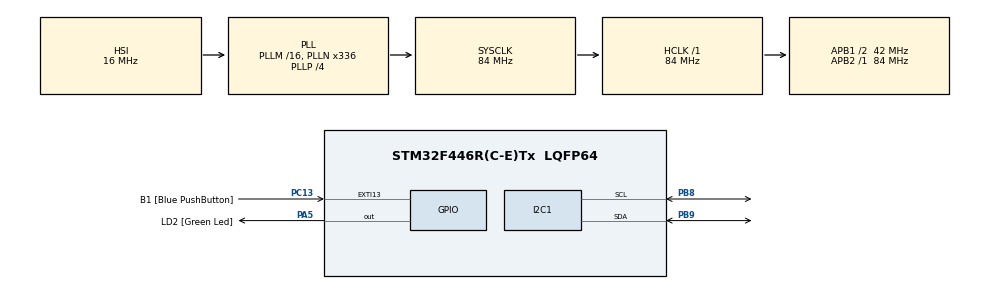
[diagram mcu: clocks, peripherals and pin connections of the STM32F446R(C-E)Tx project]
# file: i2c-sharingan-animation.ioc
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I2C1.I2C_Mode=I2C_Fast
Mcu.Family=STM32F4
Mcu.Name=STM32F446R(C-E)Tx
Mcu.Package=LQFP64
NVIC.PriorityGroup=NVIC_PRIORITYGROUP_0
PA13.GPIO_Label=TMS
PA13.Signal=SYS_JTMS-SWDIO
PA14.GPIO_Label=TCK
PA14.Signal=SYS_JTCK-SWCLK
PA2.GPIO_Label=USART_TX
PA2.Signal=USART2_TX
PA3.GPIO_Label=USART_RX
PA3.Signal=USART2_RX
PA5.GPIO_Label=LD2 [Green Led]
PA5.Signal=GPIO_Output
PB3.GPIO_Label=SWO
PB3.Signal=SYS_JTDO-SWO
PB8.Mode=I2C
PB8.Signal=I2C1_SCL
PB9.Mode=I2C
PB9.Signal=I2C1_SDA
PC13.GPIO_Label=B1 [Blue PushButton]
PC13.GPIO_ModeDefaultEXTI=GPIO_MODE_IT_FALLING
PC13.Signal=GPXTI13
PC14-OSC32_IN.Signal=RCC_OSC32_IN
PC15-OSC32_OUT.Signal=RCC_OSC32_OUT
PH0-OSC_IN.Signal=RCC_OSC_IN
PH1-OSC_OUT.Signal=RCC_OSC_OUT
ProjectManager.HeapSize=0x200
ProjectManager.StackSize=0x400
ProjectManager.TargetToolchain=STM32CubeIDE
RCC.AHBFreq_Value=84000000
RCC.APB1CLKDivider=RCC_HCLK_DIV2
RCC.APB1Freq_Value=42000000
RCC.APB1TimFreq_Value=84000000
RCC.APB2Freq_Value=84000000
RCC.APB2TimFreq_Value=84000000
RCC.CortexFreq_Value=84000000
RCC.FLatency-AdvancedSettings=FLASH_LATENCY_2
RCC.HCLKFreq_Value=84000000
RCC.HSE_VALUE=8000000
RCC.HSI_VALUE=16000000
RCC.LSE_VALUE=32768
RCC.PLLN=336
RCC.PLLP=RCC_PLLP_DIV4
RCC.SYSCLKFreq_VALUE=84000000
RCC.SYSCLKSource=RCC_SYSCLKSOURCE_PLLCLK
RCC.USBFreq_Value=168000000
RCC.VCOOutputFreq_Value=336000000
board=NUCLEO-F446RE

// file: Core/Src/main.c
/* USER CODE BEGIN Header */
/**
  ******************************************************************************
  * @file           : main.c
  * @brief          : Main program body
  ******************************************************************************
  * @attention
  *
  * Copyright (c) 2024 STMicroelectronics.
  * All rights reserved.
  *
  * This software is licensed under terms that can be found in the LICENSE file
  * in the root directory of this software component.
  * If no LICENSE file comes with this software, it is provided AS-IS.
  *
  ******************************************************************************
  */
/* USER CODE END Header */
#include "main.h"
#include "ssd1306.h"

I2C_HandleTypeDef hi2c1;

void SystemClock_Config(void);
static void MX_GPIO_Init(void);
static void MX_I2C1_Init(void);

int main(void)
{

  /* USER CODE BEGIN 1 */
	// 'frame1', 128x64px
	const unsigned char epd_bitmap_frame1 []  = {
		0x00, 0x00, 0x00, 0x00, 0x1f, 0xff, 0xf0, 0x00, 0xff, 0xff, 0xf8, 0x00, 0x00, 0x7f, 0xff, 0x80,
		0x00, 0x00, 0x00, 0x00, 0x1f, 0xff, 0xf0, 0x01, 0xff, 0xff, 0xf8, 0x00, 0x00, 0x7f, 0xff, 0xc0,
		0x00, 0x00, 0x00, 0x00, 0x1f, 0xff, 0xf8, 0x01, 0xff, 0xff, 0xfc, 0x00, 0x00, 0x7f, 0xff, 0xc0,
		0x00, 0x00, 0x00, 0x00, 0x1f, 0xff, 0xf8, 0x01, 0xff, 0xff, 0xfc, 0x00, 0x00, 0x7f, 0xff, 0xc0,
		0x00, 0x00, 0x00, 0x00, 0x1f, 0xff, 0xf8, 0x01, 0xff, 0xff, 0xfc, 0x00, 0x00, 0x7f, 0xff, 0xc0,
		0x00, 0x00, 0x00, 0x00, 0x1f, 0xff, 0xf8, 0x03, 0xff, 0xff, 0xfc, 0x00, 0x00, 0x7f, 0xff, 0xc0,
		0x00, 0x00, 0x00, 0x00, 0x3f, 0xff, 0xf8, 0x03, 0xff, 0xff, 0xfe, 0x00, 0x00, 0xff, 0xff, 0xc0,
		0x00, 0x00, 0x00, 0x00, 0x3f, 0xff, 0xf8, 0x03, 0xff, 0xff, 0xfe, 0x00, 0x00, 0xff, 0xff, 0xc0,
		0x00, 0x00, 0x00, 0x00, 0x3f, 0xfc, 0x78, 0x03, 0xff, 0xff, 0xfe, 0x00, 0x00, 0xff, 0xff, 0xe0,
		0x00, 0x00, 0x00, 0x00, 0x3f, 0xff, 0xc0, 0x07, 0xff, 0xff, 0xfe, 0x00, 0x00, 0xff, 0xff, 0xe0,
		0x00, 0x00, 0x00, 0x00, 0x3f, 0xff, 0xf8, 0x07, 0xff, 0xff, 0xff, 0x00, 0x00, 0xff, 0xff, 0xe0,
		0x00, 0x00, 0x00, 0x00, 0x3f, 0xff, 0xfc, 0x03, 0xff, 0xff, 0xff, 0x00, 0x00, 0xff, 0xff, 0xe0,
		0x00, 0x00, 0x00, 0x00, 0x3f, 0xff, 0xfc, 0x00, 0x7f, 0xff, 0xff, 0x00, 0x00, 0xff, 0xff, 0xe0,
		0x00, 0x00, 0x00, 0x00, 0x7f, 0xff, 0xfc, 0x0e, 0x07, 0xff, 0xff, 0x80, 0x00, 0xff, 0xff, 0xe0,
		0x00, 0x00, 0x00, 0x00, 0x7f, 0xff, 0xfc, 0x0f, 0xc0, 0xff, 0xff, 0x80, 0x00, 0xff, 0xff, 0xf0,
		0x00, 0x00, 0x00, 0x00, 0x7f, 0xff, 0xfc, 0x0f, 0xf0, 0x1f, 0xff, 0x80, 0x00, 0xff, 0xff, 0xf0,
		0x00, 0x00, 0x00, 0x00, 0x7f, 0xff, 0xfc, 0x1f, 0xfe, 0x01, 0xff, 0xc0, 0x00, 0xff, 0xff, 0xf0,
		0x00, 0x00, 0x00, 0x00, 0x7f, 0xf8, 0x00, 0x0f, 0xff, 0xe0, 0x3f, 0xc0, 0x00, 0xff, 0xff, 0xf0,
		0x00, 0x00, 0x00, 0x00, 0x7c, 0x00, 0x00, 0x00, 0x3f, 0xfc, 0x03, 0xc0, 0x00, 0xff, 0xff, 0xf0,
		0x00, 0x00, 0x00, 0x00, 0x40, 0x03, 0xfc, 0x00, 0x03, 0xff, 0x00, 0x00, 0x00, 0xff, 0xff, 0xf0,
		0x00, 0x00, 0x00, 0x00, 0x00, 0xff, 0xf8, 0x00, 0x00, 0x7f, 0xe0, 0x00, 0x00, 0xff, 0xff, 0xf0,
		0x00, 0x00, 0x00, 0x00, 0x1f, 0xff, 0xf8, 0x00, 0x00, 0x1f, 0xfe, 0x00, 0x01, 0xff, 0xff, 0xf8,
		0x00, 0x00, 0x00, 0x00, 0x7f, 0xff, 0xf0, 0x00, 0x00, 0x07, 0xff, 0xc0, 0x01, 0xff, 0xff, 0xf8,
		0x00, 0x00, 0x00, 0x00, 0x7f, 0xff, 0xe0, 0x00, 0x00, 0x01, 0xff, 0xf0, 0x00, 0x0f, 0xff, 0xf8,
		0x00, 0x00, 0x00, 0x00, 0x7f, 0xff, 0xc0, 0x00, 0x00, 0x00, 0x7f, 0xf0, 0x00, 0x1f, 0xff, 0xf8,
		0x00, 0x00, 0x00, 0x00, 0xff, 0xff, 0xc0, 0x00, 0x00, 0x03, 0x1f, 0xf0, 0x00, 0x7f, 0xff, 0xf8,
		0x00, 0x00, 0x00, 0x00, 0xff, 0xff, 0xc0, 0x00, 0x00, 0x01, 0xcf, 0xf8, 0x01, 0xff, 0xff, 0xf8,
		0x00, 0x00, 0x00, 0x00, 0xff, 0xff, 0x80, 0x00, 0x00, 0x01, 0xe7, 0xf8, 0x01, 0xff, 0xff, 0xfc,
		0x00, 0x00, 0x00, 0x00, 0x7f, 0xff, 0x80, 0x00, 0x00, 0x01, 0xf9, 0xfc, 0x01, 0xff, 0xff, 0xfc,
		0x00, 0x00, 0x00, 0x00, 0x7f, 0xff, 0x80, 0x00, 0x00, 0x01, 0xfc, 0xfc, 0x01, 0xff, 0xff, 0xfc,
		0x00, 0x00, 0x00, 0x00, 0xff, 0xff, 0x80, 0x00, 0x00, 0x01, 0xfe, 0x7c, 0x01, 0xff, 0xff, 0xfc,
		0x00, 0x00, 0x00, 0x00, 0xff, 0xff, 0x80, 0x00, 0x00, 0x01, 0xff, 0x3e, 0x01, 0xff, 0xff, 0xfc,
		0x00, 0x00, 0x00, 0x00, 0xff, 0xff, 0x80, 0x00, 0x00, 0x01, 0xff, 0x9e, 0x01, 0xff, 0xff, 0xfe,
		0x00, 0x00, 0x00, 0x00, 0xff, 0xff, 0x80, 0x00, 0x00, 0x01, 0xff, 0xce, 0x01, 0xff, 0xff, 0xfe,
		0x00, 0x00, 0x00, 0x01, 0xff, 0xff, 0xc0, 0x00, 0x00, 0x7f, 0xff, 0xef, 0x01, 0xff, 0xff, 0xfe,
		0x00, 0x00, 0x00, 0x01, 0xff, 0xff, 0xc0, 0x00, 0x00, 0x07, 0xff, 0xe7, 0x01, 0xff, 0xff, 0xfe,
		0x00, 0x00, 0x00, 0x01, 0xff, 0xff, 0xe0, 0x00, 0x00, 0x07, 0xff, 0xf7, 0x83, 0xff, 0xff, 0xff,
		0x00, 0x00, 0x00, 0x01, 0xff, 0xff, 0xe0, 0x00, 0x00, 0x07, 0xff, 0xfb, 0x83, 0xff, 0xff, 0xff,
		0x00, 0x00, 0x00, 0x01, 0xff, 0xff, 0xf0, 0x00, 0x00, 0x0f, 0xff, 0xff, 0x83, 0xff, 0xff, 0xff,
		0x00, 0x00, 0x00, 0x01, 0xfe, 0xff, 0xf8, 0x00, 0x00, 0x1f, 0xff, 0xff, 0xc3, 0xff, 0xff, 0xff,
		0x00, 0x00, 0x00, 0x01, 0xfe, 0x7f, 0xfc, 0x00, 0x00, 0x3f, 0xff, 0xff, 0xc3, 0xff, 0xff, 0xff,
		0x00, 0x00, 0x00, 0x01, 0xff, 0x3f, 0xfe, 0x00, 0x00, 0x7f, 0xff, 0xff, 0xc3, 0xff, 0xff, 0xff,
		0x00, 0x00, 0x00, 0x01, 0xff, 0x8f, 0xff, 0x80, 0x00, 0xff, 0xff, 0xff, 0xe3, 0xff, 0xff, 0xff,
		0x00, 0x00, 0x00, 0x01, 0xff, 0xc0, 0x00, 0x00, 0x07, 0xff, 0xff, 0xff, 0xe3, 0xff, 0xff, 0xff,
		0x00, 0x00, 0x00, 0x01, 0xff, 0xff, 0xff, 0xff, 0xff, 0xff, 0xff, 0xff, 0xf3, 0xff, 0xff, 0xff,
		0x00, 0x00, 0x00, 0x01, 0xff, 0xff, 0xff, 0xff, 0xff, 0xff, 0xff, 0xff, 0xf3, 0xff, 0xff, 0xff,
		0x00, 0x00, 0x00, 0x01, 0xff, 0xff, 0xff, 0xff, 0xff, 0xff, 0xff, 0xff, 0xfb, 0xff, 0xff, 0xff,
		0x00, 0x00, 0x00, 0x01, 0xff, 0xff, 0xff, 0xff, 0xff, 0xff, 0xff, 0xff, 0xfb, 0xff, 0xff, 0xff,
		0x00, 0x00, 0x00, 0x01, 0xff, 0xff, 0xff, 0xff, 0xff, 0xff, 0xff, 0xff, 0xff, 0xff, 0xff, 0xff,
		0x00, 0x00, 0x00, 0x01, 0xff, 0xff, 0xff, 0xff, 0xff, 0xff, 0xff, 0xff, 0xff, 0xff, 0xff, 0xff,
		0x00, 0x00, 0x00, 0x01, 0xff, 0xff, 0xff, 0xff, 0xff, 0xff, 0xff, 0xff, 0xff, 0xff, 0xff, 0xff,
		0x00, 0x00, 0x00, 0x01, 0xff, 0xff, 0xff, 0xff, 0xff, 0xff, 0xff, 0xff, 0xff, 0xff, 0xff, 0xff,
		0x00, 0x00, 0x00, 0x01, 0xff, 0xff, 0xff, 0xff, 0xff, 0xff, 0xff, 0xff, 0xff, 0xff, 0xff, 0xff,
		0x00, 0x00, 0x00, 0x01, 0xff, 0xff, 0xff, 0xff, 0xff, 0xff, 0xff, 0xff, 0xff, 0xff, 0xff, 0xff,
		0x00, 0x00, 0x00, 0x01, 0xff, 0xff, 0xff, 0xff, 0xff, 0xff, 0xff, 0xff, 0xff, 0xff, 0xff, 0xff,
		0x00, 0x00, 0x00, 0x01, 0xff, 0xff, 0xff, 0xff, 0xff, 0xff, 0xff, 0xff, 0xff, 0xff, 0xff, 0xff,
		0x00, 0x00, 0x00, 0x01, 0xff, 0xff, 0xff, 0xff, 0xff, 0xff, 0xff, 0xff, 0xff, 0xff, 0xff, 0xff,
		0x00, 0x00, 0x00, 0x01, 0xff, 0xff, 0xff, 0xff, 0xff, 0xff, 0xff, 0xff, 0xff, 0xff, 0xff, 0xff,
		0x00, 0x00, 0x00, 0x01, 0xff, 0xff, 0xff, 0xff, 0xff, 0xff, 0xff, 0xff, 0xff, 0xff, 0xff, 0xff,
		0x00, 0x00, 0x00, 0x01, 0xff, 0xff, 0xff, 0xff, 0xff, 0xff, 0xff, 0xff, 0xff, 0xff, 0xff, 0xff,
		0x00, 0x00, 0x00, 0x01, 0xff, 0xff, 0xff, 0xff, 0xff, 0xff, 0xff, 0xff, 0xff, 0xff, 0xff, 0xff,
		0x00, 0x00, 0x00, 0x01, 0xff, 0xff, 0xff, 0xff, 0xff, 0xff, 0xff, 0xff, 0xff, 0xff, 0xff, 0xff,
		0x00, 0x00, 0x00, 0x01, 0xff, 0xff, 0xff, 0xff, 0xff, 0xff, 0xff, 0xff, 0xff, 0xff, 0xff, 0xff,
		0x00, 0x00, 0x00, 0x01, 0xff, 0xff, 0xff, 0xff, 0xff, 0xff, 0xff, 0xff, 0xff, 0xff, 0xff, 0xff
	};
	// 'frame2', 128x64px
	const unsigned char epd_bitmap_frame2 []  = {
		0x00, 0x00, 0x00, 0x00, 0x1f, 0xff, 0xf8, 0x00, 0xff, 0xff, 0xfc, 0x00, 0x00, 0x1f, 0xff, 0xf0,
		0x00, 0x00, 0x00, 0x00, 0x1f, 0xff, 0xf8, 0x00, 0xff, 0xff, 0xfc, 0x00, 0x00, 0x1f, 0xff, 0xf0,
		0x00, 0x00, 0x00, 0x00, 0x3f, 0xff, 0xf8, 0x00, 0xff, 0xff, 0xfe, 0x00, 0x00, 0x3f, 0xff, 0xf0,
		0x00, 0x00, 0x00, 0x00, 0x3f, 0xff, 0xf8, 0x01, 0xff, 0xff, 0xfe, 0x00, 0x00, 0x3f, 0xff, 0xf0,
		0x00, 0x00, 0x00, 0x00, 0x3f, 0xff, 0xf8, 0x01, 0xff, 0xff, 0xfe, 0x00, 0x00, 0x3f, 0xff, 0xf0,
		0x00, 0x00, 0x00, 0x00, 0x3f, 0xff, 0xf8, 0x01, 0xff, 0xff, 0xff, 0x00, 0x00, 0x3f, 0xff, 0xf8,
		0x00, 0x00, 0x00, 0x00, 0x3f, 0xff, 0xf8, 0x03, 0xff, 0xff, 0xff, 0x00, 0x00, 0x3f, 0xff, 0xf8,
		0x00, 0x00, 0x00, 0x00, 0x3f, 0xff, 0xf8, 0x03, 0xff, 0xff, 0xff, 0x00, 0x00, 0x3f, 0xff, 0xf8,
		0x00, 0x00, 0x00, 0x00, 0x3f, 0xff, 0xf8, 0x03, 0xff, 0xff, 0xff, 0x80, 0x00, 0x3f, 0xff, 0xf8,
		0x00, 0x00, 0x00, 0x00, 0x3f, 0xfc, 0xf8, 0x03, 0xff, 0xff, 0xff, 0x80, 0x00, 0x3f, 0xff, 0xf8,
		0x00, 0x00, 0x00, 0x00, 0x7f, 0xff, 0x80, 0x07, 0xff, 0xff, 0xff, 0x80, 0x00, 0x3f, 0xff, 0xf8,
		0x00, 0x00, 0x00, 0x00, 0x7f, 0xff, 0xf8, 0x07, 0xff, 0xff, 0xff, 0xc0, 0x00, 0x3f, 0xff, 0xf8,
		0x00, 0x00, 0x00, 0x00, 0x7f, 0xff, 0xfc, 0x07, 0xff, 0xff, 0xff, 0xc0, 0x00, 0x3f, 0xff, 0xfc,
		0x00, 0x00, 0x00, 0x00, 0x7f, 0xff, 0xfc, 0x00, 0x7f, 0xff, 0xff, 0xc0, 0x00, 0x3f, 0xff, 0xfc,
		0x00, 0x00, 0x00, 0x00, 0x7f, 0xff, 0xfc, 0x0c, 0x0f, 0xff, 0xff, 0xc0, 0x00, 0x3f, 0xff, 0xfc,
		0x00, 0x00, 0x00, 0x00, 0x7f, 0xff, 0xfc, 0x0f, 0x80, 0xff, 0xff, 0xe0, 0x00, 0x7f, 0xff, 0xfc,
		0x00, 0x00, 0x00, 0x00, 0x7f, 0xff, 0xfc, 0x0f, 0xf0, 0x1f, 0xff, 0xe0, 0x00, 0x7f, 0xff, 0xfc,
		0x00, 0x00, 0x00, 0x00, 0xff, 0xff, 0xfc, 0x1f, 0xfe, 0x03, 0xff, 0xe0, 0x00, 0x7f, 0xff, 0xfe,
		0x00, 0x00, 0x00, 0x00, 0xff, 0xf0, 0x00, 0x03, 0xff, 0xc0, 0x7f, 0xf0, 0x00, 0x7f, 0xff, 0xfe,
		0x00, 0x00, 0x00, 0x00, 0xf8, 0x00, 0x00, 0x00, 0x0f, 0xf8, 0x07, 0xf0, 0x00, 0x7f, 0xff, 0xfe,
		0x00, 0x00, 0x00, 0x00, 0x00, 0x07, 0xf8, 0x00, 0x01, 0xff, 0x00, 0xf8, 0x00, 0x7f, 0xff, 0xfe,
		0x00, 0x00, 0x00, 0x00, 0x01, 0xff, 0xf0, 0x00, 0x00, 0x3f, 0xc0, 0x00, 0x00, 0x7f, 0xff, 0xfe,
		0x00, 0x00, 0x00, 0x00, 0x3f, 0xff, 0xf0, 0x00, 0x00, 0x07, 0xfc, 0x00, 0x00, 0x7f, 0xff, 0xfe,
		0x00, 0x00, 0x00, 0x00, 0xff, 0xff, 0xe0, 0x00, 0x00, 0x01, 0xff, 0x80, 0x00, 0x7f, 0xff, 0xff,
		0x00, 0x00, 0x00, 0x00, 0xff, 0xff, 0xc0, 0x00, 0x00, 0x00, 0x7f, 0xf0, 0x00, 0x7f, 0xff, 0xff,
		0x00, 0x00, 0x00, 0x00, 0xff, 0xff, 0xc0, 0x00, 0x00, 0x00, 0x3f, 0xfc, 0x00, 0x0f, 0xff, 0xff,
		0x00, 0x00, 0x00, 0x00, 0xff, 0xff, 0xc0, 0x00, 0x00, 0x01, 0x8f, 0xfc, 0x00, 0x1f, 0xff, 0xff,
		0x00, 0x00, 0x00, 0x00, 0xff, 0xff, 0x80, 0x00, 0x00, 0x00, 0xe7, 0xfe, 0x00, 0x7f, 0xff, 0xff,
		0x00, 0x00, 0x00, 0x00, 0x7f, 0xff, 0x80, 0x00, 0x00, 0x00, 0xf1, 0xfe, 0x00, 0x7f, 0xff, 0xff,
		0x00, 0x00, 0x00, 0x01, 0x7f, 0xff, 0x80, 0x00, 0x00, 0x00, 0xf8, 0xfe, 0x00, 0x7f, 0xff, 0xff,
		0x00, 0x00, 0x00, 0x01, 0xff, 0xff, 0x80, 0x00, 0x00, 0x00, 0xfe, 0x7f, 0x00, 0x7f, 0xff, 0xff,
		0x00, 0x00, 0x00, 0x01, 0xff, 0xff, 0x80, 0x00, 0x00, 0x00, 0xff, 0x3f, 0x00, 0x7f, 0xff, 0xff,
		0x00, 0x00, 0x00, 0x01, 0xff, 0xff, 0x80, 0x00, 0x00, 0x00, 0xff, 0x9f, 0x80, 0x7f, 0xff, 0xff,
		0x00, 0x00, 0x00, 0x01, 0xff, 0xff, 0x80, 0x00, 0x00, 0x00, 0xff, 0xcf, 0x80, 0x7f, 0xff, 0xff,
		0x00, 0x00, 0x00, 0x01, 0xff, 0xff, 0xc0, 0x00, 0x00, 0x01, 0xff, 0xe7, 0x80, 0xff, 0xff, 0xff,
		0x00, 0x00, 0x00, 0x01, 0xff, 0xff, 0xc0, 0x00, 0x01, 0xff, 0xff, 0xf7, 0xc0, 0xff, 0xff, 0xff,
		0x00, 0x00, 0x00, 0x01, 0xff, 0xff, 0xe0, 0x00, 0x00, 0x03, 0xff, 0xff, 0xc0, 0xff, 0xff, 0xff,
		0x00, 0x00, 0x00, 0x03, 0xff, 0xff, 0xe0, 0x00, 0x00, 0x03, 0xff, 0xfb, 0xe0, 0xff, 0xff, 0xff,
		0x00, 0x00, 0x00, 0x03, 0xfd, 0xff, 0xf0, 0x00, 0x00, 0x07, 0xff, 0xff, 0xe0, 0xff, 0xff, 0xff,
		0x00, 0x00, 0x00, 0x03, 0xfe, 0xff, 0xf8, 0x00, 0x00, 0x0f, 0xff, 0xff, 0xe0, 0xff, 0xff, 0xff,
		0x00, 0x00, 0x00, 0x03, 0xfe, 0x7f, 0xfc, 0x00, 0x00, 0x1f, 0xff, 0xff, 0xf0, 0xff, 0xff, 0xff,
		0x00, 0x00, 0x00, 0x03, 0xff, 0x3f, 0xfe, 0x00, 0x00, 0x3f, 0xff, 0xff, 0xf0, 0xff, 0xff, 0xff,
		0x00, 0x00, 0x00, 0x03, 0xff, 0x8f, 0xff, 0x80, 0x00, 0x7f, 0xff, 0xff, 0xf8, 0xff, 0xff, 0xff,
		0x00, 0x00, 0x00, 0x03, 0xff, 0xc0, 0x00, 0x00, 0x00, 0xff, 0xff, 0xff, 0xf8, 0xff, 0xff, 0xff,
		0x00, 0x00, 0x00, 0x03, 0xff, 0xff, 0xff, 0xff, 0xff, 0xff, 0xff, 0xff, 0xf8, 0xff, 0xff, 0xff,
		0x00, 0x00, 0x00, 0x03, 0xff, 0xff, 0xff, 0xff, 0xff, 0xff, 0xff, 0xff, 0xfc, 0xff, 0xff, 0xff,
		0x00, 0x00, 0x00, 0x03, 0xff, 0xff, 0xff, 0xff, 0xff, 0xff, 0xff, 0xff, 0xfc, 0xff, 0xff, 0xff,
		0x00, 0x00, 0x00, 0x03, 0xff, 0xff, 0xff, 0xff, 0xff, 0xff, 0xff, 0xff, 0xfc, 0xff, 0xff, 0xff,
		0x00, 0x00, 0x00, 0x03, 0xff, 0xff, 0xff, 0xff, 0xff, 0xff, 0xff, 0xff, 0xfe, 0xff, 0xff, 0xff,
		0x00, 0x00, 0x00, 0x03, 0xff, 0xff, 0xff, 0xff, 0xff, 0xff, 0xff, 0xff, 0xff, 0xff, 0xff, 0xff,
		0x00, 0x00, 0x00, 0x03, 0xff, 0xff, 0xff, 0xff, 0xff, 0xff, 0xff, 0xff, 0xff, 0xff, 0xff, 0xff,
		0x00, 0x00, 0x00, 0x03, 0xff, 0xff, 0xff, 0xff, 0xff, 0xff, 0xff, 0xff, 0xff, 0xff, 0xff, 0xff,
		0x00, 0x00, 0x00, 0x03, 0xff, 0xff, 0xff, 0xff, 0xff, 0xff, 0xff, 0xff, 0xff, 0xff, 0xff, 0xff,
		0x00, 0x00, 0x00, 0x03, 0xff, 0xff, 0xff, 0xff, 0xff, 0xff, 0xff, 0xff, 0xff, 0xff, 0xff, 0xff,
		0x00, 0x00, 0x00, 0x03, 0xff, 0xff, 0xff, 0xff, 0xff, 0xff, 0xff, 0xff, 0xff, 0xff, 0xff, 0xff,
		0x00, 0x00, 0x00, 0x03, 0xff, 0xff, 0xff, 0xff, 0xff, 0xff, 0xff, 0xff, 0xff, 0xff, 0xff, 0xff,
		0x00, 0x00, 0x00, 0x03, 0xff, 0xff, 0xff, 0xff, 0xff, 0xff, 0xff, 0xff, 0xff, 0xff, 0xff, 0xff,
		0x00, 0x00, 0x00, 0x03, 0xff, 0xff, 0xff, 0xff, 0xff, 0xff, 0xff, 0xff, 0xff, 0xff, 0xff, 0xff,
		0x00, 0x00, 0x00, 0x03, 0xff, 0xff, 0xff, 0xff, 0xff, 0xff, 0xff, 0xff, 0xff, 0xff, 0xff, 0xff,
		0x00, 0x00, 0x00, 0x03, 0xff, 0xff, 0xff, 0xff, 0xff, 0xff, 0xff, 0xff, 0xff, 0xff, 0xff, 0xff,
		0x00, 0x00, 0x00, 0x03, 0xff, 0xff, 0xff, 0xff, 0xff, 0xff, 0xff, 0xff, 0xff, 0xff, 0xff, 0xff,
		0x00, 0x00, 0x00, 0x03, 0xff, 0xff, 0xff, 0xff, 0xff, 0xff, 0xff, 0xff, 0xff, 0xff, 0xff, 0xff,
		0x00, 0x00, 0x00, 0x03, 0xff, 0xff, 0xff, 0xff, 0xff, 0xff, 0xff, 0xff, 0xff, 0xff, 0xff, 0xff,
		0x00, 0x00, 0x00, 0x03, 0xff, 0xff, 0xff, 0xff, 0xff, 0xff, 0xff, 0xff, 0xff, 0xff, 0xff, 0xff
	};
	// 'frame3', 128x64px
	const unsigned char epd_bitmap_frame3 []  = {
		0x00, 0x00, 0x00, 0x00, 0x1f, 0xff, 0xf8, 0x00, 0xff, 0xff, 0xfc, 0x00, 0x00, 0x1f, 0xff, 0xf0,
		0x00, 0x00, 0x00, 0x00, 0x1f, 0xff, 0xf8, 0x00, 0xff, 0xff, 0xfe, 0x00, 0x00, 0x1f, 0xff, 0xf0,
		0x00, 0x00, 0x00, 0x00, 0x3f, 0xff, 0xf8, 0x00, 0xff, 0xff, 0xfe, 0x00, 0x00, 0x1f, 0xff, 0xf0,
		0x00, 0x00, 0x00, 0x00, 0x3f, 0xff, 0xf8, 0x01, 0xff, 0xff, 0xfe, 0x00, 0x00, 0x3f, 0xff, 0xf0,
		0x00, 0x00, 0x00, 0x00, 0x3f, 0xff, 0xf8, 0x01, 0xff, 0xff, 0xff, 0x00, 0x00, 0x3f, 0xff, 0xf0,
		0x00, 0x00, 0x00, 0x00, 0x3f, 0xff, 0xf8, 0x01, 0xff, 0xff, 0xff, 0x00, 0x00, 0x3f, 0xff, 0xf8,
		0x00, 0x00, 0x00, 0x00, 0x3f, 0xff, 0xf8, 0x03, 0xff, 0xff, 0xff, 0x00, 0x00, 0x3f, 0xff, 0xf8,
		0x00, 0x00, 0x00, 0x00, 0x3f, 0xff, 0xf8, 0x03, 0xff, 0xff, 0xff, 0x00, 0x00, 0x3f, 0xff, 0xf8,
		0x00, 0x00, 0x00, 0x00, 0x3f, 0xff, 0xf8, 0x03, 0xff, 0xff, 0xff, 0x80, 0x00, 0x3f, 0xff, 0xf8,
		0x00, 0x00, 0x00, 0x00, 0x3f, 0xfc, 0x7c, 0x03, 0xff, 0xff, 0xff, 0x80, 0x00, 0x3f, 0xff, 0xf8,
		0x00, 0x00, 0x00, 0x00, 0x7f, 0xff, 0x80, 0x07, 0xff, 0xff, 0xff, 0x80, 0x00, 0x3f, 0xff, 0xf8,
		0x00, 0x00, 0x00, 0x00, 0x7f, 0xff, 0xf8, 0x07, 0xff, 0xff, 0xff, 0xc0, 0x00, 0x3f, 0xff, 0xfc,
		0x00, 0x00, 0x00, 0x00, 0x7f, 0xff, 0xfc, 0x03, 0xff, 0xff, 0xff, 0xc0, 0x00, 0x3f, 0xff, 0xfc,
		0x00, 0x00, 0x00, 0x00, 0x7f, 0xff, 0xfc, 0x00, 0x7f, 0xff, 0xff, 0xc0, 0x00, 0x3f, 0xff, 0xfc,
		0x00, 0x00, 0x00, 0x00, 0x7f, 0xff, 0xfc, 0x0e, 0x07, 0xff, 0xff, 0xe0, 0x00, 0x3f, 0xff, 0xfc,
		0x00, 0x00, 0x00, 0x00, 0x7f, 0xff, 0xfc, 0x0f, 0x80, 0xff, 0xff, 0xe0, 0x00, 0x3f, 0xff, 0xfc,
		0x00, 0x00, 0x00, 0x00, 0x7f, 0xff, 0xfc, 0x0f, 0xf0, 0x1f, 0xff, 0xe0, 0x00, 0x7f, 0xff, 0xfc,
		0x00, 0x00, 0x00, 0x00, 0x7f, 0xff, 0xfc, 0x1f, 0xfe, 0x03, 0xff, 0xf0, 0x00, 0x7f, 0xff, 0xfe,
		0x00, 0x00, 0x00, 0x00, 0xff, 0xf0, 0x00, 0x01, 0xff, 0xc0, 0x7f, 0xf0, 0x00, 0x7f, 0xff, 0xfe,
		0x00, 0x00, 0x00, 0x00, 0xf8, 0x00, 0x00, 0x00, 0x0f, 0xf8, 0x07, 0xf0, 0x00, 0x7f, 0xff, 0xfe,
		0x00, 0x00, 0x00, 0x00, 0x00, 0x07, 0xf8, 0x00, 0x00, 0xff, 0x00, 0xf8, 0x00, 0x7f, 0xff, 0xfe,
		0x00, 0x00, 0x00, 0x00, 0x03, 0xff, 0xf0, 0x00, 0x00, 0x3f, 0xe0, 0x00, 0x00, 0x7f, 0xff, 0xfe,
		0x00, 0x00, 0x00, 0x00, 0x3f, 0xff, 0xf0, 0x00, 0x00, 0x07, 0xfc, 0x00, 0x00, 0x7f, 0xff, 0xfe,
		0x00, 0x00, 0x00, 0x00, 0xff, 0xff, 0xe0, 0x00, 0x00, 0x01, 0xff, 0x80, 0x00, 0x7f, 0xff, 0xff,
		0x00, 0x00, 0x00, 0x00, 0xff, 0xff, 0xc0, 0x00, 0x00, 0x00, 0x7f, 0xf0, 0x00, 0x7f, 0xff, 0xff,
		0x00, 0x00, 0x00, 0x00, 0xff, 0xff, 0xc0, 0x00, 0x00, 0x00, 0x3f, 0xfc, 0x00, 0x0f, 0xff, 0xff,
		0x00, 0x00, 0x00, 0x00, 0xff, 0xff, 0xc0, 0x00, 0x00, 0x01, 0x8f, 0xfc, 0x00, 0x1f, 0xff, 0xff,
		0x00, 0x00, 0x00, 0x00, 0xff, 0xff, 0x80, 0x00, 0x00, 0x00, 0xe3, 0xfe, 0x00, 0x7f, 0xff, 0xff,
		0x00, 0x00, 0x00, 0x00, 0x7f, 0xff, 0x80, 0x00, 0x00, 0x00, 0xf1, 0xfe, 0x00, 0x7f, 0xff, 0xff,
		0x00, 0x00, 0x00, 0x01, 0x7f, 0xff, 0x80, 0x00, 0x00, 0x00, 0xf8, 0xfe, 0x00, 0x7f, 0xff, 0xff,
		0x00, 0x00, 0x00, 0x01, 0xff, 0xff, 0x80, 0x00, 0x00, 0x00, 0xfe, 0x7f, 0x00, 0x7f, 0xff, 0xff,
		0x00, 0x00, 0x00, 0x01, 0xff, 0xff, 0x80, 0x00, 0x00, 0x00, 0xff, 0x3f, 0x00, 0x7f, 0xff, 0xff,
		0x00, 0x00, 0x00, 0x01, 0xff, 0xff, 0x80, 0x00, 0x00, 0x00, 0xff, 0x9f, 0x80, 0x7f, 0xff, 0xff,
		0x00, 0x00, 0x00, 0x01, 0xff, 0xff, 0x80, 0x00, 0x00, 0x00, 0xff, 0xcf, 0x80, 0x7f, 0xff, 0xff,
		0x00, 0x00, 0x00, 0x01, 0xff, 0xff, 0xc0, 0x00, 0x00, 0x01, 0xff, 0xe7, 0x80, 0xff, 0xff, 0xff,
		0x00, 0x00, 0x00, 0x01, 0xff, 0xff, 0xc0, 0x00, 0x01, 0xff, 0xff, 0xf7, 0xc0, 0xff, 0xff, 0xff,
		0x00, 0x00, 0x00, 0x01, 0xff, 0xff, 0xe0, 0x00, 0x00, 0x03, 0xff, 0xff, 0xc0, 0xff, 0xff, 0xff,
		0x00, 0x00, 0x00, 0x01, 0xff, 0xff, 0xe0, 0x00, 0x00, 0x03, 0xff, 0xfb, 0xe0, 0xff, 0xff, 0xff,
		0x00, 0x00, 0x00, 0x03, 0xfd, 0xff, 0xf0, 0x00, 0x00, 0x07, 0xff, 0xff, 0xe0, 0xff, 0xff, 0xff,
		0x00, 0x00, 0x00, 0x03, 0xfe, 0xff, 0xf8, 0x00, 0x00, 0x0f, 0xff, 0xff, 0xe0, 0xff, 0xff, 0xff,
		0x00, 0x00, 0x00, 0x03, 0xfe, 0x7f, 0xfc, 0x00, 0x00, 0x1f, 0xff, 0xff, 0xf0, 0xff, 0xff, 0xff,
		0x00, 0x00, 0x00, 0x03, 0xff, 0x3f, 0xfe, 0x00, 0x00, 0x3f, 0xff, 0xff, 0xf0, 0xff, 0xff, 0xff,
		0x00, 0x00, 0x00, 0x03, 0xff, 0x8f, 0xff, 0x80, 0x00, 0x7f, 0xff, 0xff, 0xf8, 0xff, 0xff, 0xff,
		0x00, 0x00, 0x00, 0x03, 0xff, 0xc0, 0x00, 0x00, 0x00, 0xff, 0xff, 0xff, 0xf8, 0xff, 0xff, 0xff,
		0x00, 0x00, 0x00, 0x03, 0xff, 0xf8, 0x01, 0xff, 0xff, 0xff, 0xff, 0xff, 0xf8, 0xff, 0xff, 0xff,
		0x00, 0x00, 0x00, 0x03, 0xff, 0xff, 0xff, 0xff, 0xff, 0xff, 0xff, 0xff, 0xfc, 0xff, 0xff, 0xff,
		0x00, 0x00, 0x00, 0x03, 0xff, 0xff, 0xff, 0xff, 0xff, 0xff, 0xff, 0xff, 0xfc, 0xff, 0xff, 0xff,
		0x00, 0x00, 0x00, 0x03, 0xff, 0xff, 0xff, 0xff, 0xff, 0xff, 0xff, 0xff, 0xfe, 0xff, 0xff, 0xff,
		0x00, 0x00, 0x00, 0x03, 0xff, 0xff, 0xff, 0xff, 0xff, 0xff, 0xff, 0xff, 0xfe, 0xff, 0xff, 0xff,
		0x00, 0x00, 0x00, 0x03, 0xff, 0xff, 0xff, 0xff, 0xff, 0xff, 0xff, 0xff, 0xff, 0xff, 0xff, 0xff,
		0x00, 0x00, 0x00, 0x03, 0xff, 0xff, 0xff, 0xff, 0xff, 0xff, 0xff, 0xff, 0xff, 0xff, 0xff, 0xff,
		0x00, 0x00, 0x00, 0x03, 0xff, 0xff, 0xff, 0xff, 0xff, 0xff, 0xff, 0xff, 0xff, 0xff, 0xff, 0xff,
		0x00, 0x00, 0x00, 0x03, 0xff, 0xff, 0xff, 0xff, 0xff, 0xff, 0xff, 0xff, 0xff, 0xff, 0xff, 0xff,
		0x00, 0x00, 0x00, 0x03, 0xff, 0xff, 0xff, 0xff, 0xff, 0xff, 0xff, 0xff, 0xff, 0xff, 0xff, 0xff,
		0x00, 0x00, 0x00, 0x03, 0xff, 0xff, 0xff, 0xff, 0xff, 0xff, 0xff, 0xff, 0xff, 0xff, 0xff, 0xff,
		0x00, 0x00, 0x00, 0x03, 0xff, 0xff, 0xff, 0xff, 0xff, 0xff, 0xff, 0xff, 0xff, 0xff, 0xff, 0xff,
		0x00, 0x00, 0x00, 0x03, 0xff, 0xff, 0xff, 0xff, 0xff, 0xff, 0xff, 0xff, 0xff, 0xff, 0xff, 0xff,
		0x00, 0x00, 0x00, 0x03, 0xff, 0xff, 0xff, 0xff, 0xff, 0xff, 0xff, 0xff, 0xff, 0xff, 0xff, 0xff,
		0x00, 0x00, 0x00, 0x03, 0xff, 0xff, 0xff, 0xff, 0xff, 0xff, 0xff, 0xff, 0xff, 0xff, 0xff, 0xff,
		0x00, 0x00, 0x00, 0x03, 0xff, 0xff, 0xff, 0xff, 0xff, 0xff, 0xff, 0xff, 0xff, 0xff, 0xff, 0xff,
		0x00, 0x00, 0x00, 0x03, 0xff, 0xff, 0xff, 0xff, 0xff, 0xff, 0xff, 0xff, 0xff, 0xff, 0xff, 0xff,
		0x00, 0x00, 0x00, 0x03, 0xff, 0xff, 0xff, 0xff, 0xff, 0xff, 0xff, 0xff, 0xff, 0xff, 0xff, 0xff,
		0x00, 0x00, 0x00, 0x03, 0xff, 0xff, 0xff, 0xff, 0xff, 0xff, 0xff, 0xff, 0xff, 0xff, 0xff, 0xff,
		0x00, 0x00, 0x00, 0x03, 0xff, 0xff, 0xff, 0xff, 0xff, 0xff, 0xff, 0xff, 0xff, 0xff, 0xff, 0xff
	};
	// 'frame4', 128x64px
	const unsigned char epd_bitmap_frame4 []  = {
		0x00, 0x00, 0x00, 0x00, 0x1f, 0xff, 0xf8, 0x00, 0xff, 0xff, 0xfc, 0x00, 0x00, 0x1f, 0xff, 0xf0,
		0x00, 0x00, 0x00, 0x00, 0x3f, 0xff, 0xf8, 0x00, 0xff, 0xff, 0xfe, 0x00, 0x00, 0x1f, 0xff, 0xf8,
		0x00, 0x00, 0x00, 0x00, 0x3f, 0xff, 0xf8, 0x01, 0xff, 0xff, 0xfe, 0x00, 0x00, 0x1f, 0xff, 0xf8,
		0x00, 0x00, 0x00, 0x00, 0x3f, 0xff, 0xf8, 0x01, 0xff, 0xff, 0xfe, 0x00, 0x00, 0x1f, 0xff, 0xf8,
		0x00, 0x00, 0x00, 0x00, 0x3f, 0xff, 0xf8, 0x01, 0xff, 0xff, 0xff, 0x00, 0x00, 0x1f, 0xff, 0xf8,
		0x00, 0x00, 0x00, 0x00, 0x3f, 0xff, 0xf8, 0x01, 0xff, 0xff, 0xff, 0x00, 0x00, 0x1f, 0xff, 0xf8,
		0x00, 0x00, 0x00, 0x00, 0x3f, 0xff, 0xf8, 0x03, 0xff, 0xff, 0xff, 0x00, 0x00, 0x1f, 0xff, 0xf8,
		0x00, 0x00, 0x00, 0x00, 0x3f, 0xff, 0xf8, 0x03, 0xff, 0xff, 0xff, 0x80, 0x00, 0x1f, 0xff, 0xf8,
		0x00, 0x00, 0x00, 0x00, 0x7f, 0xff, 0xf8, 0x03, 0xff, 0xff, 0xff, 0x80, 0x00, 0x3f, 0xff, 0xfc,
		0x00, 0x00, 0x00, 0x00, 0x7f, 0xfe, 0x38, 0x03, 0xff, 0xff, 0xff, 0x80, 0x00, 0x3f, 0xff, 0xfc,
		0x00, 0x00, 0x00, 0x00, 0x7f, 0xff, 0xc0, 0x07, 0xff, 0xff, 0xff, 0xc0, 0x00, 0x3f, 0xff, 0xfc,
		0x00, 0x00, 0x00, 0x00, 0x7f, 0xff, 0xf8, 0x07, 0xff, 0xff, 0xff, 0xc0, 0x00, 0x3f, 0xff, 0xfc,
		0x00, 0x00, 0x00, 0x00, 0x7f, 0xff, 0xfc, 0x03, 0xff, 0xff, 0xff, 0xc0, 0x00, 0x3f, 0xff, 0xfc,
		0x00, 0x00, 0x00, 0x00, 0x7f, 0xff, 0xfc, 0x00, 0x3f, 0xff, 0xff, 0xc0, 0x00, 0x3f, 0xff, 0xfc,
		0x00, 0x00, 0x00, 0x00, 0x7f, 0xff, 0xfc, 0x0e, 0x07, 0xff, 0xff, 0xe0, 0x00, 0x3f, 0xff, 0xfe,
		0x00, 0x00, 0x00, 0x00, 0x7f, 0xff, 0xfc, 0x0f, 0xc0, 0xff, 0xff, 0xe0, 0x00, 0x3f, 0xff, 0xfe,
		0x00, 0x00, 0x00, 0x00, 0xff, 0xff, 0xfc, 0x0f, 0xf8, 0x1f, 0xff, 0xe0, 0x00, 0x3f, 0xff, 0xfe,
		0x00, 0x00, 0x00, 0x00, 0xff, 0xff, 0xfc, 0x1f, 0xff, 0x01, 0xff, 0xf0, 0x00, 0x3f, 0xff, 0xfe,
		0x00, 0x00, 0x00, 0x00, 0xff, 0xe0, 0x00, 0x01, 0xff, 0xe0, 0x3f, 0xf0, 0x00, 0x3f, 0xff, 0xfe,
		0x00, 0x00, 0x00, 0x00, 0xf0, 0x00, 0x00, 0x00, 0x0f, 0xfc, 0x07, 0xf8, 0x00, 0x3f, 0xff, 0xfe,
		0x00, 0x00, 0x00, 0x00, 0x00, 0x0f, 0xf8, 0x00, 0x00, 0xff, 0x00, 0x78, 0x00, 0x3f, 0xff, 0xff,
		0x00, 0x00, 0x00, 0x00, 0x03, 0xff, 0xf0, 0x00, 0x00, 0x1f, 0xe0, 0x00, 0x00, 0x3f, 0xff, 0xff,
		0x00, 0x00, 0x00, 0x00, 0x7f, 0xff, 0xf0, 0x00, 0x00, 0x07, 0xfc, 0x00, 0x00, 0x7f, 0xff, 0xff,
		0x00, 0x00, 0x00, 0x00, 0xff, 0xff, 0xe0, 0x00, 0x00, 0x01, 0xff, 0x80, 0x00, 0x7f, 0xff, 0xff,
		0x00, 0x00, 0x00, 0x01, 0xff, 0xff, 0xc0, 0x00, 0x00, 0x00, 0x7f, 0xf0, 0x00, 0x7f, 0xff, 0xff,
		0x00, 0x00, 0x00, 0x00, 0xff, 0xff, 0xc0, 0x00, 0x00, 0x00, 0x1f, 0xfc, 0x00, 0x0f, 0xff, 0xff,
		0x00, 0x00, 0x00, 0x00, 0xff, 0xff, 0xc0, 0x00, 0x00, 0x00, 0x8f, 0xfe, 0x00, 0x1f, 0xff, 0xff,
		0x00, 0x00, 0x00, 0x00, 0xff, 0xff, 0x80, 0x00, 0x00, 0x00, 0xe3, 0xfe, 0x00, 0x7f, 0xff, 0xff,
		0x00, 0x00, 0x00, 0x00, 0xff, 0xff, 0x80, 0x00, 0x00, 0x00, 0xf1, 0xfe, 0x00, 0x7f, 0xff, 0xff,
		0x00, 0x00, 0x00, 0x01, 0x7f, 0xff, 0x80, 0x00, 0x00, 0x00, 0xfc, 0xff, 0x00, 0x7f, 0xff, 0xff,
		0x00, 0x00, 0x00, 0x01, 0x7f, 0xff, 0x80, 0x00, 0x00, 0x00, 0xfe, 0x7f, 0x00, 0x7f, 0xff, 0xff,
		0x00, 0x00, 0x00, 0x01, 0xff, 0xff, 0x80, 0x00, 0x00, 0x00, 0xff, 0x1f, 0x80, 0x7f, 0xff, 0xff,
		0x00, 0x00, 0x00, 0x01, 0xff, 0xff, 0x80, 0x00, 0x00, 0x00, 0xff, 0x8f, 0x80, 0x7f, 0xff, 0xff,
		0x00, 0x00, 0x00, 0x01, 0xff, 0xff, 0x80, 0x00, 0x00, 0x00, 0xff, 0xc7, 0x80, 0x7f, 0xff, 0xff,
		0x00, 0x00, 0x00, 0x03, 0xff, 0xff, 0xc0, 0x00, 0x00, 0x01, 0xff, 0xe7, 0xc0, 0x7f, 0xff, 0xff,
		0x00, 0x00, 0x00, 0x03, 0xff, 0xff, 0xc0, 0x00, 0x01, 0xff, 0xff, 0xf7, 0xc0, 0x7f, 0xff, 0xff,
		0x00, 0x00, 0x00, 0x03, 0xff, 0xff, 0xe0, 0x00, 0x00, 0x01, 0xff, 0xfb, 0xc0, 0x7f, 0xff, 0xff,
		0x00, 0x00, 0x00, 0x03, 0xff, 0xff, 0xe0, 0x00, 0x00, 0x03, 0xff, 0xff, 0xe0, 0x7f, 0xff, 0xff,
		0x00, 0x00, 0x00, 0x03, 0xfd, 0xff, 0xf0, 0x00, 0x00, 0x07, 0xff, 0xfd, 0xe0, 0x7f, 0xff, 0xff,
		0x00, 0x00, 0x00, 0x03, 0xfc, 0xff, 0xf8, 0x00, 0x00, 0x07, 0xff, 0xff, 0xf0, 0xff, 0xff, 0xff,
		0x00, 0x00, 0x00, 0x03, 0xfe, 0x7f, 0xfc, 0x00, 0x00, 0x0f, 0xff, 0xff, 0xf0, 0xff, 0xff, 0xff,
		0x00, 0x00, 0x00, 0x03, 0xff, 0x3f, 0xfe, 0x00, 0x00, 0x1f, 0xff, 0xff, 0xf0, 0xff, 0xff, 0xff,
		0x00, 0x00, 0x00, 0x03, 0xff, 0x8f, 0xff, 0x80, 0x00, 0x7f, 0xff, 0xff, 0xf8, 0xff, 0xff, 0xff,
		0x00, 0x00, 0x00, 0x03, 0xff, 0x80, 0x01, 0xc0, 0x00, 0xff, 0xff, 0xff, 0xf8, 0xff, 0xff, 0xff,
		0x00, 0x00, 0x00, 0x03, 0xff, 0xf0, 0x00, 0x7f, 0xff, 0xff, 0xff, 0xff, 0xfc, 0xff, 0xff, 0xff,
		0x00, 0x00, 0x00, 0x03, 0xff, 0xff, 0xff, 0xff, 0xff, 0xff, 0xff, 0xff, 0xfc, 0xff, 0xff, 0xff,
		0x00, 0x00, 0x00, 0x03, 0xff, 0xff, 0xff, 0xff, 0xff, 0xff, 0xff, 0xff, 0xfe, 0xff, 0xff, 0xff,
		0x00, 0x00, 0x00, 0x03, 0xff, 0xff, 0xff, 0xff, 0xff, 0xff, 0xff, 0xff, 0xfe, 0xff, 0xff, 0xff,
		0x00, 0x00, 0x00, 0x03, 0xff, 0xff, 0xff, 0xff, 0xff, 0xff, 0xff, 0xff, 0xfe, 0x7f, 0xff, 0xff,
		0x00, 0x00, 0x00, 0x03, 0xff, 0xff, 0xff, 0xff, 0xff, 0xff, 0xff, 0xff, 0xff, 0xff, 0xff, 0xff,
		0x00, 0x00, 0x00, 0x03, 0xff, 0xff, 0xff, 0xff, 0xff, 0xff, 0xff, 0xff, 0xff, 0xff, 0xff, 0xff,
		0x00, 0x00, 0x00, 0x03, 0xff, 0xff, 0xff, 0xff, 0xff, 0xff, 0xff, 0xff, 0xff, 0xff, 0xff, 0xff,
		0x00, 0x00, 0x00, 0x03, 0xff, 0xff, 0xff, 0xff, 0xff, 0xff, 0xff, 0xff, 0xff, 0xff, 0xff, 0xff,
		0x00, 0x00, 0x00, 0x03, 0xff, 0xff, 0xff, 0xff, 0xff, 0xff, 0xff, 0xff, 0xff, 0xff, 0xff, 0xff,
		0x00, 0x00, 0x00, 0x03, 0xff, 0xff, 0xff, 0xff, 0xff, 0xff, 0xff, 0xff, 0xff, 0xff, 0xff, 0xff,
		0x00, 0x00, 0x00, 0x03, 0xff, 0xff, 0xff, 0xff, 0xff, 0xff, 0xff, 0xff, 0xff, 0xff, 0xff, 0xff,
		0x00, 0x00, 0x00, 0x03, 0xff, 0xff, 0xff, 0xff, 0xff, 0xff, 0xff, 0xff, 0xff, 0xff, 0xff, 0xff,
		0x00, 0x00, 0x00, 0x03, 0xff, 0xff, 0xff, 0xff, 0xff, 0xff, 0xff, 0xff, 0xff, 0xff, 0xff, 0xff,
		0x00, 0x00, 0x00, 0x03, 0xff, 0xff, 0xff, 0xff, 0xff, 0xff, 0xff, 0xff, 0xff, 0xff, 0xff, 0xff,
		0x00, 0x00, 0x00, 0x03, 0xff, 0xff, 0xff, 0xff, 0xff, 0xff, 0xff, 0xff, 0xff, 0xff, 0xff, 0xff,
		0x00, 0x00, 0x00, 0x03, 0xff, 0xff, 0xff, 0xff, 0xff, 0xff, 0xff, 0xff, 0xff, 0xff, 0xff, 0xff,
		0x00, 0x00, 0x00, 0x03, 0xff, 0xff, 0xff, 0xff, 0xff, 0xff, 0xff, 0xff, 0xff, 0xff, 0xff, 0xff,
		0x00, 0x00, 0x00, 0x03, 0xff, 0xff, 0xff, 0xff, 0xff, 0xff, 0xff, 0xff, 0xff, 0xff, 0xff, 0xff,
		0x00, 0x00, 0x00, 0x03, 0xff, 0xff, 0xff, 0xff, 0xff, 0xff, 0xff, 0xff, 0xff, 0xff, 0xff, 0xff
	};
	// 'frame5', 128x64px
	const unsigned char epd_bitmap_frame5 []  = {
		0x00, 0x00, 0x00, 0x00, 0x1f, 0xff, 0xf8, 0x00, 0xff, 0xff, 0xfe, 0x00, 0x00, 0x0f, 0xff, 0xf8,
		0x00, 0x00, 0x00, 0x00, 0x3f, 0xff, 0xf8, 0x00, 0xff, 0xff, 0xfe, 0x00, 0x00, 0x0f, 0xff, 0xf8,
		0x00, 0x00, 0x00, 0x00, 0x3f, 0xff, 0xf8, 0x00, 0xff, 0xff, 0xff, 0x00, 0x00, 0x1f, 0xff, 0xf8,
		0x00, 0x00, 0x00, 0x00, 0x3f, 0xff, 0xf8, 0x01, 0xff, 0xff, 0xff, 0x00, 0x00, 0x1f, 0xff, 0xfc,
		0x00, 0x00, 0x00, 0x00, 0x3f, 0xff, 0xf8, 0x01, 0xff, 0xff, 0xff, 0x00, 0x00, 0x1f, 0xff, 0xfc,
		0x00, 0x00, 0x00, 0x00, 0x3f, 0xff, 0xf8, 0x01, 0xff, 0xff, 0xff, 0x00, 0x00, 0x1f, 0xff, 0xfc,
		0x00, 0x00, 0x00, 0x00, 0x3f, 0xff, 0xf8, 0x01, 0xff, 0xff, 0xff, 0x80, 0x00, 0x1f, 0xff, 0xfc,
		0x00, 0x00, 0x00, 0x00, 0x3f, 0xff, 0xf8, 0x03, 0xff, 0xff, 0xff, 0x80, 0x00, 0x1f, 0xff, 0xfc,
		0x00, 0x00, 0x00, 0x00, 0x7f, 0xff, 0xf8, 0x03, 0xff, 0xff, 0xff, 0x80, 0x00, 0x1f, 0xff, 0xfc,
		0x00, 0x00, 0x00, 0x00, 0x7f, 0xfc, 0x7c, 0x03, 0xff, 0xff, 0xff, 0xc0, 0x00, 0x1f, 0xff, 0xfc,
		0x00, 0x00, 0x00, 0x00, 0x7f, 0xff, 0xc0, 0x03, 0xff, 0xff, 0xff, 0xc0, 0x00, 0x1f, 0xff, 0xfe,
		0x00, 0x00, 0x00, 0x00, 0x7f, 0xff, 0xf8, 0x07, 0xff, 0xff, 0xff, 0xc0, 0x00, 0x1f, 0xff, 0xfe,
		0x00, 0x00, 0x00, 0x00, 0x7f, 0xff, 0xfc, 0x03, 0xff, 0xff, 0xff, 0xe0, 0x00, 0x1f, 0xff, 0xfe,
		0x00, 0x00, 0x00, 0x00, 0x7f, 0xff, 0xfc, 0x00, 0x3f, 0xff, 0xff, 0xe0, 0x00, 0x1f, 0xff, 0xfe,
		0x00, 0x00, 0x00, 0x00, 0x7f, 0xff, 0xfc, 0x0e, 0x07, 0xff, 0xff, 0xe0, 0x00, 0x3f, 0xff, 0xfe,
		0x00, 0x00, 0x00, 0x00, 0xff, 0xff, 0xfc, 0x0f, 0xc0, 0xff, 0xff, 0xf0, 0x00, 0x3f, 0xff, 0xfe,
		0x00, 0x00, 0x00, 0x00, 0xff, 0xff, 0xfc, 0x0f, 0xf8, 0x1f, 0xff, 0xf0, 0x00, 0x3f, 0xff, 0xff,
		0x00, 0x00, 0x00, 0x00, 0xff, 0xff, 0xfc, 0x0f, 0xff, 0x01, 0xff, 0xf0, 0x00, 0x3f, 0xff, 0xff,
		0x00, 0x00, 0x00, 0x00, 0xff, 0xe0, 0x00, 0x01, 0xff, 0xe0, 0x3f, 0xf8, 0x00, 0x3f, 0xff, 0xff,
		0x00, 0x00, 0x00, 0x00, 0xf8, 0x00, 0x00, 0x00, 0x0f, 0xfc, 0x07, 0xf8, 0x00, 0x3f, 0xff, 0xff,
		0x00, 0x00, 0x00, 0x00, 0x00, 0x07, 0xf8, 0x00, 0x00, 0xff, 0x00, 0x78, 0x00, 0x3f, 0xff, 0xff,
		0x00, 0x00, 0x00, 0x00, 0x03, 0xff, 0xf0, 0x00, 0x00, 0x1f, 0xe0, 0x08, 0x00, 0x3f, 0xff, 0xff,
		0x00, 0x00, 0x00, 0x00, 0x3f, 0xff, 0xf0, 0x00, 0x00, 0x07, 0xfc, 0x00, 0x00, 0x3f, 0xff, 0xff,
		0x00, 0x00, 0x00, 0x00, 0xff, 0xff, 0xe0, 0x00, 0x00, 0x01, 0xff, 0x80, 0x00, 0x3f, 0xff, 0xff,
		0x00, 0x00, 0x00, 0x01, 0xff, 0xff, 0xc0, 0x00, 0x00, 0x00, 0x7f, 0xf8, 0x00, 0x3f, 0xff, 0xff,
		0x00, 0x00, 0x00, 0x00, 0xff, 0xff, 0xc0, 0x00, 0x00, 0x00, 0x1f, 0xfe, 0x00, 0x07, 0xff, 0xff,
		0x00, 0x00, 0x00, 0x00, 0xff, 0xff, 0xc0, 0x00, 0x00, 0x00, 0x8f, 0xfe, 0x00, 0x0f, 0xff, 0xff,
		0x00, 0x00, 0x00, 0x00, 0xff, 0xff, 0x80, 0x00, 0x00, 0x00, 0xe3, 0xff, 0x00, 0x3f, 0xff, 0xff,
		0x00, 0x00, 0x00, 0x00, 0xff, 0xff, 0x80, 0x00, 0x00, 0x00, 0xf9, 0xff, 0x00, 0x3f, 0xff, 0xff,
		0x00, 0x00, 0x00, 0x01, 0x7f, 0xff, 0x80, 0x00, 0x00, 0x00, 0xfc, 0xff, 0x00, 0x3f, 0xff, 0xff,
		0x00, 0x00, 0x00, 0x01, 0x7f, 0xff, 0x80, 0x00, 0x00, 0x00, 0x7e, 0x3f, 0x80, 0x3f, 0xff, 0xff,
		0x00, 0x00, 0x00, 0x01, 0xff, 0xff, 0x80, 0x00, 0x00, 0x00, 0xff, 0x1f, 0x80, 0x3f, 0xff, 0xff,
		0x00, 0x00, 0x00, 0x01, 0xff, 0xff, 0x80, 0x00, 0x00, 0x00, 0xff, 0xcf, 0x80, 0x3f, 0xff, 0xff,
		0x00, 0x00, 0x00, 0x01, 0xff, 0xff, 0x80, 0x00, 0x00, 0x00, 0xff, 0xe7, 0xc0, 0x3f, 0xff, 0xff,
		0x00, 0x00, 0x00, 0x03, 0xff, 0xff, 0xc0, 0x00, 0x00, 0x00, 0xff, 0xe3, 0xc0, 0x7f, 0xff, 0xff,
		0x00, 0x00, 0x00, 0x03, 0xff, 0xff, 0xc0, 0x00, 0x01, 0xff, 0xff, 0xf3, 0xc0, 0x7f, 0xff, 0xff,
		0x00, 0x00, 0x00, 0x03, 0xff, 0xff, 0xe0, 0x00, 0x00, 0x01, 0xff, 0xfb, 0xe0, 0x7f, 0xff, 0xff,
		0x00, 0x00, 0x00, 0x03, 0xff, 0xff, 0xe0, 0x00, 0x00, 0x01, 0xff, 0xfd, 0xe0, 0x7f, 0xff, 0xff,
		0x00, 0x00, 0x00, 0x03, 0xfd, 0xff, 0xf0, 0x00, 0x00, 0x03, 0xff, 0xff, 0xf0, 0x7f, 0xff, 0xff,
		0x00, 0x00, 0x00, 0x03, 0xfc, 0xff, 0xf8, 0x00, 0x00, 0x07, 0xff, 0xff, 0xf0, 0x7f, 0xff, 0xff,
		0x00, 0x00, 0x00, 0x03, 0xfe, 0x7f, 0xfc, 0x00, 0x00, 0x0f, 0xff, 0xff, 0xf0, 0x7f, 0xff, 0xff,
		0x00, 0x00, 0x00, 0x03, 0xff, 0x3f, 0xfe, 0x00, 0x00, 0x1f, 0xff, 0xff, 0xf8, 0x7f, 0xff, 0xff,
		0x00, 0x00, 0x00, 0x03, 0xff, 0x9f, 0xff, 0x80, 0x00, 0x3f, 0xff, 0xff, 0xf8, 0x7f, 0xff, 0xff,
		0x00, 0x00, 0x00, 0x03, 0xff, 0x80, 0x7f, 0xc0, 0x00, 0x7f, 0xff, 0xff, 0xfc, 0x7f, 0xff, 0xff,
		0x00, 0x00, 0x00, 0x03, 0xff, 0xf0, 0x00, 0x3f, 0xff, 0xff, 0xff, 0xff, 0xfc, 0x7f, 0xff, 0xff,
		0x00, 0x00, 0x00, 0x03, 0xff, 0xff, 0xff, 0xff, 0xff, 0xff, 0xff, 0xff, 0xfe, 0x7f, 0xff, 0xff,
		0x00, 0x00, 0x00, 0x03, 0xff, 0xff, 0xff, 0xff, 0xff, 0xff, 0xff, 0xff, 0xfe, 0x7f, 0xff, 0xff,
		0x00, 0x00, 0x00, 0x03, 0xff, 0xff, 0xff, 0xff, 0xff, 0xff, 0xff, 0xff, 0xfe, 0x7f, 0xff, 0xff,
		0x00, 0x00, 0x00, 0x03, 0xff, 0xff, 0xff, 0xff, 0xff, 0xff, 0xff, 0xff, 0xff, 0x7f, 0xff, 0xff,
		0x00, 0x00, 0x00, 0x03, 0xff, 0xff, 0xff, 0xff, 0xff, 0xff, 0xff, 0xff, 0xff, 0x7f, 0xff, 0xff,
		0x00, 0x00, 0x00, 0x03, 0xff, 0xff, 0xff, 0xff, 0xff, 0xff, 0xff, 0xff, 0xff, 0xff, 0xff, 0xff,
		0x00, 0x00, 0x00, 0x03, 0xff, 0xff, 0xff, 0xff, 0xff, 0xff, 0xff, 0xff, 0xff, 0xff, 0xff, 0xff,
		0x00, 0x00, 0x00, 0x03, 0xff, 0xff, 0xff, 0xff, 0xff, 0xff, 0xff, 0xff, 0xff, 0xff, 0xff, 0xff,
		0x00, 0x00, 0x00, 0x07, 0xff, 0xff, 0xff, 0xff, 0xff, 0xff, 0xff, 0xff, 0xff, 0xff, 0xff, 0xff,
		0x00, 0x00, 0x00, 0x07, 0xff, 0xff, 0xff, 0xff, 0xff, 0xff, 0xff, 0xff, 0xff, 0xff, 0xff, 0xff,
		0x00, 0x00, 0x00, 0x07, 0xff, 0xff, 0xff, 0xff, 0xff, 0xff, 0xff, 0xff, 0xff, 0xff, 0xff, 0xff,
		0x00, 0x00, 0x00, 0x07, 0xff, 0xff, 0xff, 0xff, 0xff, 0xff, 0xff, 0xff, 0xff, 0xff, 0xff, 0xff,
		0x00, 0x00, 0x00, 0x07, 0xff, 0xff, 0xff, 0xff, 0xff, 0xff, 0xff, 0xff, 0xff, 0xff, 0xff, 0xff,
		0x00, 0x00, 0x00, 0x07, 0xff, 0xff, 0xff, 0xff, 0xff, 0xff, 0xff, 0xff, 0xff, 0xff, 0xff, 0xff,
		0x00, 0x00, 0x00, 0x07, 0xff, 0xff, 0xff, 0xff, 0xff, 0xff, 0xff, 0xff, 0xff, 0xff, 0xff, 0xff,
		0x00, 0x00, 0x00, 0x07, 0xff, 0xff, 0xff, 0xff, 0xff, 0xff, 0xff, 0xff, 0xff, 0xff, 0xff, 0xff,
		0x00, 0x00, 0x00, 0x03, 0xff, 0xff, 0xff, 0xff, 0xff, 0xff, 0xff, 0xff, 0xff, 0xff, 0xff, 0xff,
		0x00, 0x00, 0x00, 0x07, 0xff, 0xff, 0xff, 0xff, 0xff, 0xff, 0xff, 0xff, 0xff, 0xff, 0xff, 0xff,
		0x00, 0x00, 0x00, 0x07, 0xff, 0xff, 0xff, 0xff, 0xff, 0xff, 0xff, 0xff, 0xff, 0xff, 0xff, 0xff
	};
	// 'frame6', 128x64px
	const unsigned char epd_bitmap_frame6 []  = {
		0x00, 0x00, 0x00, 0x00, 0x3f, 0xff, 0xf8, 0x00, 0xff, 0xff, 0xfe, 0x00, 0x00, 0x0f, 0xff, 0xfc,
		0x00, 0x00, 0x00, 0x00, 0x3f, 0xff, 0xf8, 0x00, 0xff, 0xff, 0xff, 0x00, 0x00, 0x0f, 0xff, 0xfc,
		0x00, 0x00, 0x00, 0x00, 0x3f, 0xff, 0xf8, 0x00, 0xff, 0xff, 0xff, 0x00, 0x00, 0x0f, 0xff, 0xfc,
		0x00, 0x00, 0x00, 0x00, 0x3f, 0xff, 0xf8, 0x01, 0xff, 0xff, 0xff, 0x00, 0x00, 0x0f, 0xff, 0xfc,
		0x00, 0x00, 0x00, 0x00, 0x3f, 0xff, 0xf8, 0x01, 0xff, 0xff, 0xff, 0x80, 0x00, 0x0f, 0xff, 0xfe,
		0x00, 0x00, 0x00, 0x00, 0x7f, 0xff, 0xf8, 0x01, 0xff, 0xff, 0xff, 0x80, 0x00, 0x0f, 0xff, 0xfe,
		0x00, 0x00, 0x00, 0x00, 0x7f, 0xff, 0xf8, 0x01, 0xff, 0xff, 0xff, 0x80, 0x00, 0x0f, 0xff, 0xfe,
		0x00, 0x00, 0x00, 0x00, 0x7f, 0xff, 0xf8, 0x03, 0xff, 0xff, 0xff, 0xc0, 0x00, 0x0f, 0xff, 0xfe,
		0x00, 0x00, 0x00, 0x00, 0x7f, 0xff, 0xf8, 0x03, 0xff, 0xff, 0xff, 0xc0, 0x00, 0x0f, 0xff, 0xfe,
		0x00, 0x00, 0x00, 0x00, 0x7f, 0xff, 0xfc, 0x03, 0xff, 0xff, 0xff, 0xc0, 0x00, 0x0f, 0xff, 0xfe,
		0x00, 0x00, 0x00, 0x00, 0x7f, 0xff, 0xfc, 0x03, 0xff, 0xff, 0xff, 0xc0, 0x00, 0x1f, 0xff, 0xfe,
		0x00, 0x00, 0x00, 0x00, 0x7f, 0xff, 0xfc, 0x07, 0xff, 0xff, 0xff, 0xe0, 0x00, 0x1f, 0xff, 0xff,
		0x00, 0x00, 0x00, 0x00, 0x7f, 0xf9, 0xfc, 0x07, 0xff, 0xff, 0xff, 0xe0, 0x00, 0x1f, 0xff, 0xff,
		0x00, 0x00, 0x00, 0x00, 0xff, 0xff, 0x1c, 0x07, 0xff, 0xff, 0xff, 0xe0, 0x00, 0x1f, 0xff, 0xff,
		0x00, 0x00, 0x00, 0x00, 0xff, 0xff, 0xe0, 0x0f, 0xff, 0xff, 0xff, 0xf0, 0x00, 0x1f, 0xff, 0xff,
		0x00, 0x00, 0x00, 0x00, 0xff, 0xff, 0xfc, 0x0f, 0xff, 0xff, 0xff, 0xf0, 0x00, 0x1f, 0xff, 0xff,
		0x00, 0x00, 0x00, 0x00, 0xff, 0xff, 0xfc, 0x01, 0xff, 0xff, 0xff, 0xf0, 0x00, 0x1f, 0xff, 0xff,
		0x00, 0x00, 0x00, 0x00, 0xff, 0xff, 0xfe, 0x08, 0x1f, 0xff, 0xff, 0xf8, 0x00, 0x1f, 0xff, 0xff,
		0x00, 0x00, 0x00, 0x00, 0xff, 0xff, 0xfe, 0x1f, 0x01, 0xff, 0xff, 0xf8, 0x00, 0x1f, 0xff, 0xff,
		0x00, 0x00, 0x00, 0x00, 0xff, 0xff, 0xfe, 0x1f, 0xf0, 0x3f, 0xff, 0xf8, 0x00, 0x1f, 0xff, 0xff,
		0x00, 0x00, 0x00, 0x00, 0xff, 0xff, 0xfe, 0x1f, 0xfc, 0x03, 0xff, 0xfc, 0x00, 0x1f, 0xff, 0xff,
		0x00, 0x00, 0x00, 0x01, 0xff, 0xff, 0xfe, 0x1f, 0xff, 0xc0, 0x3f, 0xfc, 0x00, 0x1f, 0xff, 0xff,
		0x00, 0x00, 0x00, 0x01, 0xff, 0xff, 0xfe, 0x3f, 0xff, 0xf8, 0x07, 0xfc, 0x00, 0x1f, 0xff, 0xff,
		0x00, 0x00, 0x00, 0x01, 0xff, 0xf0, 0x06, 0x3f, 0xff, 0xff, 0x00, 0x7e, 0x00, 0x1f, 0xff, 0xff,
		0x00, 0x00, 0x00, 0x01, 0xc0, 0x00, 0x00, 0x00, 0xff, 0xff, 0xe0, 0x0e, 0x00, 0x3f, 0xff, 0xff,
		0x00, 0x00, 0x00, 0x00, 0x00, 0x0f, 0xc0, 0x00, 0x03, 0xff, 0xfc, 0x00, 0x00, 0x3f, 0xff, 0xff,
		0x00, 0x00, 0x00, 0x00, 0x3f, 0xff, 0xc0, 0x00, 0x00, 0x1f, 0xff, 0x80, 0x00, 0x3f, 0xff, 0xff,
		0x00, 0x00, 0x00, 0x01, 0xff, 0xff, 0x80, 0x00, 0x00, 0x01, 0xff, 0xf0, 0x00, 0x3f, 0xff, 0xff,
		0x00, 0x00, 0x00, 0x01, 0xff, 0xff, 0x80, 0x00, 0x00, 0x00, 0x3f, 0xfe, 0x00, 0x03, 0xff, 0xff,
		0x00, 0x00, 0x00, 0x00, 0xff, 0xff, 0x80, 0x00, 0x00, 0x00, 0x07, 0xff, 0x00, 0x07, 0xff, 0xff,
		0x00, 0x00, 0x00, 0x00, 0xff, 0xff, 0x80, 0x00, 0x00, 0x00, 0x63, 0xff, 0x80, 0x1f, 0xff, 0xff,
		0x00, 0x00, 0x00, 0x03, 0x7f, 0xff, 0x80, 0x00, 0x00, 0x00, 0x78, 0xff, 0x80, 0x3f, 0xff, 0xff,
		0x00, 0x00, 0x00, 0x03, 0x7f, 0xff, 0x80, 0x00, 0x00, 0x00, 0x7e, 0x3f, 0xc0, 0x3f, 0xff, 0xff,
		0x00, 0x00, 0x00, 0x03, 0xbf, 0xff, 0x80, 0x00, 0x00, 0x00, 0x7f, 0x9f, 0xc0, 0x3f, 0xff, 0xff,
		0x00, 0x00, 0x00, 0x03, 0xff, 0xff, 0xc0, 0x00, 0x00, 0x00, 0xff, 0xc7, 0xe0, 0x3f, 0xff, 0xff,
		0x00, 0x00, 0x00, 0x03, 0xff, 0xff, 0xc0, 0x00, 0x10, 0xff, 0xff, 0xf7, 0xe0, 0x3f, 0xff, 0xff,
		0x00, 0x00, 0x00, 0x03, 0xff, 0xff, 0xc0, 0x00, 0x00, 0x01, 0xff, 0xfb, 0xe0, 0x3f, 0xff, 0xff,
		0x00, 0x00, 0x00, 0x03, 0xfb, 0xff, 0xe0, 0x00, 0x00, 0x01, 0xff, 0xfd, 0xf0, 0x3f, 0xff, 0xff,
		0x00, 0x00, 0x00, 0x03, 0xfd, 0xff, 0xf0, 0x00, 0x00, 0x03, 0xff, 0xff, 0xf0, 0x3f, 0xff, 0xff,
		0x00, 0x00, 0x00, 0x03, 0xfe, 0xff, 0xf0, 0x00, 0x00, 0x03, 0xff, 0xff, 0xf0, 0x3f, 0xff, 0xff,
		0x00, 0x00, 0x00, 0x03, 0xfe, 0x7f, 0xf8, 0x00, 0x00, 0x07, 0xff, 0xff, 0xf8, 0x3f, 0xff, 0xff,
		0x00, 0x00, 0x00, 0x03, 0xff, 0x1f, 0xfe, 0x00, 0x00, 0x0f, 0xff, 0xff, 0xf8, 0x3f, 0xff, 0xff,
		0x00, 0x00, 0x00, 0x03, 0xff, 0x83, 0xfe, 0x00, 0x00, 0x00, 0x2f, 0xff, 0xfc, 0x3f, 0xff, 0xff,
		0x00, 0x00, 0x00, 0x03, 0xff, 0xe0, 0x00, 0xff, 0xff, 0xff, 0xff, 0xff, 0xfc, 0x3f, 0xff, 0xff,
		0x00, 0x00, 0x00, 0x03, 0xff, 0xff, 0xff, 0xff, 0xff, 0xff, 0xff, 0xff, 0xfe, 0x3f, 0xff, 0xff,
		0x00, 0x00, 0x00, 0x07, 0xff, 0xff, 0xff, 0xff, 0xff, 0xff, 0xff, 0xff, 0xfe, 0x3f, 0xff, 0xff,
		0x00, 0x00, 0x00, 0x07, 0xff, 0xff, 0xff, 0xff, 0xff, 0xff, 0xff, 0xff, 0xfe, 0x7f, 0xff, 0xff,
		0x00, 0x00, 0x00, 0x07, 0xff, 0xff, 0xff, 0xff, 0xff, 0xff, 0xff, 0xff, 0xff, 0x7f, 0xff, 0xff,
		0x00, 0x00, 0x00, 0x07, 0xff, 0xff, 0xff, 0xff, 0xff, 0xff, 0xff, 0xff, 0xff, 0x3f, 0xff, 0xff,
		0x00, 0x00, 0x00, 0x07, 0xff, 0xff, 0xff, 0xff, 0xff, 0xff, 0xff, 0xff, 0xff, 0xbf, 0xff, 0xff,
		0x00, 0x00, 0x00, 0x07, 0xff, 0xff, 0xff, 0xff, 0xff, 0xff, 0xff, 0xff, 0xff, 0xff, 0xff, 0xff,
		0x00, 0x00, 0x00, 0x07, 0xff, 0xff, 0xff, 0xff, 0xff, 0xff, 0xff, 0xff, 0xff, 0xff, 0xff, 0xff,
		0x00, 0x00, 0x00, 0x07, 0xff, 0xff, 0xff, 0xff, 0xff, 0xff, 0xff, 0xff, 0xff, 0xff, 0xff, 0xff,
		0x00, 0x00, 0x00, 0x07, 0xff, 0xff, 0xff, 0xff, 0xff, 0xff, 0xff, 0xff, 0xff, 0xff, 0xff, 0xff,
		0x00, 0x00, 0x00, 0x07, 0xff, 0xff, 0xff, 0xff, 0xff, 0xff, 0xff, 0xff, 0xff, 0xff, 0xff, 0xff,
		0x00, 0x00, 0x00, 0x07, 0xff, 0xff, 0xff, 0xff, 0xff, 0xff, 0xff, 0xff, 0xff, 0xff, 0xff, 0xff,
		0x00, 0x00, 0x00, 0x07, 0xff, 0xff, 0xff, 0xff, 0xff, 0xff, 0xff, 0xff, 0xff, 0xff, 0xff, 0xff,
		0x00, 0x00, 0x00, 0x07, 0xff, 0xff, 0xff, 0xff, 0xff, 0xff, 0xff, 0xff, 0xff, 0xff, 0xff, 0xff,
		0x00, 0x00, 0x00, 0x07, 0xff, 0xff, 0xff, 0xff, 0xff, 0xff, 0xff, 0xff, 0xff, 0xff, 0xff, 0xff,
		0x00, 0x00, 0x00, 0x07, 0xff, 0xff, 0xff, 0xff, 0xff, 0xff, 0xff, 0xff, 0xff, 0xff, 0xff, 0xff,
		0x00, 0x00, 0x00, 0x07, 0xff, 0xff, 0xff, 0xff, 0xff, 0xff, 0xff, 0xff, 0xff, 0xff, 0xff, 0xff,
		0x00, 0x00, 0x00, 0x07, 0xff, 0xff, 0xff, 0xff, 0xff, 0xff, 0xff, 0xff, 0xff, 0xff, 0xff, 0xff,
		0x00, 0x00, 0x00, 0x07, 0xff, 0xff, 0xff, 0xff, 0xff, 0xff, 0xff, 0xff, 0xff, 0xff, 0xff, 0xff,
		0x00, 0x00, 0x00, 0x07, 0xff, 0xff, 0xff, 0xff, 0xff, 0xff, 0xff, 0xff, 0xff, 0xff, 0xff, 0xff
	};
	// 'frame7', 128x64px
	const unsigned char epd_bitmap_frame7 []  = {
		0x00, 0x00, 0x00, 0x00, 0x1f, 0xff, 0xf8, 0x00, 0xff, 0xff, 0xfe, 0x00, 0x00, 0x0f, 0xff, 0xf8,
		0x00, 0x00, 0x00, 0x00, 0x3f, 0xff, 0xf8, 0x00, 0xff, 0xff, 0xfe, 0x00, 0x00, 0x0f, 0xff, 0xf8,
		0x00, 0x00, 0x00, 0x00, 0x3f, 0xff, 0xf8, 0x00, 0xff, 0xff, 0xff, 0x00, 0x00, 0x1f, 0xff, 0xf8,
		0x00, 0x00, 0x00, 0x00, 0x3f, 0xff, 0xf8, 0x01, 0xff, 0xff, 0xff, 0x00, 0x00, 0x1f, 0xff, 0xfc,
		0x00, 0x00, 0x00, 0x00, 0x3f, 0xff, 0xf8, 0x01, 0xff, 0xff, 0xff, 0x00, 0x00, 0x1f, 0xff, 0xfc,
		0x00, 0x00, 0x00, 0x00, 0x3f, 0xff, 0xf8, 0x01, 0xff, 0xff, 0xff, 0x00, 0x00, 0x1f, 0xff, 0xfc,
		0x00, 0x00, 0x00, 0x00, 0x3f, 0xff, 0xf8, 0x01, 0xff, 0xff, 0xff, 0x80, 0x00, 0x1f, 0xff, 0xfc,
		0x00, 0x00, 0x00, 0x00, 0x3f, 0xff, 0xf8, 0x03, 0xff, 0xff, 0xff, 0x80, 0x00, 0x1f, 0xff, 0xfc,
		0x00, 0x00, 0x00, 0x00, 0x7f, 0xff, 0xf8, 0x03, 0xff, 0xff, 0xff, 0x80, 0x00, 0x1f, 0xff, 0xfc,
		0x00, 0x00, 0x00, 0x00, 0x7f, 0xfc, 0x7c, 0x03, 0xff, 0xff, 0xff, 0xc0, 0x00, 0x1f, 0xff, 0xfc,
		0x00, 0x00, 0x00, 0x00, 0x7f, 0xff, 0xc0, 0x03, 0xff, 0xff, 0xff, 0xc0, 0x00, 0x1f, 0xff, 0xfe,
		0x00, 0x00, 0x00, 0x00, 0x7f, 0xff, 0xf8, 0x07, 0xff, 0xff, 0xff, 0xc0, 0x00, 0x1f, 0xff, 0xfe,
		0x00, 0x00, 0x00, 0x00, 0x7f, 0xff, 0xfc, 0x03, 0xff, 0xff, 0xff, 0xe0, 0x00, 0x1f, 0xff, 0xfe,
		0x00, 0x00, 0x00, 0x00, 0x7f, 0xff, 0xfc, 0x00, 0x3f, 0xff, 0xff, 0xe0, 0x00, 0x1f, 0xff, 0xfe,
		0x00, 0x00, 0x00, 0x00, 0x7f, 0xff, 0xfc, 0x0e, 0x07, 0xff, 0xff, 0xe0, 0x00, 0x3f, 0xff, 0xfe,
		0x00, 0x00, 0x00, 0x00, 0xff, 0xff, 0xfc, 0x0f, 0xc0, 0xff, 0xff, 0xf0, 0x00, 0x3f, 0xff, 0xfe,
		0x00, 0x00, 0x00, 0x00, 0xff, 0xff, 0xfc, 0x0f, 0xf8, 0x1f, 0xff, 0xf0, 0x00, 0x3f, 0xff, 0xff,
		0x00, 0x00, 0x00, 0x00, 0xff, 0xff, 0xfc, 0x0f, 0xff, 0x01, 0xff, 0xf0, 0x00, 0x3f, 0xff, 0xff,
		0x00, 0x00, 0x00, 0x00, 0xff, 0xe0, 0x00, 0x01, 0xff, 0xe0, 0x3f, 0xf8, 0x00, 0x3f, 0xff, 0xff,
		0x00, 0x00, 0x00, 0x00, 0xf8, 0x00, 0x00, 0x00, 0x0f, 0xfc, 0x07, 0xf8, 0x00, 0x3f, 0xff, 0xff,
		0x00, 0x00, 0x00, 0x00, 0x00, 0x07, 0xf8, 0x00, 0x00, 0xff, 0x00, 0x78, 0x00, 0x3f, 0xff, 0xff,
		0x00, 0x00, 0x00, 0x00, 0x03, 0xff, 0xf0, 0x00, 0x00, 0x1f, 0xe0, 0x08, 0x00, 0x3f, 0xff, 0xff,
		0x00, 0x00, 0x00, 0x00, 0x3f, 0xff, 0xf0, 0x00, 0x00, 0x07, 0xfc, 0x00, 0x00, 0x3f, 0xff, 0xff,
		0x00, 0x00, 0x00, 0x00, 0xff, 0xff, 0xe0, 0x00, 0x00, 0x01, 0xff, 0x80, 0x00, 0x3f, 0xff, 0xff,
		0x00, 0x00, 0x00, 0x01, 0xff, 0xff, 0xc0, 0x00, 0x00, 0x00, 0x7f, 0xf8, 0x00, 0x3f, 0xff, 0xff,
		0x00, 0x00, 0x00, 0x00, 0xff, 0xff, 0xc0, 0x00, 0x00, 0x00, 0x1f, 0xfe, 0x00, 0x07, 0xff, 0xff,
		0x00, 0x00, 0x00, 0x00, 0xff, 0xff, 0xc0, 0x00, 0x00, 0x00, 0x8f, 0xfe, 0x00, 0x0f, 0xff, 0xff,
		0x00, 0x00, 0x00, 0x00, 0xff, 0xff, 0x80, 0x00, 0x00, 0x00, 0xe3, 0xff, 0x00, 0x3f, 0xff, 0xff,
		0x00, 0x00, 0x00, 0x00, 0xff, 0xff, 0x80, 0x00, 0x00, 0x00, 0xf9, 0xff, 0x00, 0x3f, 0xff, 0xff,
		0x00, 0x00, 0x00, 0x01, 0x7f, 0xff, 0x80, 0x00, 0x00, 0x00, 0xfc, 0xff, 0x00, 0x3f, 0xff, 0xff,
		0x00, 0x00, 0x00, 0x01, 0x7f, 0xff, 0x80, 0x00, 0x00, 0x00, 0x7e, 0x3f, 0x80, 0x3f, 0xff, 0xff,
		0x00, 0x00, 0x00, 0x01, 0xff, 0xff, 0x80, 0x00, 0x00, 0x00, 0xff, 0x1f, 0x80, 0x3f, 0xff, 0xff,
		0x00, 0x00, 0x00, 0x01, 0xff, 0xff, 0x80, 0x00, 0x00, 0x00, 0xff, 0xcf, 0x80, 0x3f, 0xff, 0xff,
		0x00, 0x00, 0x00, 0x01, 0xff, 0xff, 0x80, 0x00, 0x00, 0x00, 0xff, 0xe7, 0xc0, 0x3f, 0xff, 0xff,
		0x00, 0x00, 0x00, 0x03, 0xff, 0xff, 0xc0, 0x00, 0x00, 0x00, 0xff, 0xe3, 0xc0, 0x7f, 0xff, 0xff,
		0x00, 0x00, 0x00, 0x03, 0xff, 0xff, 0xc0, 0x00, 0x01, 0xff, 0xff, 0xf3, 0xc0, 0x7f, 0xff, 0xff,
		0x00, 0x00, 0x00, 0x03, 0xff, 0xff, 0xe0, 0x00, 0x00, 0x01, 0xff, 0xfb, 0xe0, 0x7f, 0xff, 0xff,
		0x00, 0x00, 0x00, 0x03, 0xff, 0xff, 0xe0, 0x00, 0x00, 0x01, 0xff, 0xfd, 0xe0, 0x7f, 0xff, 0xff,
		0x00, 0x00, 0x00, 0x03, 0xfd, 0xff, 0xf0, 0x00, 0x00, 0x03, 0xff, 0xff, 0xf0, 0x7f, 0xff, 0xff,
		0x00, 0x00, 0x00, 0x03, 0xfc, 0xff, 0xf8, 0x00, 0x00, 0x07, 0xff, 0xff, 0xf0, 0x7f, 0xff, 0xff,
		0x00, 0x00, 0x00, 0x03, 0xfe, 0x7f, 0xfc, 0x00, 0x00, 0x0f, 0xff, 0xff, 0xf0, 0x7f, 0xff, 0xff,
		0x00, 0x00, 0x00, 0x03, 0xff, 0x3f, 0xfe, 0x00, 0x00, 0x1f, 0xff, 0xff, 0xf8, 0x7f, 0xff, 0xff,
		0x00, 0x00, 0x00, 0x03, 0xff, 0x9f, 0xff, 0x80, 0x00, 0x3f, 0xff, 0xff, 0xf8, 0x7f, 0xff, 0xff,
		0x00, 0x00, 0x00, 0x03, 0xff, 0x80, 0x7f, 0xc0, 0x00, 0x7f, 0xff, 0xff, 0xfc, 0x7f, 0xff, 0xff,
		0x00, 0x00, 0x00, 0x03, 0xff, 0xf0, 0x00, 0x3f, 0xff, 0xff, 0xff, 0xff, 0xfc, 0x7f, 0xff, 0xff,
		0x00, 0x00, 0x00, 0x03, 0xff, 0xff, 0xff, 0xff, 0xff, 0xff, 0xff, 0xff, 0xfe, 0x7f, 0xff, 0xff,
		0x00, 0x00, 0x00, 0x03, 0xff, 0xff, 0xff, 0xff, 0xff, 0xff, 0xff, 0xff, 0xfe, 0x7f, 0xff, 0xff,
		0x00, 0x00, 0x00, 0x03, 0xff, 0xff, 0xff, 0xff, 0xff, 0xff, 0xff, 0xff, 0xfe, 0x7f, 0xff, 0xff,
		0x00, 0x00, 0x00, 0x03, 0xff, 0xff, 0xff, 0xff, 0xff, 0xff, 0xff, 0xff, 0xff, 0x7f, 0xff, 0xff,
		0x00, 0x00, 0x00, 0x03, 0xff, 0xff, 0xff, 0xff, 0xff, 0xff, 0xff, 0xff, 0xff, 0x7f, 0xff, 0xff,
		0x00, 0x00, 0x00, 0x03, 0xff, 0xff, 0xff, 0xff, 0xff, 0xff, 0xff, 0xff, 0xff, 0xff, 0xff, 0xff,
		0x00, 0x00, 0x00, 0x03, 0xff, 0xff, 0xff, 0xff, 0xff, 0xff, 0xff, 0xff, 0xff, 0xff, 0xff, 0xff,
		0x00, 0x00, 0x00, 0x03, 0xff, 0xff, 0xff, 0xff, 0xff, 0xff, 0xff, 0xff, 0xff, 0xff, 0xff, 0xff,
		0x00, 0x00, 0x00, 0x07, 0xff, 0xff, 0xff, 0xff, 0xff, 0xff, 0xff, 0xff, 0xff, 0xff, 0xff, 0xff,
		0x00, 0x00, 0x00, 0x07, 0xff, 0xff, 0xff, 0xff, 0xff, 0xff, 0xff, 0xff, 0xff, 0xff, 0xff, 0xff,
		0x00, 0x00, 0x00, 0x07, 0xff, 0xff, 0xff, 0xff, 0xff, 0xff, 0xff, 0xff, 0xff, 0xff, 0xff, 0xff,
		0x00, 0x00, 0x00, 0x07, 0xff, 0xff, 0xff, 0xff, 0xff, 0xff, 0xff, 0xff, 0xff, 0xff, 0xff, 0xff,
		0x00, 0x00, 0x00, 0x07, 0xff, 0xff, 0xff, 0xff, 0xff, 0xff, 0xff, 0xff, 0xff, 0xff, 0xff, 0xff,
		0x00, 0x00, 0x00, 0x07, 0xff, 0xff, 0xff, 0xff, 0xff, 0xff, 0xff, 0xff, 0xff, 0xff, 0xff, 0xff,
		0x00, 0x00, 0x00, 0x07, 0xff, 0xff, 0xff, 0xff, 0xff, 0xff, 0xff, 0xff, 0xff, 0xff, 0xff, 0xff,
		0x00, 0x00, 0x00, 0x07, 0xff, 0xff, 0xff, 0xff, 0xff, 0xff, 0xff, 0xff, 0xff, 0xff, 0xff, 0xff,
		0x00, 0x00, 0x00, 0x03, 0xff, 0xff, 0xff, 0xff, 0xff, 0xff, 0xff, 0xff, 0xff, 0xff, 0xff, 0xff,
		0x00, 0x00, 0x00, 0x07, 0xff, 0xff, 0xff, 0xff, 0xff, 0xff, 0xff, 0xff, 0xff, 0xff, 0xff, 0xff,
		0x00, 0x00, 0x00, 0x07, 0xff, 0xff, 0xff, 0xff, 0xff, 0xff, 0xff, 0xff, 0xff, 0xff, 0xff, 0xff
	};
	// 'frame8', 128x64px
	const unsigned char epd_bitmap_frame8 []  = {
		0x00, 0x00, 0x00, 0x03, 0xff, 0xfe, 0x00, 0x7f, 0xc0, 0x3f, 0xff, 0xff, 0x80, 0x00, 0x3f, 0xff,
		0x00, 0x00, 0x00, 0x07, 0xff, 0xfe, 0x00, 0x7f, 0xf8, 0x07, 0xff, 0xff, 0xc0, 0x00, 0x3f, 0xff,
		0x00, 0x00, 0x00, 0x07, 0xff, 0xfe, 0x00, 0xff, 0xff, 0x00, 0xff, 0xff, 0xc0, 0x00, 0x3f, 0xff,
		0x00, 0x00, 0x00, 0x07, 0xff, 0xfe, 0x00, 0xff, 0xff, 0xe0, 0x1f, 0xff, 0xc0, 0x00, 0x3f, 0xff,
		0x00, 0x00, 0x00, 0x07, 0xff, 0xfe, 0x00, 0xff, 0xff, 0xfc, 0x03, 0xff, 0xe0, 0x00, 0x3f, 0xff,
		0x00, 0x00, 0x00, 0x0f, 0xff, 0xfe, 0x01, 0xff, 0xff, 0xff, 0x80, 0xff, 0xe0, 0x00, 0x3f, 0xff,
		0x00, 0x00, 0x00, 0x0f, 0xff, 0xfe, 0x01, 0xff, 0xff, 0xff, 0xe0, 0x1f, 0xf0, 0x00, 0x3f, 0xff,
		0x00, 0x00, 0x00, 0x0f, 0xff, 0xfe, 0x03, 0xff, 0xff, 0xff, 0xfc, 0x07, 0xf0, 0x00, 0x3f, 0xff,
		0x00, 0x00, 0x00, 0x0f, 0xff, 0xfe, 0x00, 0x00, 0x0f, 0xff, 0xff, 0x00, 0xf0, 0x00, 0x3f, 0xff,
		0x00, 0x00, 0x00, 0x1f, 0xff, 0xfc, 0x00, 0x00, 0x00, 0x7f, 0xff, 0xc0, 0x38, 0x00, 0x3f, 0xff,
		0x00, 0x00, 0x00, 0x1f, 0xff, 0xc0, 0x03, 0xff, 0xf0, 0x0f, 0xff, 0xf8, 0x08, 0x00, 0x3f, 0xff,
		0x00, 0x00, 0x00, 0x1f, 0xfe, 0x02, 0x07, 0xff, 0xff, 0x83, 0xff, 0xfe, 0x00, 0x00, 0x3f, 0xff,
		0x00, 0x00, 0x00, 0x3f, 0xf0, 0x1f, 0x07, 0xff, 0xff, 0xf0, 0xff, 0xff, 0x80, 0x00, 0x3f, 0xff,
		0x00, 0x00, 0x00, 0x3f, 0xc1, 0xff, 0x0f, 0xff, 0xff, 0xfc, 0x3f, 0xff, 0xe0, 0x00, 0x3f, 0xff,
		0x00, 0x00, 0x00, 0x3e, 0x07, 0xff, 0x0f, 0xff, 0xff, 0xff, 0x0f, 0xff, 0xf8, 0x00, 0x3f, 0xff,
		0x00, 0x00, 0x00, 0x3c, 0x1f, 0xff, 0x0f, 0xff, 0xff, 0xff, 0xc7, 0xff, 0xfc, 0x00, 0x3f, 0xff,
		0x00, 0x00, 0x00, 0x30, 0x7f, 0xff, 0x1f, 0xff, 0xff, 0xff, 0xe3, 0xff, 0xfe, 0x00, 0x3f, 0xff,
		0x00, 0x00, 0x00, 0x01, 0xff, 0xff, 0x1f, 0xf8, 0x07, 0xff, 0xf9, 0xff, 0xfe, 0x00, 0x3f, 0xff,
		0x00, 0x00, 0x00, 0x03, 0xff, 0xff, 0x1f, 0xc0, 0x00, 0xff, 0xfc, 0x7f, 0xfe, 0x00, 0x3f, 0xff,
		0x00, 0x00, 0x00, 0x0f, 0xff, 0xff, 0x3f, 0x80, 0x00, 0x7f, 0xfe, 0x3f, 0xff, 0x00, 0x3f, 0xff,
		0x00, 0x00, 0x00, 0x4f, 0xff, 0xff, 0x3e, 0x00, 0x00, 0x1f, 0xff, 0x1f, 0xff, 0x00, 0x3f, 0xff,
		0x00, 0x00, 0x00, 0x4f, 0xff, 0xff, 0x3c, 0x00, 0x00, 0x0f, 0xff, 0x9f, 0xff, 0x00, 0x3f, 0xff,
		0x00, 0x00, 0x00, 0xe7, 0xff, 0xff, 0x38, 0x00, 0x00, 0x0f, 0xff, 0xcf, 0xff, 0x00, 0x3f, 0xff,
		0x00, 0x00, 0x00, 0xe7, 0xff, 0xff, 0xb8, 0x00, 0x00, 0x07, 0xff, 0xc7, 0xff, 0x80, 0x3f, 0xff,
		0x00, 0x00, 0x00, 0xf7, 0xff, 0xff, 0xf0, 0x00, 0x00, 0x03, 0xff, 0xe3, 0xff, 0x80, 0x3f, 0xff,
		0x00, 0x00, 0x00, 0xfb, 0xff, 0xff, 0xf0, 0x00, 0x00, 0x03, 0xff, 0xe3, 0xff, 0xc0, 0x7f, 0xff,
		0x00, 0x00, 0x01, 0xff, 0xff, 0xff, 0xe0, 0x00, 0x00, 0x01, 0xff, 0xf1, 0xff, 0xc0, 0x7f, 0xff,
		0x00, 0x00, 0x01, 0xff, 0xff, 0xff, 0xe0, 0x00, 0x00, 0x01, 0xff, 0xf2, 0xff, 0xc0, 0x7f, 0xff,
		0x00, 0x00, 0x01, 0xff, 0xff, 0xff, 0xe0, 0x00, 0x00, 0x01, 0xff, 0xfa, 0xff, 0xc0, 0x7f, 0xff,
		0x00, 0x00, 0x01, 0xff, 0xff, 0xff, 0xe0, 0x00, 0x00, 0x01, 0xff, 0xf9, 0x7f, 0xe0, 0x7f, 0xff,
		0x00, 0x00, 0x01, 0xff, 0xff, 0xff, 0xe0, 0x00, 0x00, 0x01, 0xff, 0xfd, 0xff, 0xe0, 0x7f, 0xff,
		0x00, 0x00, 0x03, 0xff, 0xff, 0xff, 0xe0, 0x00, 0x03, 0xff, 0xff, 0xfd, 0xff, 0xe0, 0x7f, 0xff,
		0x00, 0x00, 0x03, 0xff, 0xff, 0xff, 0xe0, 0x00, 0x03, 0xff, 0xff, 0xff, 0xff, 0xf0, 0x7f, 0xff,
		0x00, 0x00, 0x03, 0xff, 0xff, 0xff, 0xe0, 0x00, 0x00, 0x01, 0xff, 0xfe, 0xff, 0xf0, 0x7f, 0xff,
		0x00, 0x00, 0x03, 0xff, 0xff, 0xff, 0xf0, 0x00, 0x00, 0x03, 0xff, 0xfe, 0xff, 0xf0, 0xff, 0xff,
		0x00, 0x00, 0x07, 0xff, 0xff, 0xff, 0xf0, 0x00, 0x00, 0x03, 0xff, 0xff, 0xff, 0xf0, 0xff, 0xff,
		0x00, 0x00, 0x07, 0xff, 0xdf, 0xff, 0xf8, 0x00, 0x00, 0x07, 0xff, 0xff, 0xff, 0xf0, 0xff, 0xff,
		0x00, 0x00, 0x07, 0xff, 0xef, 0xff, 0xf8, 0x00, 0x00, 0x0f, 0xff, 0xff, 0xff, 0xf8, 0xff, 0xff,
		0x00, 0x00, 0x07, 0xff, 0xef, 0xff, 0xfc, 0x00, 0x00, 0x0f, 0xff, 0xff, 0xff, 0xf8, 0xff, 0xff,
		0x00, 0x00, 0x0f, 0xff, 0xf7, 0xff, 0xfe, 0x00, 0x00, 0x3f, 0xff, 0xff, 0xff, 0xf9, 0xff, 0xff,
		0x00, 0x00, 0x0f, 0xff, 0xf3, 0xff, 0xff, 0x80, 0x00, 0x7f, 0xff, 0xff, 0xff, 0xf9, 0xff, 0xff,
		0x00, 0x00, 0x0f, 0xff, 0xf9, 0xff, 0xff, 0xe0, 0x01, 0xff, 0xff, 0xff, 0xff, 0xfd, 0xff, 0xff,
		0x00, 0x00, 0x0f, 0xff, 0xf8, 0xff, 0xff, 0xfc, 0x0f, 0xff, 0xff, 0xff, 0xff, 0xfd, 0xff, 0xff,
		0x00, 0x00, 0x0f, 0xff, 0xfc, 0x7f, 0xff, 0xff, 0xff, 0xff, 0xff, 0xff, 0xff, 0xfd, 0xff, 0xff,
		0x00, 0x00, 0x1f, 0xff, 0xfe, 0x3f, 0xff, 0xff, 0xff, 0xff, 0xff, 0xff, 0xff, 0xff, 0xff, 0xff,
		0x00, 0x00, 0x1f, 0xff, 0xff, 0x0f, 0xff, 0xff, 0xff, 0xff, 0xff, 0xff, 0xff, 0xff, 0xff, 0xff,
		0x00, 0x00, 0x1f, 0xff, 0xff, 0x03, 0xff, 0xff, 0xff, 0xff, 0xff, 0xff, 0xff, 0xff, 0xff, 0xff,
		0x00, 0x00, 0x1f, 0xff, 0xff, 0xf0, 0x03, 0xff, 0xff, 0xff, 0xff, 0xff, 0xff, 0xff, 0xff, 0xff,
		0x00, 0x00, 0x3f, 0xff, 0xff, 0xf8, 0x00, 0x00, 0x07, 0xff, 0xff, 0xff, 0xff, 0xff, 0xff, 0xff,
		0x00, 0x00, 0x3f, 0xff, 0xff, 0xff, 0xff, 0xff, 0xff, 0xff, 0xff, 0xff, 0xff, 0xff, 0xff, 0xff,
		0x00, 0x00, 0x3f, 0xff, 0xff, 0xff, 0xff, 0xff, 0xff, 0xff, 0xff, 0xff, 0xff, 0xff, 0xff, 0xff,
		0x00, 0x00, 0x3f, 0xff, 0xff, 0xff, 0xff, 0xff, 0xff, 0xff, 0xff, 0xff, 0xff, 0xff, 0xff, 0xff,
		0x00, 0x00, 0x7f, 0xff, 0xff, 0xff, 0xff, 0xff, 0xff, 0xff, 0xff, 0xff, 0xff, 0xff, 0xff, 0xff,
		0x00, 0x00, 0x7f, 0xff, 0xff, 0xff, 0xff, 0xff, 0xff, 0xff, 0xff, 0xff, 0xff, 0xff, 0xff, 0xff,
		0x00, 0x00, 0x7f, 0xff, 0xff, 0xff, 0xff, 0xff, 0xff, 0xff, 0xff, 0xff, 0xff, 0xff, 0xff, 0xff,
		0x00, 0x00, 0x7f, 0xff, 0xff, 0xff, 0xff, 0xff, 0xff, 0xff, 0xff, 0xff, 0xff, 0xff, 0xff, 0xff,
		0x00, 0x00, 0xff, 0xff, 0xff, 0xff, 0xff, 0xff, 0xff, 0xff, 0xff, 0xff, 0xff, 0xff, 0xff, 0xff,
		0x00, 0x00, 0xff, 0xff, 0xff, 0xff, 0xff, 0xff, 0xff, 0xff, 0xff, 0xff, 0xff, 0xff, 0xff, 0xff,
		0x00, 0x00, 0xff, 0xff, 0xff, 0xff, 0xff, 0xff, 0xff, 0xff, 0xff, 0xff, 0xff, 0xff, 0xff, 0xff,
		0x00, 0x00, 0xff, 0xff, 0xff, 0xff, 0xff, 0xff, 0xff, 0xff, 0xff, 0xff, 0xff, 0xff, 0xff, 0xff,
		0x00, 0x00, 0xff, 0xff, 0xff, 0xff, 0xff, 0xff, 0xff, 0xff, 0xff, 0xff, 0xff, 0xff, 0xff, 0xff,
		0x00, 0x01, 0xff, 0xff, 0xff, 0xff, 0xff, 0xff, 0xff, 0xff, 0xff, 0xff, 0xff, 0xff, 0xff, 0xff,
		0x00, 0x01, 0xff, 0xff, 0xff, 0xff, 0xff, 0xff, 0xff, 0xff, 0xff, 0xff, 0xff, 0xff, 0xff, 0xff,
		0x00, 0x01, 0xff, 0xff, 0xff, 0xff, 0xff, 0xff, 0xff, 0xff, 0xff, 0xff, 0xff, 0xff, 0xff, 0xff
	};
	// 'frame9', 128x64px
	const unsigned char epd_bitmap_frame9 []  = {
		0x00, 0x00, 0x00, 0x03, 0xff, 0xff, 0x00, 0x3c, 0x01, 0xff, 0xff, 0xff, 0x00, 0x00, 0x7f, 0xff,
		0x00, 0x00, 0x00, 0x03, 0xff, 0xff, 0x00, 0x3f, 0xc0, 0x3f, 0xff, 0xff, 0x00, 0x00, 0x3f, 0xff,
		0x00, 0x00, 0x00, 0x03, 0xff, 0xff, 0x00, 0x7f, 0xfc, 0x03, 0xff, 0xff, 0x80, 0x00, 0x7f, 0xff,
		0x00, 0x00, 0x00, 0x07, 0xff, 0xff, 0x00, 0x7f, 0xff, 0x80, 0x7f, 0xff, 0x80, 0x00, 0x7f, 0xff,
		0x00, 0x00, 0x00, 0x07, 0xff, 0xff, 0x00, 0x7f, 0xff, 0xf0, 0x0f, 0xff, 0xc0, 0x00, 0x3f, 0xff,
		0x00, 0x00, 0x00, 0x07, 0xff, 0xff, 0x00, 0xff, 0xff, 0xfe, 0x03, 0xff, 0xc0, 0x00, 0x3f, 0xff,
		0x00, 0x00, 0x00, 0x07, 0xff, 0xff, 0x00, 0xff, 0xff, 0xff, 0x80, 0x7f, 0xc0, 0x00, 0x7f, 0xff,
		0x00, 0x00, 0x00, 0x07, 0xff, 0xff, 0x00, 0xff, 0xff, 0xff, 0xe0, 0x1f, 0xe0, 0x00, 0x7f, 0xff,
		0x00, 0x00, 0x00, 0x0f, 0xff, 0xff, 0x00, 0xcf, 0xff, 0xff, 0xfc, 0x03, 0xe0, 0x00, 0x7f, 0xff,
		0x00, 0x00, 0x00, 0x0f, 0xff, 0xff, 0x00, 0x00, 0x01, 0xff, 0xff, 0x00, 0xe0, 0x00, 0x7f, 0xff,
		0x00, 0x00, 0x00, 0x0f, 0xff, 0xe0, 0x00, 0x7f, 0x80, 0x1f, 0xff, 0xe0, 0x00, 0x00, 0x7f, 0xff,
		0x00, 0x00, 0x00, 0x0f, 0xff, 0x00, 0x03, 0xff, 0xfe, 0x07, 0xff, 0xf8, 0x00, 0x00, 0x7f, 0xff,
		0x00, 0x00, 0x00, 0x1f, 0xf8, 0x0f, 0x03, 0xff, 0xff, 0xe0, 0xff, 0xfe, 0x00, 0x00, 0x7f, 0xff,
		0x00, 0x00, 0x00, 0x1f, 0xc0, 0x7f, 0x83, 0xff, 0xff, 0xf8, 0x3f, 0xff, 0x80, 0x00, 0x7f, 0xff,
		0x00, 0x00, 0x00, 0x1f, 0x03, 0xff, 0x87, 0xff, 0xff, 0xfe, 0x1f, 0xff, 0xe0, 0x00, 0x7f, 0xff,
		0x00, 0x00, 0x00, 0x1c, 0x0f, 0xff, 0x87, 0xff, 0xff, 0xff, 0x87, 0xff, 0xf8, 0x00, 0x7f, 0xff,
		0x00, 0x00, 0x00, 0x10, 0x3f, 0xff, 0x87, 0xff, 0xff, 0xff, 0xe3, 0xff, 0xfc, 0x00, 0x7f, 0xff,
		0x00, 0x00, 0x00, 0x00, 0xff, 0xff, 0x87, 0xfc, 0x07, 0xff, 0xf9, 0xff, 0xfc, 0x00, 0x7f, 0xff,
		0x00, 0x00, 0x00, 0x03, 0xff, 0xff, 0x8f, 0xe0, 0x00, 0xff, 0xfc, 0xff, 0xfc, 0x00, 0x7f, 0xff,
		0x00, 0x00, 0x00, 0x07, 0xff, 0xff, 0x8f, 0x80, 0x00, 0x7f, 0xfe, 0x7f, 0xfc, 0x00, 0x7f, 0xff,
		0x00, 0x00, 0x00, 0x0f, 0xff, 0xff, 0x8e, 0x00, 0x00, 0x3f, 0xff, 0x3f, 0xfe, 0x00, 0x7f, 0xff,
		0x00, 0x00, 0x00, 0x0f, 0xff, 0xff, 0xcc, 0x00, 0x00, 0x1f, 0xff, 0x9f, 0xfe, 0x00, 0x7f, 0xff,
		0x00, 0x00, 0x00, 0x27, 0xff, 0xff, 0xc8, 0x00, 0x00, 0x0f, 0xff, 0x8f, 0xfe, 0x00, 0x7f, 0xff,
		0x00, 0x00, 0x00, 0x67, 0xff, 0xff, 0xd8, 0x00, 0x00, 0x07, 0xff, 0xc7, 0xff, 0x00, 0x7f, 0xff,
		0x00, 0x00, 0x00, 0x77, 0xff, 0xff, 0xd0, 0x00, 0x00, 0x03, 0xff, 0xe7, 0xff, 0x00, 0x7f, 0xff,
		0x00, 0x00, 0x00, 0x73, 0xff, 0xff, 0xc0, 0x00, 0x00, 0x03, 0xff, 0xe3, 0xff, 0x80, 0xff, 0xff,
		0x00, 0x00, 0x00, 0x7b, 0xff, 0xff, 0xe0, 0x00, 0x00, 0x03, 0xff, 0xf1, 0xff, 0x80, 0xff, 0xff,
		0x00, 0x00, 0x00, 0x7f, 0xff, 0xff, 0xe0, 0x00, 0x00, 0x01, 0xff, 0xf0, 0xff, 0x80, 0xff, 0xff,
		0x00, 0x00, 0x00, 0xff, 0xff, 0xff, 0xe0, 0x00, 0x00, 0x01, 0xff, 0xfa, 0xff, 0x80, 0xff, 0xff,
		0x00, 0x00, 0x00, 0xff, 0xff, 0xff, 0xc0, 0x00, 0x00, 0x01, 0xff, 0xfb, 0x7f, 0xc0, 0xff, 0xff,
		0x00, 0x00, 0x00, 0xff, 0xff, 0xff, 0xc0, 0x00, 0x00, 0x01, 0xff, 0xfd, 0xff, 0xc0, 0xff, 0xff,
		0x00, 0x00, 0x00, 0xff, 0xff, 0xff, 0xc0, 0x00, 0x00, 0x3f, 0xff, 0xfd, 0xff, 0xc0, 0xff, 0xff,
		0x00, 0x00, 0x00, 0xff, 0xff, 0xff, 0xe0, 0x00, 0x00, 0x7f, 0xff, 0xfd, 0xff, 0xc0, 0xff, 0xff,
		0x00, 0x00, 0x00, 0xff, 0xff, 0xff, 0xe0, 0x00, 0x00, 0x03, 0xff, 0xff, 0xff, 0xc0, 0xff, 0xff,
		0x00, 0x00, 0x01, 0xff, 0xff, 0xff, 0xe0, 0x00, 0x00, 0x03, 0xff, 0xfe, 0xff, 0xe1, 0xff, 0xff,
		0x00, 0x00, 0x01, 0xff, 0xff, 0xff, 0xf0, 0x00, 0x00, 0x03, 0xff, 0xff, 0xff, 0xe1, 0xff, 0xff,
		0x00, 0x00, 0x01, 0xff, 0xdf, 0xff, 0xf0, 0x00, 0x00, 0x07, 0xff, 0xff, 0xff, 0xe1, 0xff, 0xff,
		0x00, 0x00, 0x01, 0xff, 0xef, 0xff, 0xf8, 0x00, 0x00, 0x0f, 0xff, 0xff, 0xff, 0xe1, 0xff, 0xff,
		0x00, 0x00, 0x01, 0xff, 0xef, 0xff, 0xfc, 0x00, 0x00, 0x0f, 0xff, 0xff, 0xff, 0xe1, 0xff, 0xff,
		0x00, 0x00, 0x03, 0xff, 0xf7, 0xff, 0xfe, 0x00, 0x00, 0x3f, 0xff, 0xff, 0xff, 0xf3, 0xff, 0xff,
		0x00, 0x00, 0x03, 0xff, 0xf3, 0xff, 0xff, 0x00, 0x00, 0x7f, 0xff, 0xff, 0xff, 0xf3, 0xff, 0xff,
		0x00, 0x00, 0x03, 0xff, 0xf9, 0xff, 0xff, 0xc0, 0x01, 0xff, 0xff, 0xff, 0xff, 0xf3, 0xff, 0xff,
		0x00, 0x00, 0x03, 0xff, 0xf8, 0xff, 0xff, 0xf8, 0x0f, 0xff, 0xff, 0xff, 0xff, 0xf3, 0xff, 0xff,
		0x00, 0x00, 0x03, 0xff, 0xfc, 0x7f, 0xff, 0xff, 0xff, 0xff, 0xff, 0xff, 0xff, 0xf3, 0xff, 0xff,
		0x00, 0x00, 0x07, 0xff, 0xfe, 0x3f, 0xff, 0xff, 0xff, 0xff, 0xff, 0xff, 0xff, 0xf7, 0xff, 0xff,
		0x00, 0x00, 0x07, 0xff, 0xff, 0x1f, 0xff, 0xff, 0xff, 0xff, 0xff, 0xff, 0xff, 0xff, 0xff, 0xff,
		0x00, 0x00, 0x07, 0xff, 0xfe, 0x03, 0xff, 0xff, 0xff, 0xff, 0xff, 0xff, 0xff, 0xff, 0xff, 0xff,
		0x00, 0x00, 0x07, 0xff, 0xff, 0xf0, 0x00, 0x7f, 0xff, 0xff, 0xff, 0xff, 0xff, 0xff, 0xff, 0xff,
		0x00, 0x00, 0x07, 0xff, 0xff, 0xf8, 0x01, 0x3f, 0xff, 0xff, 0xff, 0xff, 0xff, 0xff, 0xff, 0xff,
		0x00, 0x00, 0x07, 0xff, 0xff, 0xff, 0xff, 0xff, 0xff, 0xff, 0xff, 0xff, 0xff, 0xff, 0xff, 0xff,
		0x00, 0x00, 0x0f, 0xff, 0xff, 0xff, 0xff, 0xff, 0xff, 0xff, 0xff, 0xff, 0xff, 0xff, 0xff, 0xff,
		0x00, 0x00, 0x0f, 0xff, 0xff, 0xff, 0xff, 0xff, 0xff, 0xff, 0xff, 0xff, 0xff, 0xff, 0xff, 0xff,
		0x00, 0x00, 0x0f, 0xff, 0xff, 0xff, 0xff, 0xff, 0xff, 0xff, 0xff, 0xff, 0xff, 0xff, 0xff, 0xff,
		0x00, 0x00, 0x0f, 0xff, 0xff, 0xff, 0xff, 0xff, 0xff, 0xff, 0xff, 0xff, 0xff, 0xff, 0xff, 0xff,
		0x00, 0x00, 0x1f, 0xff, 0xff, 0xff, 0xff, 0xff, 0xff, 0xff, 0xff, 0xff, 0xff, 0xff, 0xff, 0xff,
		0x00, 0x00, 0x1f, 0xff, 0xff, 0xff, 0xff, 0xff, 0xff, 0xff, 0xff, 0xff, 0xff, 0xff, 0xff, 0xff,
		0x00, 0x00, 0x1f, 0xff, 0xff, 0xff, 0xff, 0xff, 0xff, 0xff, 0xff, 0xff, 0xff, 0xff, 0xff, 0xff,
		0x00, 0x00, 0x1f, 0xff, 0xff, 0xff, 0xff, 0xff, 0xff, 0xff, 0xff, 0xff, 0xff, 0xff, 0xff, 0xff,
		0x00, 0x00, 0x3f, 0xff, 0xff, 0xff, 0xff, 0xff, 0xff, 0xff, 0xff, 0xff, 0xff, 0xff, 0xff, 0xff,
		0x00, 0x00, 0x3f, 0xff, 0xff, 0xff, 0xff, 0xff, 0xff, 0xff, 0xff, 0xff, 0xff, 0xff, 0xff, 0xff,
		0x00, 0x00, 0x3f, 0xff, 0xff, 0xff, 0xff, 0xff, 0xff, 0xff, 0xff, 0xff, 0xff, 0xff, 0xff, 0xff,
		0x00, 0x00, 0x3f, 0xff, 0xff, 0xff, 0xff, 0xff, 0xff, 0xff, 0xff, 0xff, 0xff, 0xff, 0xff, 0xff,
		0x00, 0x00, 0x3f, 0xff, 0xff, 0xff, 0xff, 0xff, 0xff, 0xff, 0xff, 0xff, 0xff, 0xff, 0xff, 0xff,
		0x00, 0x00, 0x7f, 0xff, 0xff, 0xff, 0xff, 0xff, 0xff, 0xff, 0xff, 0xff, 0xff, 0xff, 0xff, 0xff
	};
	// 'frame10', 128x64px
	const unsigned char epd_bitmap_frame10 []  = {
		0x00, 0x00, 0x00, 0x03, 0xff, 0xff, 0x80, 0x01, 0xff, 0xff, 0xff, 0xe0, 0x00, 0x01, 0xff, 0xff,
		0x00, 0x00, 0x00, 0x07, 0xff, 0xff, 0x80, 0x00, 0x3f, 0xff, 0xff, 0xf0, 0x00, 0x03, 0xff, 0xff,
		0x00, 0x00, 0x00, 0x03, 0xff, 0xff, 0x80, 0x1c, 0x07, 0xff, 0xff, 0xf0, 0x00, 0x07, 0xff, 0xff,
		0x00, 0x00, 0x00, 0x03, 0xff, 0xff, 0x80, 0x1f, 0x80, 0xff, 0xff, 0xf0, 0x00, 0x07, 0xff, 0xff,
		0x00, 0x00, 0x00, 0x07, 0xff, 0xff, 0x80, 0x3f, 0xf0, 0x1f, 0xff, 0xf0, 0x00, 0x07, 0xff, 0xff,
		0x00, 0x00, 0x00, 0x0f, 0xff, 0xff, 0xc0, 0x3f, 0xfe, 0x03, 0xff, 0xf0, 0x00, 0x03, 0xff, 0xff,
		0x00, 0x00, 0x00, 0x07, 0xff, 0xff, 0xc0, 0x3f, 0xff, 0x80, 0xff, 0xf8, 0x00, 0x03, 0xff, 0xff,
		0x00, 0x00, 0x00, 0x07, 0xff, 0xff, 0xc0, 0x3f, 0xff, 0xf0, 0x1f, 0xf8, 0x00, 0x03, 0xff, 0xff,
		0x00, 0x00, 0x00, 0x07, 0xff, 0xff, 0xc0, 0x7f, 0xff, 0xfc, 0x03, 0xf8, 0x00, 0x03, 0xff, 0xff,
		0x00, 0x00, 0x00, 0x07, 0xff, 0xff, 0xc0, 0x3f, 0xff, 0xff, 0x00, 0xfc, 0x00, 0x03, 0xff, 0xff,
		0x00, 0x00, 0x00, 0x0f, 0xff, 0xfe, 0x00, 0x00, 0x07, 0xff, 0xc0, 0x1c, 0x00, 0x07, 0xff, 0xff,
		0x00, 0x00, 0x00, 0x0f, 0xff, 0xc0, 0x00, 0x00, 0x00, 0x7f, 0xf8, 0x00, 0x00, 0x07, 0xff, 0xff,
		0x00, 0x00, 0x00, 0x0f, 0xfc, 0x00, 0xc0, 0x7f, 0xf8, 0x0f, 0xfe, 0x00, 0x00, 0x07, 0xff, 0xff,
		0x00, 0x00, 0x00, 0x0f, 0xe0, 0x1f, 0xe0, 0xff, 0xff, 0x81, 0xff, 0x80, 0x00, 0x07, 0xff, 0xff,
		0x00, 0x00, 0x00, 0x0f, 0x00, 0xff, 0xe0, 0xff, 0xff, 0xf0, 0xff, 0xf0, 0x00, 0x0f, 0xff, 0xff,
		0x00, 0x00, 0x00, 0x0c, 0x07, 0xff, 0xe0, 0xff, 0xff, 0xfe, 0x3f, 0xfc, 0x00, 0x07, 0xff, 0xff,
		0x00, 0x00, 0x00, 0x00, 0x3f, 0xff, 0xe0, 0xff, 0xff, 0xff, 0x8f, 0xfe, 0x00, 0x0f, 0xff, 0xff,
		0x00, 0x00, 0x00, 0x00, 0xff, 0xff, 0xe1, 0xff, 0xff, 0xff, 0xc7, 0xfe, 0x00, 0x0f, 0xff, 0xff,
		0x00, 0x00, 0x00, 0x03, 0xff, 0xff, 0xf1, 0xc0, 0x07, 0xff, 0xe3, 0xff, 0x00, 0x07, 0xff, 0xff,
		0x00, 0x00, 0x00, 0x0f, 0xff, 0xff, 0xf0, 0x00, 0x01, 0xff, 0xf1, 0xff, 0x00, 0x01, 0xff, 0xff,
		0x00, 0x00, 0x00, 0x1f, 0xff, 0xff, 0xf0, 0x00, 0x00, 0xff, 0xf8, 0xff, 0x00, 0x03, 0xff, 0xff,
		0x00, 0x00, 0x00, 0x1f, 0xff, 0xff, 0xf0, 0x00, 0x00, 0x3f, 0xfc, 0x7f, 0x00, 0x0f, 0xff, 0xff,
		0x00, 0x00, 0x00, 0x1f, 0xff, 0xff, 0xf0, 0x00, 0x00, 0x1f, 0xfe, 0x3f, 0x80, 0x0f, 0xff, 0xff,
		0x00, 0x00, 0x00, 0x1f, 0xff, 0xff, 0xe0, 0x00, 0x00, 0x1f, 0xff, 0x1f, 0x80, 0x0f, 0xff, 0xff,
		0x00, 0x00, 0x00, 0x1f, 0xff, 0xff, 0xc0, 0x00, 0x00, 0x0f, 0xff, 0x1f, 0x80, 0x0f, 0xff, 0xff,
		0x00, 0x00, 0x00, 0x1f, 0xff, 0xff, 0xc0, 0x00, 0x00, 0x07, 0xff, 0x8f, 0xc0, 0x0f, 0xff, 0xff,
		0x00, 0x00, 0x00, 0x0f, 0xff, 0xff, 0x80, 0x00, 0x00, 0x07, 0xff, 0xc7, 0xc0, 0x1f, 0xff, 0xff,
		0x00, 0x00, 0x00, 0x3f, 0xff, 0xff, 0x80, 0x00, 0x00, 0x07, 0xff, 0xc3, 0xc0, 0x1f, 0xff, 0xff,
		0x00, 0x00, 0x00, 0x3f, 0xff, 0xff, 0x80, 0x00, 0x00, 0x07, 0xff, 0xeb, 0xc0, 0x1f, 0xff, 0xff,
		0x00, 0x00, 0x00, 0x3f, 0xff, 0xff, 0x80, 0x00, 0x00, 0x07, 0xff, 0xed, 0xe0, 0x1f, 0xff, 0xff,
		0x00, 0x00, 0x00, 0x3f, 0xff, 0xff, 0x80, 0x00, 0x00, 0x07, 0xff, 0xf7, 0xe0, 0x1f, 0xff, 0xff,
		0x00, 0x00, 0x00, 0x7f, 0xff, 0xff, 0x80, 0x00, 0x00, 0x07, 0xff, 0xf7, 0xe0, 0x1f, 0xff, 0xff,
		0x00, 0x00, 0x00, 0x7f, 0xff, 0xff, 0x80, 0x00, 0x00, 0xff, 0xff, 0xff, 0xe0, 0x3f, 0xff, 0xff,
		0x00, 0x00, 0x00, 0x7f, 0xff, 0xff, 0x80, 0x00, 0x00, 0x0f, 0xff, 0xfb, 0xe0, 0x3f, 0xff, 0xff,
		0x00, 0x00, 0x00, 0x7f, 0xff, 0xff, 0x80, 0x00, 0x00, 0x07, 0xff, 0xff, 0xf0, 0x3f, 0xff, 0xff,
		0x00, 0x00, 0x00, 0x7f, 0xff, 0xff, 0xc0, 0x00, 0x00, 0x0f, 0xff, 0xff, 0xf0, 0x3f, 0xff, 0xff,
		0x00, 0x00, 0x00, 0x7f, 0x7f, 0xff, 0xc0, 0x00, 0x00, 0x0f, 0xff, 0xff, 0xf0, 0x3f, 0xff, 0xff,
		0x00, 0x00, 0x00, 0x7f, 0xbf, 0xff, 0xe0, 0x00, 0x00, 0x1f, 0xff, 0xff, 0xf0, 0x3f, 0xff, 0xff,
		0x00, 0x00, 0x00, 0xff, 0x9f, 0xff, 0xf0, 0x00, 0x00, 0x3f, 0xff, 0xff, 0xf8, 0x3f, 0xff, 0xff,
		0x00, 0x00, 0x00, 0xff, 0xcf, 0xff, 0xf8, 0x00, 0x00, 0x7f, 0xff, 0xff, 0xf8, 0x7f, 0xff, 0xff,
		0x00, 0x00, 0x00, 0xff, 0xcf, 0xff, 0xfc, 0x00, 0x00, 0xff, 0xff, 0xff, 0xf8, 0x7f, 0xff, 0xff,
		0x00, 0x00, 0x00, 0xff, 0xe3, 0xff, 0xfe, 0x00, 0x03, 0xff, 0xff, 0xff, 0xf8, 0x7f, 0xff, 0xff,
		0x00, 0x00, 0x00, 0xff, 0xe3, 0xff, 0xff, 0x80, 0x0f, 0xff, 0xff, 0xff, 0xf8, 0x7f, 0xff, 0xff,
		0x00, 0x00, 0x00, 0xff, 0xd0, 0xff, 0xff, 0xff, 0xff, 0xff, 0xff, 0xff, 0xf8, 0x7f, 0xff, 0xff,
		0x00, 0x00, 0x00, 0xff, 0xf8, 0x7f, 0xff, 0xff, 0xff, 0xff, 0xff, 0xff, 0xfc, 0xff, 0xff, 0xff,
		0x00, 0x00, 0x00, 0xff, 0xfc, 0x3f, 0xff, 0xff, 0xff, 0xff, 0xff, 0xff, 0xfc, 0xff, 0xff, 0xff,
		0x00, 0x00, 0x01, 0xff, 0xf8, 0x07, 0xff, 0xff, 0xff, 0xff, 0xff, 0xff, 0xff, 0xff, 0xff, 0xff,
		0x00, 0x00, 0x01, 0xff, 0xff, 0xe0, 0x00, 0x01, 0x80, 0x09, 0xff, 0xff, 0xff, 0xff, 0xff, 0xff,
		0x00, 0x00, 0x01, 0xff, 0xff, 0xff, 0xfc, 0x03, 0xff, 0xff, 0xff, 0xff, 0xff, 0xff, 0xff, 0xff,
		0x00, 0x00, 0x01, 0xff, 0xff, 0xff, 0xff, 0xff, 0xff, 0xff, 0xff, 0xff, 0xff, 0xff, 0xff, 0xff,
		0x00, 0x00, 0x01, 0xff, 0xff, 0xff, 0xff, 0xff, 0xff, 0xff, 0xff, 0xff, 0xff, 0xff, 0xff, 0xff,
		0x00, 0x00, 0x01, 0xff, 0xff, 0xff, 0xff, 0xff, 0xff, 0xff, 0xff, 0xff, 0xff, 0xff, 0xff, 0xff,
		0x00, 0x00, 0x03, 0xff, 0xff, 0xff, 0xff, 0xff, 0xff, 0xff, 0xff, 0xff, 0xff, 0xff, 0xff, 0xff,
		0x00, 0x00, 0x03, 0xff, 0xff, 0xff, 0xff, 0xff, 0xff, 0xff, 0xff, 0xff, 0xff, 0xff, 0xff, 0xff,
		0x00, 0x00, 0x03, 0xff, 0xff, 0xff, 0xff, 0xff, 0xff, 0xff, 0xff, 0xff, 0xff, 0xff, 0xff, 0xff,
		0x00, 0x00, 0x03, 0xff, 0xff, 0xff, 0xff, 0xff, 0xff, 0xff, 0xff, 0xff, 0xff, 0xff, 0xff, 0xff,
		0x00, 0x00, 0x03, 0xff, 0xff, 0xff, 0xff, 0xff, 0xff, 0xff, 0xff, 0xff, 0xff, 0xff, 0xff, 0xff,
		0x00, 0x00, 0x03, 0xff, 0xff, 0xff, 0xff, 0xff, 0xff, 0xff, 0xff, 0xff, 0xff, 0xff, 0xff, 0xff,
		0x00, 0x00, 0x03, 0xff, 0xff, 0xff, 0xff, 0xff, 0xff, 0xff, 0xff, 0xff, 0xff, 0xff, 0xff, 0xff,
		0x00, 0x00, 0x03, 0xff, 0xff, 0xff, 0xff, 0xff, 0xff, 0xff, 0xff, 0xff, 0xff, 0xff, 0xff, 0xff,
		0x00, 0x00, 0x03, 0xff, 0xff, 0xff, 0xff, 0xff, 0xff, 0xff, 0xff, 0xff, 0xff, 0xff, 0xff, 0xff,
		0x00, 0x00, 0x07, 0xff, 0xff, 0xff, 0xff, 0xff, 0xff, 0xff, 0xff, 0xff, 0xff, 0xff, 0xff, 0xff,
		0x00, 0x00, 0x03, 0xff, 0xff, 0xff, 0xff, 0xff, 0xff, 0xff, 0xff, 0xff, 0xff, 0xff, 0xff, 0xff,
		0x00, 0x00, 0x03, 0xff, 0xff, 0xff, 0xff, 0xff, 0xff, 0xff, 0xff, 0xff, 0xff, 0xff, 0xff, 0xff
	};
	// 'frame11', 128x64px
	const unsigned char epd_bitmap_frame11 []  = {
		0x00, 0x00, 0x00, 0x07, 0xff, 0xff, 0xc0, 0x03, 0xff, 0xff, 0xff, 0x80, 0x00, 0x03, 0xff, 0xfe,
		0x00, 0x00, 0x00, 0x07, 0xff, 0xff, 0xc0, 0x00, 0x7f, 0xff, 0xff, 0xc0, 0x00, 0x07, 0xff, 0xff,
		0x00, 0x00, 0x00, 0x07, 0xff, 0xff, 0xc0, 0x00, 0x0f, 0xff, 0xff, 0x80, 0x00, 0x07, 0xff, 0xff,
		0x00, 0x00, 0x00, 0x37, 0xff, 0xff, 0xc0, 0x0f, 0x01, 0xff, 0xff, 0xc0, 0x00, 0x0f, 0xff, 0xff,
		0x00, 0x00, 0x00, 0x1f, 0xff, 0xff, 0xc0, 0x0f, 0xe0, 0x3f, 0xff, 0xc0, 0x00, 0x0f, 0xff, 0xff,
		0x00, 0x00, 0x00, 0x0f, 0xff, 0xff, 0xc0, 0x0f, 0xf8, 0x07, 0xff, 0xc0, 0x00, 0x1f, 0xff, 0xff,
		0x00, 0x00, 0x00, 0x07, 0xff, 0xff, 0xe0, 0x0f, 0xff, 0x00, 0xff, 0xc0, 0x00, 0x0f, 0xff, 0xff,
		0x00, 0x00, 0x00, 0x07, 0xff, 0xff, 0xe0, 0x1f, 0xff, 0xc0, 0x3f, 0xe0, 0x00, 0x07, 0xff, 0xff,
		0x00, 0x00, 0x00, 0x07, 0xff, 0xff, 0xe0, 0x1f, 0xff, 0xf8, 0x0f, 0xe0, 0x00, 0x0f, 0xff, 0xff,
		0x00, 0x00, 0x00, 0x07, 0xff, 0xff, 0xe0, 0x0f, 0xff, 0xfe, 0x01, 0xe0, 0x00, 0x0f, 0xff, 0xff,
		0x00, 0x00, 0x40, 0x07, 0xff, 0xfe, 0x00, 0x00, 0x03, 0xff, 0xc0, 0x20, 0x00, 0x0f, 0xff, 0xff,
		0x00, 0x00, 0x38, 0x0f, 0xff, 0xc0, 0x00, 0x00, 0x00, 0x7f, 0xf0, 0x00, 0x00, 0x0f, 0xff, 0xff,
		0x00, 0x00, 0x0e, 0x0f, 0xfc, 0x00, 0xe0, 0x3f, 0xf8, 0x0f, 0xfc, 0x00, 0x00, 0x0f, 0xff, 0xff,
		0x00, 0x00, 0x03, 0x8f, 0xc0, 0x1f, 0xe0, 0x3f, 0xff, 0x81, 0xff, 0x80, 0x00, 0x0f, 0xff, 0xff,
		0x00, 0x00, 0x00, 0x0f, 0x00, 0xff, 0xf0, 0x3f, 0xff, 0xf0, 0xff, 0xe0, 0x00, 0x1f, 0xff, 0xff,
		0x00, 0x00, 0x00, 0x00, 0x07, 0xff, 0xf0, 0x3f, 0xff, 0xfc, 0x3f, 0xf0, 0x00, 0x1f, 0xff, 0xff,
		0x00, 0x00, 0x00, 0x00, 0x3f, 0xff, 0xf0, 0x7f, 0xff, 0xff, 0x1f, 0xf8, 0x00, 0x1f, 0xff, 0xff,
		0x00, 0x00, 0x00, 0x01, 0xff, 0xff, 0xf0, 0x78, 0x1f, 0xff, 0xc7, 0xf8, 0x00, 0x1f, 0xff, 0xff,
		0x00, 0x00, 0x00, 0x07, 0xff, 0xff, 0xf0, 0x00, 0x03, 0xff, 0xe3, 0xf8, 0x00, 0x1f, 0xff, 0xff,
		0x00, 0x00, 0x00, 0x0f, 0xff, 0xff, 0xf8, 0x00, 0x00, 0xff, 0xf1, 0xfc, 0x00, 0x01, 0xff, 0xff,
		0x00, 0x00, 0x00, 0x1f, 0xff, 0xff, 0xf8, 0x00, 0x00, 0x7f, 0xf8, 0xfc, 0x00, 0x03, 0xff, 0xff,
		0x00, 0x00, 0x00, 0x1f, 0xff, 0xff, 0xf8, 0x00, 0x00, 0x3f, 0xfc, 0x7c, 0x00, 0x1f, 0xff, 0xff,
		0x00, 0x00, 0x00, 0x1f, 0xff, 0xff, 0xf0, 0x00, 0x00, 0x1f, 0xfe, 0x3e, 0x00, 0x1f, 0xff, 0xff,
		0x00, 0x00, 0x00, 0x1f, 0xff, 0xff, 0xe0, 0x00, 0x00, 0x1f, 0xff, 0x3e, 0x00, 0x3f, 0xff, 0xff,
		0x00, 0x00, 0x00, 0x1f, 0xff, 0xff, 0xc0, 0x00, 0x00, 0x0f, 0xff, 0x1e, 0x00, 0x3f, 0xff, 0xff,
		0x00, 0x00, 0x00, 0x1f, 0xff, 0xff, 0x80, 0x00, 0x00, 0x0f, 0xff, 0x8f, 0x00, 0x3f, 0xff, 0xff,
		0x00, 0x00, 0x00, 0x1f, 0xff, 0xff, 0x80, 0x00, 0x00, 0x07, 0xff, 0xc7, 0x00, 0x3f, 0xff, 0xff,
		0x00, 0x00, 0x00, 0x0f, 0xff, 0xff, 0x00, 0x00, 0x00, 0x07, 0xff, 0xc7, 0x00, 0x7f, 0xff, 0xff,
		0x00, 0x00, 0x00, 0x1f, 0xff, 0xff, 0x00, 0x00, 0x00, 0x07, 0xff, 0xeb, 0x00, 0x7f, 0xff, 0xff,
		0x00, 0x00, 0x00, 0x1f, 0xff, 0xff, 0x00, 0x00, 0x00, 0x07, 0xff, 0xed, 0x80, 0x7f, 0xff, 0xff,
		0x00, 0x00, 0x00, 0x1f, 0xff, 0xff, 0x00, 0x00, 0x00, 0x07, 0xff, 0xf5, 0x80, 0x7f, 0xff, 0xff,
		0x00, 0x00, 0x00, 0x3f, 0xff, 0xff, 0x00, 0x00, 0x00, 0x0f, 0xff, 0xf6, 0x80, 0x7f, 0xff, 0xff,
		0x00, 0x00, 0x00, 0x3f, 0xff, 0xff, 0x00, 0x00, 0x00, 0x7f, 0xff, 0xf7, 0x80, 0x7f, 0xff, 0xff,
		0x00, 0x00, 0x00, 0x3f, 0xff, 0xff, 0x80, 0x00, 0x00, 0x0f, 0xff, 0xfb, 0xc0, 0xff, 0xff, 0xff,
		0x00, 0x00, 0x00, 0x3f, 0xff, 0xff, 0x80, 0x00, 0x00, 0x07, 0xff, 0xfb, 0xc0, 0xff, 0xff, 0xff,
		0x00, 0x00, 0x00, 0x3f, 0xff, 0xff, 0x80, 0x00, 0x00, 0x0f, 0xff, 0xff, 0xc0, 0xff, 0xff, 0xff,
		0x00, 0x00, 0x00, 0x3f, 0x7f, 0xff, 0xc0, 0x00, 0x00, 0x0f, 0xff, 0xff, 0xc0, 0xff, 0xff, 0xff,
		0x00, 0x00, 0x00, 0x3f, 0x3f, 0xff, 0xc0, 0x00, 0x00, 0x1f, 0xff, 0xff, 0xe0, 0xff, 0xff, 0xff,
		0x00, 0x00, 0x00, 0x3f, 0x9f, 0xff, 0xe0, 0x00, 0x00, 0x3f, 0xff, 0xff, 0xe1, 0xff, 0xff, 0xff,
		0x00, 0x00, 0x00, 0x3f, 0xcf, 0xff, 0xf0, 0x00, 0x00, 0x7f, 0xff, 0xff, 0xe1, 0xff, 0xff, 0xff,
		0x00, 0x00, 0x00, 0x3f, 0xc7, 0xff, 0xfc, 0x00, 0x00, 0xff, 0xff, 0xff, 0xe1, 0xff, 0xff, 0xff,
		0x00, 0x00, 0x00, 0x3f, 0xe7, 0xff, 0xfe, 0x00, 0x03, 0xff, 0xff, 0xff, 0xe1, 0xff, 0xff, 0xff,
		0x00, 0x00, 0x00, 0x7f, 0xc3, 0xff, 0xff, 0xc0, 0x0f, 0xff, 0xff, 0xff, 0xe1, 0xff, 0xff, 0xff,
		0x00, 0x00, 0x00, 0x7f, 0xd1, 0xff, 0xff, 0xff, 0xff, 0xff, 0xff, 0xff, 0xf1, 0xff, 0xff, 0xff,
		0x00, 0x00, 0x00, 0x7f, 0xf8, 0x7f, 0xff, 0xff, 0xff, 0xff, 0xff, 0xff, 0xf1, 0xff, 0xff, 0xff,
		0x00, 0x00, 0x00, 0x7f, 0xfc, 0x1f, 0xff, 0xff, 0xff, 0xff, 0xff, 0xff, 0xf3, 0xff, 0xff, 0xff,
		0x00, 0x00, 0x00, 0x7f, 0xfe, 0x00, 0x7f, 0xff, 0xff, 0xff, 0xff, 0xff, 0xfb, 0xff, 0xff, 0xff,
		0x00, 0x00, 0x00, 0x7f, 0xff, 0xc0, 0x00, 0x00, 0x00, 0x1b, 0xff, 0xff, 0xff, 0xff, 0xff, 0xff,
		0x00, 0x00, 0x00, 0x7f, 0xff, 0xff, 0xff, 0xff, 0xff, 0xff, 0xff, 0xff, 0xff, 0xff, 0xff, 0xff,
		0x00, 0x00, 0x00, 0x7f, 0xff, 0xff, 0xff, 0xff, 0xff, 0xff, 0xff, 0xff, 0xff, 0xff, 0xff, 0xff,
		0x00, 0x00, 0x00, 0xff, 0xff, 0xff, 0xff, 0xff, 0xff, 0xff, 0xff, 0xff, 0xff, 0xff, 0xff, 0xff,
		0x00, 0x00, 0x00, 0xff, 0xff, 0xff, 0xff, 0xff, 0xff, 0xff, 0xff, 0xff, 0xff, 0xff, 0xff, 0xff,
		0x00, 0x00, 0x01, 0xff, 0xff, 0xff, 0xff, 0xff, 0xff, 0xff, 0xff, 0xff, 0xff, 0xff, 0xff, 0xff,
		0x00, 0x00, 0x01, 0xff, 0xff, 0xff, 0xff, 0xff, 0xff, 0xff, 0xff, 0xff, 0xff, 0xff, 0xff, 0xff,
		0x00, 0x00, 0x00, 0xff, 0xff, 0xff, 0xff, 0xff, 0xff, 0xff, 0xff, 0xff, 0xff, 0xff, 0xff, 0xff,
		0x00, 0x00, 0x00, 0xff, 0xff, 0xff, 0xff, 0xff, 0xff, 0xff, 0xff, 0xff, 0xff, 0xff, 0xff, 0xff,
		0x00, 0x00, 0x00, 0xff, 0xff, 0xff, 0xff, 0xff, 0xff, 0xff, 0xff, 0xff, 0xff, 0xff, 0xff, 0xff,
		0x00, 0x00, 0x00, 0xff, 0xff, 0xff, 0xff, 0xff, 0xff, 0xff, 0xff, 0xff, 0xff, 0xff, 0xff, 0xff,
		0x00, 0x00, 0x01, 0xff, 0xff, 0xff, 0xff, 0xff, 0xff, 0xff, 0xff, 0xff, 0xff, 0xff, 0xff, 0xff,
		0x00, 0x00, 0x01, 0xff, 0xff, 0xff, 0xff, 0xff, 0xff, 0xff, 0xff, 0xff, 0xff, 0xff, 0xff, 0xff,
		0x00, 0x00, 0x01, 0xff, 0xff, 0xff, 0xff, 0xff, 0xff, 0xff, 0xff, 0xff, 0xff, 0xff, 0xff, 0xff,
		0x00, 0x00, 0x03, 0xff, 0xff, 0xff, 0xff, 0xff, 0xff, 0xff, 0xff, 0xff, 0xff, 0xff, 0xff, 0xff,
		0x00, 0x00, 0x03, 0xff, 0xff, 0xff, 0xff, 0xff, 0xff, 0xff, 0xff, 0xff, 0xff, 0xff, 0xff, 0xff,
		0x00, 0x00, 0x03, 0xff, 0xff, 0xff, 0xff, 0xff, 0xff, 0xff, 0xff, 0xff, 0xff, 0xff, 0xff, 0xff
	};
	// 'frame12', 128x64px
	const unsigned char epd_bitmap_frame12 []  = {
		0x00, 0x00, 0x00, 0x03, 0xff, 0xff, 0xc0, 0x00, 0xff, 0xff, 0xff, 0x80, 0x00, 0x0f, 0xff, 0xff,
		0x00, 0x00, 0x00, 0x07, 0xff, 0xff, 0xc0, 0x00, 0x1f, 0xff, 0xff, 0x80, 0x00, 0x0f, 0xff, 0xff,
		0x00, 0x00, 0x00, 0x07, 0xff, 0xff, 0xc0, 0x0e, 0x03, 0xff, 0xff, 0xc0, 0x00, 0x1f, 0xff, 0xff,
		0x00, 0x00, 0x00, 0x07, 0xff, 0xff, 0xc0, 0x0f, 0x80, 0x7f, 0xff, 0xc0, 0x00, 0x07, 0xff, 0xff,
		0x00, 0x00, 0x00, 0x07, 0xff, 0xff, 0xc0, 0x0f, 0xf0, 0x0f, 0xff, 0xc0, 0x00, 0x0f, 0xff, 0xff,
		0x00, 0x00, 0x00, 0x07, 0xff, 0xff, 0xe0, 0x0f, 0xfc, 0x03, 0xff, 0xc0, 0x00, 0x0f, 0xff, 0xff,
		0x00, 0x00, 0x00, 0x07, 0xff, 0xff, 0xe0, 0x1f, 0xff, 0x80, 0x7f, 0xe0, 0x00, 0x0f, 0xff, 0xff,
		0x00, 0x00, 0x00, 0x07, 0xff, 0xff, 0xe0, 0x1f, 0xff, 0xf0, 0x1f, 0xe0, 0x00, 0x1f, 0xff, 0xff,
		0x00, 0x00, 0x00, 0x07, 0xff, 0xff, 0xe0, 0x1f, 0xff, 0xfe, 0x03, 0xe0, 0x00, 0x1f, 0xff, 0xff,
		0x00, 0x00, 0x00, 0x07, 0xff, 0xff, 0x80, 0x00, 0x0f, 0xff, 0x80, 0xe0, 0x00, 0x1f, 0xff, 0xff,
		0x00, 0x00, 0x00, 0x0f, 0xff, 0xe0, 0x00, 0x00, 0x00, 0xff, 0xe0, 0x20, 0x00, 0x0f, 0xff, 0xff,
		0x00, 0x00, 0x00, 0x0f, 0xfe, 0x00, 0x60, 0x3f, 0xc0, 0x1f, 0xf8, 0x00, 0x00, 0x0f, 0xff, 0xff,
		0x00, 0x00, 0x00, 0x0f, 0xe0, 0x0f, 0xf0, 0x3f, 0xff, 0x07, 0xff, 0x00, 0x00, 0x0f, 0xff, 0xff,
		0x00, 0x00, 0x00, 0x0f, 0x00, 0xff, 0xf0, 0x3f, 0xff, 0xe0, 0xff, 0x80, 0x00, 0x0f, 0xff, 0xff,
		0x00, 0x00, 0x00, 0x0c, 0x07, 0xff, 0xf0, 0x3f, 0xff, 0xfc, 0x3f, 0xf0, 0x00, 0x0f, 0xff, 0xff,
		0x00, 0x00, 0x00, 0x00, 0x3f, 0xff, 0xf0, 0x7f, 0xff, 0xff, 0x1f, 0xf8, 0x00, 0x1f, 0xff, 0xff,
		0x00, 0x00, 0x00, 0x01, 0xff, 0xff, 0xf0, 0x60, 0x1f, 0xff, 0x8f, 0xf8, 0x00, 0x3f, 0xff, 0xff,
		0x00, 0x00, 0x00, 0x0f, 0xff, 0xff, 0xf0, 0x00, 0x03, 0xff, 0xe7, 0xf8, 0x00, 0x1f, 0xff, 0xff,
		0x00, 0x00, 0x00, 0x1f, 0xff, 0xff, 0xf8, 0x00, 0x01, 0xff, 0xf1, 0xf8, 0x00, 0x0f, 0xff, 0xff,
		0x00, 0x00, 0x00, 0x1f, 0xff, 0xff, 0xf8, 0x00, 0x00, 0x7f, 0xf8, 0xfc, 0x00, 0x01, 0xff, 0xff,
		0x00, 0x00, 0x00, 0x1f, 0xff, 0xff, 0xf0, 0x00, 0x00, 0x3f, 0xfc, 0x7c, 0x00, 0x07, 0xff, 0xff,
		0x00, 0x00, 0x00, 0x1f, 0xff, 0xff, 0xe0, 0x00, 0x00, 0x1f, 0xfe, 0x7e, 0x00, 0x3f, 0xff, 0xff,
		0x00, 0x00, 0x00, 0x1f, 0xff, 0xff, 0xc0, 0x00, 0x00, 0x1f, 0xff, 0x3e, 0x00, 0x3f, 0xff, 0xff,
		0x00, 0x00, 0x00, 0x1f, 0xff, 0xff, 0xc0, 0x00, 0x00, 0x0f, 0xff, 0x1e, 0x00, 0x3f, 0xff, 0xff,
		0x00, 0x00, 0x00, 0x1f, 0xff, 0xff, 0x80, 0x00, 0x00, 0x0f, 0xff, 0x8e, 0x00, 0x3f, 0xff, 0xff,
		0x00, 0x00, 0x00, 0x1f, 0xff, 0xff, 0x80, 0x00, 0x00, 0x07, 0xff, 0xcf, 0x00, 0x3f, 0xff, 0xff,
		0x00, 0x00, 0x00, 0x1f, 0xff, 0xff, 0x00, 0x00, 0x00, 0x07, 0xff, 0xc7, 0x00, 0x7f, 0xff, 0xff,
		0x00, 0x00, 0x00, 0x1f, 0xff, 0xff, 0x00, 0x00, 0x00, 0x07, 0xff, 0xeb, 0x00, 0x7f, 0xff, 0xff,
		0x00, 0x00, 0x00, 0x3f, 0xff, 0xff, 0x00, 0x00, 0x00, 0x07, 0xff, 0xef, 0x00, 0x7f, 0xff, 0xff,
		0x00, 0x00, 0x00, 0x3f, 0xff, 0xff, 0x00, 0x00, 0x00, 0x07, 0xff, 0xf5, 0x80, 0x7f, 0xff, 0xff,
		0x00, 0x00, 0x00, 0x3f, 0xff, 0xff, 0x00, 0x00, 0x00, 0x07, 0xff, 0xf7, 0x80, 0x7f, 0xff, 0xff,
		0x00, 0x00, 0x00, 0x3f, 0xff, 0xff, 0x00, 0x00, 0x81, 0xff, 0xff, 0xf7, 0x80, 0x7f, 0xff, 0xff,
		0x00, 0x00, 0x00, 0x3f, 0xff, 0xff, 0x00, 0x00, 0x00, 0x0f, 0xff, 0xfb, 0x80, 0xff, 0xff, 0xff,
		0x00, 0x00, 0x00, 0x3f, 0xff, 0xff, 0x80, 0x00, 0x00, 0x0f, 0xff, 0xfb, 0x80, 0xff, 0xff, 0xff,
		0x00, 0x00, 0x00, 0x3f, 0xff, 0xff, 0x80, 0x00, 0x00, 0x0f, 0xff, 0xfb, 0xc0, 0xff, 0xff, 0xff,
		0x00, 0x00, 0x00, 0x3f, 0x7f, 0xff, 0x80, 0x00, 0x00, 0x0f, 0xff, 0xff, 0xc0, 0xff, 0xff, 0xff,
		0x00, 0x00, 0x00, 0x3f, 0x7f, 0xff, 0xc0, 0x00, 0x00, 0x1f, 0xff, 0xff, 0xc0, 0xff, 0xff, 0xff,
		0x00, 0x00, 0x00, 0x3f, 0xbf, 0xff, 0xe0, 0x00, 0x00, 0x3f, 0xff, 0xff, 0xc1, 0xff, 0xff, 0xff,
		0x00, 0x00, 0x00, 0x3f, 0x9f, 0xff, 0xf0, 0x00, 0x00, 0x7f, 0xff, 0xff, 0xe1, 0xff, 0xff, 0xff,
		0x00, 0x00, 0x00, 0x7f, 0xcf, 0xff, 0xf8, 0x00, 0x00, 0xff, 0xff, 0xff, 0xe1, 0xff, 0xff, 0xff,
		0x00, 0x00, 0x00, 0x7f, 0xe7, 0xff, 0xfc, 0x00, 0x03, 0xff, 0xff, 0xff, 0xe1, 0xff, 0xff, 0xff,
		0x00, 0x00, 0x00, 0x7f, 0xc3, 0xff, 0xff, 0x00, 0x0f, 0xff, 0xff, 0xff, 0xe1, 0xff, 0xff, 0xff,
		0x00, 0x00, 0x00, 0x7f, 0xf1, 0xff, 0xff, 0xf0, 0xff, 0xff, 0xff, 0xff, 0xf3, 0xff, 0xff, 0xff,
		0x00, 0x00, 0x00, 0x7f, 0xf8, 0x7f, 0xff, 0xff, 0xff, 0xff, 0xff, 0xff, 0xf3, 0xff, 0xff, 0xff,
		0x00, 0x00, 0x00, 0x7f, 0xf8, 0x1f, 0xff, 0xff, 0xff, 0xff, 0xff, 0xff, 0xf3, 0xff, 0xff, 0xff,
		0x00, 0x00, 0x00, 0x7f, 0xff, 0x01, 0xff, 0xff, 0xff, 0xff, 0xff, 0xff, 0xf3, 0xff, 0xff, 0xff,
		0x00, 0x00, 0x00, 0x7f, 0xff, 0xc0, 0x00, 0x00, 0x00, 0x3f, 0xff, 0xff, 0xff, 0xff, 0xff, 0xff,
		0x00, 0x00, 0x00, 0x7f, 0xff, 0xff, 0xff, 0x87, 0xff, 0xff, 0xff, 0xff, 0xff, 0xff, 0xff, 0xff,
		0x00, 0x00, 0x00, 0x7f, 0xff, 0xff, 0xff, 0xff, 0xff, 0xff, 0xff, 0xff, 0xff, 0xff, 0xff, 0xff,
		0x00, 0x00, 0x00, 0x7f, 0xff, 0xff, 0xff, 0xff, 0xff, 0xff, 0xff, 0xff, 0xff, 0xff, 0xff, 0xff,
		0x00, 0x00, 0x00, 0x7f, 0xff, 0xff, 0xff, 0xff, 0xff, 0xff, 0xff, 0xff, 0xff, 0xff, 0xff, 0xff,
		0x00, 0x00, 0x00, 0x7f, 0xff, 0xff, 0xff, 0xff, 0xff, 0xff, 0xff, 0xff, 0xff, 0xff, 0xff, 0xff,
		0x00, 0x00, 0x00, 0xff, 0xff, 0xff, 0xff, 0xff, 0xff, 0xff, 0xff, 0xff, 0xff, 0xff, 0xff, 0xff,
		0x00, 0x00, 0x00, 0xff, 0xff, 0xff, 0xff, 0xff, 0xff, 0xff, 0xff, 0xff, 0xff, 0xff, 0xff, 0xff,
		0x00, 0x00, 0x00, 0xff, 0xff, 0xff, 0xff, 0xff, 0xff, 0xff, 0xff, 0xff, 0xff, 0xff, 0xff, 0xff,
		0x00, 0x00, 0x00, 0xff, 0xff, 0xff, 0xff, 0xff, 0xff, 0xff, 0xff, 0xff, 0xff, 0xff, 0xff, 0xff,
		0x00, 0x00, 0x00, 0xff, 0xff, 0xff, 0xff, 0xff, 0xff, 0xff, 0xff, 0xff, 0xff, 0xff, 0xff, 0xff,
		0x00, 0x00, 0x00, 0xff, 0xff, 0xff, 0xff, 0xff, 0xff, 0xff, 0xff, 0xff, 0xff, 0xff, 0xff, 0xff,
		0x00, 0x00, 0x01, 0xff, 0xff, 0xff, 0xff, 0xff, 0xff, 0xff, 0xff, 0xff, 0xff, 0xff, 0xff, 0xff,
		0x00, 0x00, 0x00, 0xff, 0xff, 0xff, 0xff, 0xff, 0xff, 0xff, 0xff, 0xff, 0xff, 0xff, 0xff, 0xff,
		0x00, 0x00, 0x00, 0xff, 0xff, 0xff, 0xff, 0xff, 0xff, 0xff, 0xff, 0xff, 0xff, 0xff, 0xff, 0xff,
		0x00, 0x00, 0x00, 0xff, 0xff, 0xff, 0xff, 0xff, 0xff, 0xff, 0xff, 0xff, 0xff, 0xff, 0xff, 0xff,
		0x00, 0x00, 0x00, 0xff, 0xff, 0xff, 0xff, 0xff, 0xff, 0xff, 0xff, 0xff, 0xff, 0xff, 0xff, 0xff,
		0x00, 0x00, 0x01, 0xff, 0xff, 0xff, 0xff, 0xff, 0xff, 0xff, 0xff, 0xff, 0xff, 0xff, 0xff, 0xff
	};
	// 'frame13', 128x64px
	const unsigned char epd_bitmap_frame13 []  = {
		0x00, 0x00, 0x00, 0x07, 0xff, 0xff, 0xc0, 0x01, 0xff, 0xff, 0xff, 0xc0, 0x00, 0x0f, 0xff, 0xff,
		0x00, 0x00, 0x00, 0x07, 0xff, 0xff, 0xe0, 0x00, 0x1f, 0xff, 0xff, 0xc0, 0x00, 0x0f, 0xff, 0xff,
		0x00, 0x00, 0x00, 0x07, 0xff, 0xff, 0xe0, 0x04, 0x03, 0xff, 0xff, 0x80, 0x00, 0x0f, 0xff, 0xff,
		0x00, 0x00, 0x00, 0x03, 0xff, 0xff, 0xe0, 0x07, 0x80, 0xff, 0xff, 0xc0, 0x00, 0x0f, 0xff, 0xff,
		0x00, 0x00, 0x00, 0x0f, 0xff, 0xff, 0xe0, 0x07, 0xf0, 0x1f, 0xff, 0xc0, 0x00, 0x1f, 0xff, 0xff,
		0x00, 0x00, 0x00, 0x0f, 0xff, 0xff, 0xe0, 0x0f, 0xfc, 0x03, 0xff, 0xc0, 0x00, 0x1f, 0xff, 0xff,
		0x00, 0x00, 0x00, 0x07, 0xff, 0xff, 0xe0, 0x0f, 0xff, 0x80, 0xff, 0xc0, 0x00, 0x1f, 0xff, 0xff,
		0x00, 0x00, 0x00, 0x07, 0xff, 0xff, 0xe0, 0x0f, 0xff, 0xe0, 0x1f, 0xe0, 0x00, 0x0f, 0xff, 0xff,
		0x00, 0x00, 0x00, 0x07, 0xff, 0xff, 0xf0, 0x0f, 0xff, 0xfc, 0x07, 0xe0, 0x00, 0x1f, 0xff, 0xff,
		0x00, 0x00, 0x00, 0x07, 0xff, 0xff, 0xc0, 0x00, 0x1f, 0xff, 0x01, 0xe0, 0x00, 0x1f, 0xff, 0xff,
		0x00, 0x00, 0x40, 0x07, 0xff, 0xf0, 0x00, 0x00, 0x00, 0xff, 0xc0, 0x60, 0x00, 0x1f, 0xff, 0xff,
		0x00, 0x00, 0x10, 0x07, 0xfe, 0x00, 0x00, 0x1f, 0x00, 0x1f, 0xf0, 0x00, 0x00, 0x0f, 0xff, 0xff,
		0x00, 0x00, 0x0c, 0x07, 0xf0, 0x07, 0xf0, 0x1f, 0xfe, 0x07, 0xfe, 0x00, 0x00, 0x0f, 0xff, 0xff,
		0x00, 0x00, 0x00, 0x07, 0x80, 0x7f, 0xf0, 0x3f, 0xff, 0xe0, 0xff, 0x80, 0x00, 0x1f, 0xff, 0xff,
		0x00, 0x00, 0x00, 0x00, 0x03, 0xff, 0xf0, 0x3f, 0xff, 0xfc, 0x7f, 0xe0, 0x00, 0x1f, 0xff, 0xff,
		0x00, 0x00, 0x00, 0x00, 0x1f, 0xff, 0xf8, 0x3f, 0xff, 0xfe, 0x1f, 0xf0, 0x00, 0x3f, 0xff, 0xff,
		0x00, 0x00, 0x00, 0x00, 0xff, 0xff, 0xf8, 0x20, 0x0f, 0xff, 0x8f, 0xf8, 0x00, 0x1f, 0xff, 0xff,
		0x00, 0x00, 0x00, 0x07, 0xff, 0xff, 0xf8, 0x00, 0x01, 0xff, 0xe3, 0xf8, 0x00, 0x1f, 0xff, 0xff,
		0x00, 0x00, 0x00, 0x0f, 0xff, 0xff, 0xf8, 0x00, 0x00, 0xff, 0xf1, 0xf8, 0x00, 0x1f, 0xff, 0xff,
		0x00, 0x00, 0x00, 0x0f, 0xff, 0xff, 0xf8, 0x00, 0x00, 0x7f, 0xf8, 0xfc, 0x00, 0x00, 0xff, 0xff,
		0x00, 0x00, 0x00, 0x0f, 0xff, 0xff, 0xf0, 0x00, 0x00, 0x3f, 0xfc, 0x7c, 0x00, 0x03, 0xff, 0xff,
		0x00, 0x00, 0x00, 0x0f, 0xff, 0xff, 0xe0, 0x00, 0x00, 0x1f, 0xfe, 0x3c, 0x00, 0x1f, 0xff, 0xff,
		0x00, 0x00, 0x00, 0x0f, 0xff, 0xff, 0xc0, 0x00, 0x00, 0x0f, 0xff, 0x1e, 0x00, 0x3f, 0xff, 0xff,
		0x00, 0x00, 0x00, 0x1f, 0xff, 0xff, 0xc0, 0x00, 0x00, 0x0f, 0xff, 0x1e, 0x00, 0x3f, 0xff, 0xff,
		0x00, 0x00, 0x00, 0x1f, 0xff, 0xff, 0x80, 0x00, 0x00, 0x07, 0xff, 0x8e, 0x00, 0x3f, 0xff, 0xff,
		0x00, 0x00, 0x00, 0x1f, 0xff, 0xff, 0x80, 0x00, 0x00, 0x07, 0xff, 0xc6, 0x00, 0x7f, 0xff, 0xff,
		0x00, 0x00, 0x00, 0x1f, 0xff, 0xff, 0x00, 0x00, 0x00, 0x07, 0xff, 0xc3, 0x00, 0x7f, 0xff, 0xff,
		0x00, 0x00, 0x00, 0x0f, 0xff, 0xff, 0x00, 0x00, 0x00, 0x07, 0xff, 0xe3, 0x00, 0x7f, 0xff, 0xff,
		0x00, 0x00, 0x00, 0x0f, 0xff, 0xff, 0x00, 0x00, 0x00, 0x07, 0xff, 0xe5, 0x00, 0x7f, 0xff, 0xff,
		0x00, 0x00, 0x00, 0x1f, 0xff, 0xff, 0x00, 0x00, 0x00, 0x07, 0xff, 0xf5, 0x00, 0x7f, 0xff, 0xff,
		0x00, 0x00, 0x00, 0x1f, 0xff, 0xff, 0x00, 0x00, 0x00, 0x0f, 0xff, 0xf6, 0x00, 0x7f, 0xff, 0xff,
		0x00, 0x00, 0x00, 0x1f, 0xff, 0xff, 0x00, 0x00, 0x00, 0x3f, 0xff, 0xfb, 0x00, 0xff, 0xff, 0xff,
		0x00, 0x00, 0x00, 0x1f, 0xff, 0xff, 0x80, 0x00, 0x00, 0x07, 0xff, 0xfb, 0x80, 0xff, 0xff, 0xff,
		0x00, 0x00, 0x00, 0x1f, 0xff, 0xff, 0x80, 0x00, 0x00, 0x07, 0xff, 0xff, 0x80, 0xff, 0xff, 0xff,
		0x00, 0x00, 0x00, 0x1f, 0xff, 0xff, 0x80, 0x00, 0x00, 0x0f, 0xff, 0xff, 0x80, 0xff, 0xff, 0xff,
		0x00, 0x00, 0x00, 0x3f, 0x7f, 0xff, 0xc0, 0x00, 0x00, 0x0f, 0xff, 0xff, 0xc0, 0xff, 0xff, 0xff,
		0x00, 0x00, 0x00, 0x3f, 0xbf, 0xff, 0xc0, 0x00, 0x00, 0x1f, 0xff, 0xff, 0xc0, 0xff, 0xff, 0xff,
		0x00, 0x00, 0x00, 0x3f, 0x9f, 0xff, 0xe0, 0x00, 0x00, 0x3f, 0xff, 0xff, 0xc1, 0xff, 0xff, 0xff,
		0x00, 0x00, 0x00, 0x3f, 0xcf, 0xff, 0xf0, 0x00, 0x00, 0x7f, 0xff, 0xff, 0xc1, 0xff, 0xff, 0xff,
		0x00, 0x00, 0x00, 0x3f, 0xc7, 0xff, 0xf8, 0x00, 0x00, 0xff, 0xff, 0xff, 0xc1, 0xff, 0xff, 0xff,
		0x00, 0x00, 0x00, 0x3f, 0xc3, 0xff, 0xfe, 0x00, 0x03, 0xff, 0xff, 0xff, 0xe1, 0xff, 0xff, 0xff,
		0x00, 0x00, 0x00, 0x3f, 0xc1, 0xff, 0xff, 0xc0, 0x0f, 0xff, 0xff, 0xff, 0xe3, 0xff, 0xff, 0xff,
		0x00, 0x00, 0x00, 0x3f, 0xf0, 0xff, 0xff, 0xff, 0xff, 0xff, 0xff, 0xff, 0xe3, 0xff, 0xff, 0xff,
		0x00, 0x00, 0x00, 0x3f, 0xf8, 0x3f, 0xff, 0xff, 0xff, 0xff, 0xff, 0xff, 0xe3, 0xff, 0xff, 0xff,
		0x00, 0x00, 0x00, 0x3f, 0xf8, 0x03, 0xff, 0xff, 0xff, 0xff, 0xff, 0xff, 0xf3, 0xff, 0xff, 0xff,
		0x00, 0x00, 0x00, 0x3f, 0xff, 0xc0, 0x07, 0xff, 0xff, 0xff, 0xff, 0xff, 0xf7, 0xff, 0xff, 0xff,
		0x00, 0x00, 0x00, 0x3f, 0xff, 0xe4, 0x00, 0x00, 0x00, 0x3f, 0xff, 0xff, 0xff, 0xff, 0xff, 0xff,
		0x00, 0x00, 0x00, 0x3f, 0xff, 0xff, 0xff, 0xff, 0xff, 0xff, 0xff, 0xff, 0xff, 0xff, 0xff, 0xff,
		0x00, 0x00, 0x00, 0x3f, 0xff, 0xff, 0xff, 0xff, 0xff, 0xff, 0xff, 0xff, 0xff, 0xff, 0xff, 0xff,
		0x00, 0x00, 0x00, 0x7f, 0xff, 0xff, 0xff, 0xff, 0xff, 0xff, 0xff, 0xff, 0xff, 0xff, 0xff, 0xff,
		0x00, 0x00, 0x00, 0x7f, 0xff, 0xff, 0xff, 0xff, 0xff, 0xff, 0xff, 0xff, 0xff, 0xff, 0xff, 0xff,
		0x00, 0x00, 0x00, 0x7f, 0xff, 0xff, 0xff, 0xff, 0xff, 0xff, 0xff, 0xff, 0xff, 0xff, 0xff, 0xff,
		0x00, 0x00, 0x00, 0xff, 0xff, 0xff, 0xff, 0xff, 0xff, 0xff, 0xff, 0xff, 0xff, 0xff, 0xff, 0xff,
		0x00, 0x00, 0x00, 0x7f, 0xff, 0xff, 0xff, 0xff, 0xff, 0xff, 0xff, 0xff, 0xff, 0xff, 0xff, 0xff,
		0x00, 0x00, 0x00, 0x7f, 0xff, 0xff, 0xff, 0xff, 0xff, 0xff, 0xff, 0xff, 0xff, 0xff, 0xff, 0xff,
		0x00, 0x00, 0x00, 0x7f, 0xff, 0xff, 0xff, 0xff, 0xff, 0xff, 0xff, 0xff, 0xff, 0xff, 0xff, 0xff,
		0x00, 0x00, 0x00, 0x7f, 0xff, 0xff, 0xff, 0xff, 0xff, 0xff, 0xff, 0xff, 0xff, 0xff, 0xff, 0xff,
		0x00, 0x00, 0x00, 0xff, 0xff, 0xff, 0xff, 0xff, 0xff, 0xff, 0xff, 0xff, 0xff, 0xff, 0xff, 0xff,
		0x00, 0x00, 0x00, 0x7f, 0xff, 0xff, 0xff, 0xff, 0xff, 0xff, 0xff, 0xff, 0xff, 0xff, 0xff, 0xff,
		0x00, 0x00, 0x00, 0x7f, 0xff, 0xff, 0xff, 0xff, 0xff, 0xff, 0xff, 0xff, 0xff, 0xff, 0xff, 0xff,
		0x00, 0x00, 0x00, 0xff, 0xff, 0xff, 0xff, 0xff, 0xff, 0xff, 0xff, 0xff, 0xff, 0xff, 0xff, 0xff,
		0x00, 0x00, 0x00, 0xff, 0xff, 0xff, 0xff, 0xff, 0xff, 0xff, 0xff, 0xff, 0xff, 0xff, 0xff, 0xff,
		0x00, 0x00, 0x00, 0xff, 0xff, 0xff, 0xff, 0xff, 0xff, 0xff, 0xff, 0xff, 0xff, 0xff, 0xff, 0xff,
		0x00, 0x00, 0x00, 0x7f, 0xff, 0xff, 0xff, 0xff, 0xff, 0xff, 0xff, 0xff, 0xff, 0xff, 0xff, 0xff
	};
	// 'frame14', 128x64px
	const unsigned char epd_bitmap_frame14 []  = {
		0x00, 0x00, 0x00, 0x01, 0xff, 0xff, 0xe0, 0x00, 0x0f, 0xff, 0xff, 0xe0, 0x00, 0x01, 0xff, 0xff,
		0x00, 0x00, 0x00, 0x03, 0xff, 0xff, 0xf0, 0x02, 0x03, 0xff, 0xff, 0xf8, 0x00, 0x03, 0xff, 0xff,
		0x00, 0x00, 0x00, 0x07, 0xff, 0xff, 0xf0, 0x03, 0xc0, 0x7f, 0xff, 0xf8, 0x00, 0x03, 0xff, 0xff,
		0x00, 0x00, 0x00, 0x03, 0xff, 0xff, 0xf0, 0x03, 0xf8, 0x0f, 0xff, 0xf8, 0x00, 0x03, 0xff, 0xff,
		0x00, 0x00, 0x00, 0x03, 0xff, 0xff, 0xf0, 0x07, 0xfe, 0x01, 0xff, 0xf8, 0x00, 0x03, 0xff, 0xff,
		0x00, 0x00, 0x00, 0x03, 0xff, 0xff, 0xf0, 0x07, 0xff, 0xc0, 0x7f, 0xf0, 0x00, 0x03, 0xff, 0xff,
		0x00, 0x00, 0x00, 0x07, 0xff, 0xff, 0xf0, 0x07, 0xff, 0xf8, 0x0f, 0xf8, 0x00, 0x07, 0xff, 0xff,
		0x00, 0x00, 0x00, 0x03, 0xff, 0xff, 0xf0, 0x07, 0xff, 0xff, 0x01, 0xf8, 0x00, 0x03, 0xff, 0xff,
		0x00, 0x00, 0x00, 0x03, 0xff, 0xff, 0xf0, 0x00, 0x1f, 0xff, 0xc0, 0x78, 0x00, 0x03, 0xff, 0xff,
		0x00, 0x00, 0x00, 0x07, 0xff, 0xfc, 0x00, 0x00, 0x00, 0x7f, 0xe0, 0x08, 0x00, 0x03, 0xff, 0xff,
		0x00, 0x00, 0x00, 0x07, 0xff, 0xc0, 0x00, 0x0f, 0x80, 0x0f, 0xfc, 0x00, 0x00, 0x03, 0xff, 0xff,
		0x00, 0x00, 0x00, 0x07, 0xfc, 0x01, 0xf8, 0x0f, 0xff, 0x03, 0xff, 0x00, 0x00, 0x07, 0xff, 0xff,
		0x00, 0x00, 0x00, 0x07, 0xe0, 0x1f, 0xf8, 0x1f, 0xff, 0xf0, 0x7f, 0xc0, 0x00, 0x07, 0xff, 0xff,
		0x00, 0x00, 0x00, 0x07, 0x01, 0xff, 0xf8, 0x1f, 0xff, 0xfe, 0x1f, 0xf8, 0x00, 0x07, 0xff, 0xff,
		0x00, 0x00, 0x00, 0x00, 0x0f, 0xff, 0xf8, 0x1f, 0xff, 0xff, 0x8f, 0xfc, 0x00, 0x07, 0xff, 0xff,
		0x00, 0x00, 0x00, 0x00, 0x7f, 0xff, 0xf8, 0x1e, 0x3f, 0xff, 0xc3, 0xfe, 0x00, 0x07, 0xff, 0xff,
		0x00, 0x00, 0x00, 0x01, 0xff, 0xff, 0xfc, 0x00, 0x03, 0xff, 0xf1, 0xfe, 0x00, 0x0f, 0xff, 0xff,
		0x00, 0x00, 0x00, 0x07, 0xff, 0xff, 0xfc, 0x00, 0x00, 0xff, 0xf8, 0xfe, 0x00, 0x0f, 0xff, 0xff,
		0x00, 0x00, 0x00, 0x0f, 0xff, 0xff, 0xfc, 0x00, 0x00, 0x3f, 0xfc, 0x7f, 0x00, 0x00, 0x7f, 0xff,
		0x00, 0x00, 0x00, 0x0f, 0xff, 0xff, 0xfc, 0x00, 0x00, 0x1f, 0xfe, 0x3f, 0x00, 0x00, 0xff, 0xff,
		0x00, 0x00, 0x00, 0x0f, 0xff, 0xff, 0xf8, 0x00, 0x00, 0x0f, 0xff, 0x1f, 0x00, 0x03, 0xff, 0xff,
		0x00, 0x00, 0x00, 0x0f, 0xff, 0xff, 0xf0, 0x00, 0x00, 0x07, 0xff, 0x8f, 0x80, 0x0f, 0xff, 0xff,
		0x00, 0x00, 0x00, 0x0f, 0xff, 0xff, 0xe0, 0x00, 0x00, 0x07, 0xff, 0xc7, 0x80, 0x0f, 0xff, 0xff,
		0x00, 0x00, 0x00, 0x0f, 0xff, 0xff, 0xe0, 0x00, 0x00, 0x03, 0xff, 0xc7, 0x80, 0x0f, 0xff, 0xff,
		0x00, 0x00, 0x00, 0x0f, 0xff, 0xff, 0xc0, 0x00, 0x00, 0x03, 0xff, 0xe3, 0x80, 0x0f, 0xff, 0xff,
		0x00, 0x00, 0x00, 0x0f, 0xff, 0xff, 0xc0, 0x00, 0x00, 0x01, 0xff, 0xf1, 0xc0, 0x1f, 0xff, 0xff,
		0x00, 0x00, 0x00, 0x0f, 0xff, 0xff, 0x80, 0x00, 0x00, 0x01, 0xff, 0xf1, 0xc0, 0x1f, 0xff, 0xff,
		0x00, 0x00, 0x00, 0x0f, 0xff, 0xff, 0x80, 0x00, 0x00, 0x01, 0xff, 0xfa, 0xc0, 0x1f, 0xff, 0xff,
		0x00, 0x00, 0x00, 0x1f, 0xff, 0xff, 0x80, 0x00, 0x00, 0x01, 0xff, 0xf9, 0xc0, 0x3f, 0xff, 0xff,
		0x00, 0x00, 0x00, 0x1f, 0xff, 0xff, 0x80, 0x00, 0x00, 0x01, 0xff, 0xfd, 0xe0, 0x3f, 0xff, 0xff,
		0x00, 0x00, 0x00, 0x1f, 0xff, 0xff, 0x80, 0x00, 0x00, 0x1f, 0xff, 0xfd, 0xe0, 0x3f, 0xff, 0xff,
		0x00, 0x00, 0x00, 0x1f, 0xff, 0xff, 0x80, 0x00, 0x00, 0x0f, 0xff, 0xfd, 0xe0, 0x3f, 0xff, 0xff,
		0x00, 0x00, 0x00, 0x1f, 0xff, 0xff, 0xc0, 0x00, 0x00, 0x03, 0xff, 0xfe, 0xe0, 0x3f, 0xff, 0xff,
		0x00, 0x00, 0x00, 0x1f, 0xff, 0xff, 0xc0, 0x00, 0x00, 0x03, 0xff, 0xfe, 0xf0, 0x7f, 0xff, 0xff,
		0x00, 0x00, 0x00, 0x1f, 0xff, 0xff, 0xc0, 0x00, 0x00, 0x03, 0xff, 0xff, 0xf0, 0x7f, 0xff, 0xff,
		0x00, 0x00, 0x00, 0x1f, 0xbf, 0xff, 0xe0, 0x00, 0x00, 0x07, 0xff, 0xff, 0xf0, 0x3f, 0xff, 0xff,
		0x00, 0x00, 0x00, 0x1f, 0x9f, 0xff, 0xf0, 0x00, 0x00, 0x0f, 0xff, 0xff, 0xf0, 0x3f, 0xff, 0xff,
		0x00, 0x00, 0x00, 0x1f, 0xcf, 0xff, 0xf8, 0x00, 0x00, 0x1f, 0xff, 0xff, 0xf0, 0x7f, 0xff, 0xff,
		0x00, 0x00, 0x00, 0x1f, 0xe7, 0xff, 0xfc, 0x00, 0x00, 0x3f, 0xff, 0xff, 0xf8, 0x7f, 0xff, 0xff,
		0x00, 0x00, 0x00, 0x3f, 0xe7, 0xff, 0xfe, 0x00, 0x00, 0x7f, 0xff, 0xff, 0xf8, 0x7f, 0xff, 0xff,
		0x00, 0x00, 0x00, 0x3f, 0xf1, 0xff, 0xff, 0x80, 0x01, 0xff, 0xff, 0xff, 0xf8, 0x7f, 0xff, 0xff,
		0x00, 0x00, 0x00, 0x3f, 0xe0, 0xff, 0xff, 0xe0, 0x0f, 0xff, 0xff, 0xff, 0xf8, 0x7f, 0xff, 0xff,
		0x00, 0x00, 0x00, 0x3f, 0xf8, 0x7f, 0xff, 0xff, 0xff, 0xff, 0xff, 0xff, 0xfc, 0xff, 0xff, 0xff,
		0x00, 0x00, 0x00, 0x3f, 0xfc, 0x3f, 0xff, 0xff, 0xff, 0xff, 0xff, 0xff, 0xff, 0xff, 0xff, 0xff,
		0x00, 0x00, 0x00, 0x3f, 0xfe, 0x03, 0xff, 0xff, 0xff, 0xff, 0xff, 0xff, 0xfd, 0xff, 0xff, 0xff,
		0x00, 0x00, 0x00, 0x3f, 0xff, 0xc0, 0x01, 0xff, 0xff, 0xff, 0xff, 0xff, 0xff, 0xff, 0xff, 0xff,
		0x00, 0x00, 0x00, 0x3f, 0xff, 0xe0, 0x00, 0x00, 0x01, 0xff, 0xff, 0xff, 0xff, 0xff, 0xff, 0xff,
		0x00, 0x00, 0x00, 0x3f, 0xff, 0xff, 0xff, 0xff, 0xff, 0xff, 0xff, 0xff, 0xff, 0xff, 0xff, 0xff,
		0x00, 0x00, 0x00, 0x7f, 0xff, 0xff, 0xff, 0xff, 0xff, 0xff, 0xff, 0xff, 0xff, 0xff, 0xff, 0xff,
		0x00, 0x00, 0x00, 0x7f, 0xff, 0xff, 0xff, 0xff, 0xff, 0xff, 0xff, 0xff, 0xff, 0xff, 0xff, 0xff,
		0x00, 0x00, 0x00, 0x7f, 0xff, 0xff, 0xff, 0xff, 0xff, 0xff, 0xff, 0xff, 0xff, 0xff, 0xff, 0xff,
		0x00, 0x00, 0x00, 0x7f, 0xff, 0xff, 0xff, 0xff, 0xff, 0xff, 0xff, 0xff, 0xff, 0xff, 0xff, 0xff,
		0x00, 0x00, 0x00, 0x7f, 0xff, 0xff, 0xff, 0xff, 0xff, 0xff, 0xff, 0xff, 0xff, 0xff, 0xff, 0xff,
		0x00, 0x00, 0x00, 0x7f, 0xff, 0xff, 0xff, 0xff, 0xff, 0xff, 0xff, 0xff, 0xff, 0xff, 0xff, 0xff,
		0x00, 0x00, 0x00, 0x7f, 0xff, 0xff, 0xff, 0xff, 0xff, 0xff, 0xff, 0xff, 0xff, 0xff, 0xff, 0xff,
		0x00, 0x00, 0x00, 0x7f, 0xff, 0xff, 0xff, 0xff, 0xff, 0xff, 0xff, 0xff, 0xff, 0xff, 0xff, 0xff,
		0x00, 0x00, 0x00, 0xff, 0xff, 0xff, 0xff, 0xff, 0xff, 0xff, 0xff, 0xff, 0xff, 0xff, 0xff, 0xff,
		0x00, 0x00, 0x00, 0x7f, 0xff, 0xff, 0xff, 0xff, 0xff, 0xff, 0xff, 0xff, 0xff, 0xff, 0xff, 0xff,
		0x00, 0x00, 0x00, 0xff, 0xff, 0xff, 0xff, 0xff, 0xff, 0xff, 0xff, 0xff, 0xff, 0xff, 0xff, 0xff,
		0x00, 0x00, 0x00, 0x7f, 0xff, 0xff, 0xff, 0xff, 0xff, 0xff, 0xff, 0xff, 0xff, 0xff, 0xff, 0xff,
		0x00, 0x00, 0x00, 0xff, 0xff, 0xff, 0xff, 0xff, 0xff, 0xff, 0xff, 0xff, 0xff, 0xff, 0xff, 0xff,
		0x00, 0x00, 0x00, 0x7f, 0xff, 0xff, 0xff, 0xff, 0xff, 0xff, 0xff, 0xff, 0xff, 0xff, 0xff, 0xff,
		0x00, 0x00, 0x00, 0x7f, 0xff, 0xff, 0xff, 0xff, 0xff, 0xff, 0xff, 0xff, 0xff, 0xff, 0xff, 0xff,
		0x00, 0x00, 0x00, 0x7f, 0xff, 0xff, 0xff, 0xff, 0xff, 0xff, 0xff, 0xff, 0xff, 0xff, 0xff, 0xff
	};
	// 'frame15', 128x64px
	const unsigned char epd_bitmap_frame15 []  = {
		0x00, 0x00, 0x00, 0x03, 0xff, 0xff, 0xf0, 0x03, 0x80, 0xff, 0xff, 0xf8, 0x00, 0x00, 0xff, 0xff,
		0x00, 0x00, 0x00, 0x03, 0xff, 0xff, 0xf0, 0x03, 0xf8, 0x0f, 0xff, 0xf8, 0x00, 0x01, 0xff, 0xff,
		0x00, 0x00, 0x00, 0x03, 0xff, 0xff, 0xf0, 0x03, 0xfe, 0x03, 0xff, 0xf0, 0x00, 0x00, 0xff, 0xff,
		0x00, 0x00, 0x00, 0x03, 0xff, 0xff, 0xf0, 0x03, 0xff, 0x80, 0xff, 0xf8, 0x00, 0x00, 0xff, 0xff,
		0x00, 0x00, 0x00, 0x07, 0xff, 0xff, 0xf0, 0x07, 0xff, 0xf0, 0x1f, 0xf8, 0x00, 0x01, 0xff, 0xff,
		0x00, 0x00, 0x00, 0x07, 0xff, 0xff, 0xf0, 0x07, 0xff, 0xfe, 0x03, 0xf8, 0x00, 0x01, 0xff, 0xff,
		0x00, 0x00, 0x00, 0x03, 0xff, 0xff, 0xf0, 0x07, 0xff, 0xff, 0x80, 0x78, 0x00, 0x03, 0xff, 0xff,
		0x00, 0x00, 0x00, 0x03, 0xff, 0xff, 0xf0, 0x00, 0x03, 0xff, 0xe0, 0x1c, 0x00, 0x03, 0xff, 0xff,
		0x00, 0x00, 0x00, 0x03, 0xff, 0xf8, 0x00, 0x00, 0x00, 0x3f, 0xfc, 0x00, 0x00, 0x01, 0xff, 0xff,
		0x00, 0x00, 0x00, 0x07, 0xff, 0x80, 0x00, 0x0f, 0xf8, 0x07, 0xff, 0x00, 0x00, 0x03, 0xff, 0xff,
		0x00, 0x00, 0x00, 0x07, 0xf8, 0x01, 0xf8, 0x0f, 0xff, 0xc0, 0xff, 0xc0, 0x00, 0x03, 0xff, 0xff,
		0x00, 0x00, 0x00, 0x07, 0xc0, 0x3f, 0xf8, 0x0f, 0xff, 0xf8, 0x3f, 0xf0, 0x00, 0x03, 0xff, 0xff,
		0x00, 0x00, 0x00, 0x06, 0x01, 0xff, 0xf8, 0x1f, 0xff, 0xff, 0x1f, 0xfe, 0x00, 0x03, 0xff, 0xff,
		0x00, 0x00, 0x00, 0x00, 0x0f, 0xff, 0xf8, 0x1f, 0xff, 0xff, 0xc7, 0xfe, 0x00, 0x07, 0xff, 0xff,
		0x00, 0x00, 0x00, 0x00, 0x3f, 0xff, 0xfc, 0x1f, 0xff, 0xff, 0xe3, 0xfe, 0x00, 0x07, 0xff, 0xff,
		0x00, 0x00, 0x00, 0x01, 0xff, 0xff, 0xfc, 0x10, 0x03, 0xff, 0xf9, 0xff, 0x00, 0x07, 0xff, 0xff,
		0x00, 0x00, 0x00, 0x07, 0xff, 0xff, 0xfc, 0x00, 0x00, 0xff, 0xfc, 0x7f, 0x00, 0x00, 0xff, 0xff,
		0x00, 0x00, 0x00, 0x0f, 0xff, 0xff, 0xfc, 0x00, 0x00, 0x3f, 0xfe, 0x3f, 0x00, 0x00, 0x3f, 0xff,
		0x00, 0x00, 0x00, 0x0f, 0xff, 0xff, 0xfc, 0x00, 0x00, 0x1f, 0xff, 0x1f, 0x80, 0x00, 0xff, 0xff,
		0x00, 0x00, 0x00, 0x0f, 0xff, 0xff, 0xf8, 0x00, 0x00, 0x0f, 0xff, 0x9f, 0x80, 0x03, 0xff, 0xff,
		0x00, 0x00, 0x00, 0x0f, 0xff, 0xff, 0xf8, 0x00, 0x00, 0x07, 0xff, 0xcf, 0x80, 0x07, 0xff, 0xff,
		0x00, 0x00, 0x00, 0x0f, 0xff, 0xff, 0xf0, 0x00, 0x00, 0x03, 0xff, 0xc7, 0xc0, 0x0f, 0xff, 0xff,
		0x00, 0x00, 0x00, 0x0f, 0xff, 0xff, 0xe0, 0x00, 0x00, 0x03, 0xff, 0xe3, 0xc0, 0x07, 0xff, 0xff,
		0x00, 0x00, 0x00, 0x0f, 0xff, 0xff, 0xe0, 0x00, 0x00, 0x01, 0xff, 0xf1, 0xc0, 0x07, 0xff, 0xff,
		0x00, 0x00, 0x00, 0x0f, 0xff, 0xff, 0xc0, 0x00, 0x00, 0x01, 0xff, 0xf1, 0xe0, 0x0f, 0xff, 0xff,
		0x00, 0x00, 0x00, 0x07, 0xff, 0xff, 0xc0, 0x00, 0x00, 0x01, 0xff, 0xf8, 0xe0, 0x0f, 0xff, 0xff,
		0x00, 0x00, 0x00, 0x0f, 0xff, 0xff, 0xc0, 0x00, 0x00, 0x01, 0xff, 0xf9, 0xe0, 0x0f, 0xff, 0xff,
		0x00, 0x00, 0x00, 0x1f, 0xff, 0xff, 0x80, 0x00, 0x00, 0x01, 0xff, 0xfd, 0xe0, 0x0f, 0xff, 0xff,
		0x00, 0x00, 0x00, 0x1f, 0xff, 0xff, 0xc0, 0x00, 0x00, 0x01, 0xff, 0xff, 0xf0, 0x1f, 0xff, 0xff,
		0x00, 0x00, 0x00, 0x1f, 0xff, 0xff, 0xc0, 0x00, 0x00, 0x01, 0xff, 0xff, 0xf0, 0x1f, 0xff, 0xff,
		0x00, 0x00, 0x00, 0x1f, 0xff, 0xff, 0xc0, 0x00, 0x00, 0x1f, 0xff, 0xfe, 0xf0, 0x1f, 0xff, 0xff,
		0x00, 0x00, 0x00, 0x1f, 0xff, 0xff, 0xc0, 0x00, 0x00, 0x01, 0xff, 0xff, 0xf0, 0x1f, 0xff, 0xff,
		0x00, 0x00, 0x00, 0x1f, 0xff, 0xff, 0xc0, 0x00, 0x00, 0x01, 0xff, 0xff, 0xf0, 0x1f, 0xff, 0xff,
		0x00, 0x00, 0x00, 0x1f, 0xff, 0xff, 0xe0, 0x00, 0x00, 0x03, 0xff, 0xff, 0xf8, 0x1f, 0xff, 0xff,
		0x00, 0x00, 0x00, 0x1f, 0xbf, 0xff, 0xe0, 0x00, 0x00, 0x03, 0xff, 0xff, 0xf8, 0x1f, 0xff, 0xff,
		0x00, 0x00, 0x00, 0x1f, 0x9f, 0xff, 0xf0, 0x00, 0x00, 0x07, 0xff, 0xff, 0xf8, 0x3f, 0xff, 0xff,
		0x00, 0x00, 0x00, 0x1f, 0xcf, 0xff, 0xf8, 0x00, 0x00, 0x0f, 0xff, 0xff, 0xf8, 0x3f, 0xff, 0xff,
		0x00, 0x00, 0x00, 0x1f, 0xc7, 0xff, 0xfc, 0x00, 0x00, 0x1f, 0xff, 0xff, 0xfc, 0x3f, 0xff, 0xff,
		0x00, 0x00, 0x00, 0x1f, 0xe3, 0xff, 0xfe, 0x00, 0x00, 0x3f, 0xff, 0xff, 0xfc, 0x3f, 0xff, 0xff,
		0x00, 0x00, 0x00, 0x1f, 0xf3, 0xff, 0xff, 0x00, 0x00, 0x7f, 0xff, 0xff, 0xfc, 0x3f, 0xff, 0xff,
		0x00, 0x00, 0x00, 0x3f, 0xf1, 0xff, 0xff, 0xc0, 0x01, 0xff, 0xff, 0xff, 0xfc, 0x3f, 0xff, 0xff,
		0x00, 0x00, 0x00, 0x3f, 0xe0, 0xff, 0xff, 0xf8, 0x1f, 0xff, 0xff, 0xff, 0xfe, 0x7f, 0xff, 0xff,
		0x00, 0x00, 0x00, 0x3f, 0xfc, 0x3f, 0xff, 0xff, 0xff, 0xff, 0xff, 0xff, 0xfe, 0x7f, 0xff, 0xff,
		0x00, 0x00, 0x00, 0x3f, 0xfe, 0x1f, 0xff, 0xff, 0xff, 0xff, 0xff, 0xff, 0xfe, 0x7f, 0xff, 0xff,
		0x00, 0x00, 0x00, 0x3f, 0xfc, 0x03, 0xff, 0xff, 0xff, 0xff, 0xff, 0xff, 0xff, 0xff, 0xff, 0xff,
		0x00, 0x00, 0x00, 0x3f, 0xff, 0xe0, 0x00, 0x0f, 0xff, 0xff, 0xff, 0xff, 0xff, 0xff, 0xff, 0xff,
		0x00, 0x00, 0x00, 0x7f, 0xff, 0xf0, 0x80, 0x00, 0x00, 0xc7, 0xff, 0xff, 0xff, 0xff, 0xff, 0xff,
		0x00, 0x00, 0x00, 0x3f, 0xff, 0xff, 0xff, 0xff, 0xff, 0xff, 0xff, 0xff, 0xff, 0xff, 0xff, 0xff,
		0x00, 0x00, 0x00, 0x7f, 0xff, 0xff, 0xff, 0xff, 0xff, 0xff, 0xff, 0xff, 0xff, 0xff, 0xff, 0xff,
		0x00, 0x00, 0x00, 0x7f, 0xff, 0xff, 0xff, 0xff, 0xff, 0xff, 0xff, 0xff, 0xff, 0xff, 0xff, 0xff,
		0x00, 0x00, 0x00, 0x7f, 0xff, 0xff, 0xff, 0xff, 0xff, 0xff, 0xff, 0xff, 0xff, 0xff, 0xff, 0xff,
		0x00, 0x00, 0x00, 0x7f, 0xff, 0xff, 0xff, 0xff, 0xff, 0xff, 0xff, 0xff, 0xff, 0xff, 0xff, 0xff,
		0x00, 0x00, 0x00, 0x7f, 0xff, 0xff, 0xff, 0xff, 0xff, 0xff, 0xff, 0xff, 0xff, 0xff, 0xff, 0xff,
		0x00, 0x00, 0x10, 0x7f, 0xff, 0xff, 0xff, 0xff, 0xff, 0xff, 0xff, 0xff, 0xff, 0xff, 0xff, 0xff,
		0x00, 0x00, 0x40, 0x7f, 0xff, 0xff, 0xff, 0xff, 0xff, 0xff, 0xff, 0xff, 0xff, 0xff, 0xff, 0xff,
		0x00, 0x03, 0x00, 0xff, 0xff, 0xff, 0xff, 0xff, 0xff, 0xff, 0xff, 0xff, 0xff, 0xff, 0xff, 0xff,
		0x00, 0x0c, 0x00, 0x7f, 0xff, 0xff, 0xff, 0xff, 0xff, 0xff, 0xff, 0xff, 0xff, 0xff, 0xff, 0xff,
		0x00, 0x30, 0x00, 0x7f, 0xff, 0xff, 0xff, 0xff, 0xff, 0xff, 0xff, 0xff, 0xff, 0xff, 0xff, 0xff,
		0x00, 0xc0, 0x00, 0x7f, 0xff, 0xff, 0xff, 0xff, 0xff, 0xff, 0xff, 0xff, 0xff, 0xff, 0xff, 0xff,
		0x02, 0x00, 0x00, 0x7f, 0xff, 0xff, 0xff, 0xff, 0xff, 0xff, 0xff, 0xff, 0xff, 0xff, 0xff, 0xff,
		0x00, 0x00, 0x00, 0x7f, 0xff, 0xff, 0xff, 0xff, 0xff, 0xff, 0xff, 0xff, 0xff, 0xff, 0xff, 0xff,
		0x00, 0x00, 0x00, 0xff, 0xff, 0xff, 0xff, 0xff, 0xff, 0xff, 0xff, 0xff, 0xff, 0xff, 0xff, 0xff,
		0x00, 0x00, 0x00, 0xff, 0xff, 0xff, 0xff, 0xff, 0xff, 0xff, 0xff, 0xff, 0xff, 0xff, 0xff, 0xff,
		0x00, 0x00, 0x00, 0xff, 0xff, 0xff, 0xff, 0xff, 0xff, 0xff, 0xff, 0xff, 0xff, 0xff, 0xff, 0xff
	};
	// 'frame16', 128x64px
	const unsigned char epd_bitmap_frame16 []  = {
		0x00, 0x00, 0x00, 0x03, 0xff, 0xff, 0xf0, 0x03, 0x80, 0xff, 0xff, 0xf8, 0x00, 0x00, 0xff, 0xff,
		0x00, 0x00, 0x00, 0x03, 0xff, 0xff, 0xf0, 0x03, 0xf8, 0x0f, 0xff, 0xf8, 0x00, 0x01, 0xff, 0xff,
		0x00, 0x00, 0x00, 0x03, 0xff, 0xff, 0xf0, 0x03, 0xfe, 0x03, 0xff, 0xf0, 0x00, 0x00, 0xff, 0xff,
		0x00, 0x00, 0x00, 0x03, 0xff, 0xff, 0xf0, 0x03, 0xff, 0x80, 0xff, 0xf8, 0x00, 0x00, 0xff, 0xff,
		0x00, 0x00, 0x00, 0x07, 0xff, 0xff, 0xf0, 0x07, 0xff, 0xf0, 0x1f, 0xf8, 0x00, 0x01, 0xff, 0xff,
		0x00, 0x00, 0x00, 0x07, 0xff, 0xff, 0xf0, 0x07, 0xff, 0xfe, 0x03, 0xf8, 0x00, 0x01, 0xff, 0xff,
		0x00, 0x00, 0x00, 0x03, 0xff, 0xff, 0xf0, 0x07, 0xff, 0xff, 0x80, 0x78, 0x00, 0x03, 0xff, 0xff,
		0x00, 0x00, 0x00, 0x03, 0xff, 0xff, 0xf0, 0x00, 0x03, 0xff, 0xe0, 0x1c, 0x00, 0x03, 0xff, 0xff,
		0x00, 0x00, 0x00, 0x03, 0xff, 0xf8, 0x00, 0x00, 0x00, 0x3f, 0xfc, 0x00, 0x00, 0x01, 0xff, 0xff,
		0x00, 0x00, 0x00, 0x07, 0xff, 0x80, 0x00, 0x0f, 0xf8, 0x07, 0xff, 0x00, 0x00, 0x03, 0xff, 0xff,
		0x00, 0x00, 0x00, 0x07, 0xf8, 0x01, 0xf8, 0x0f, 0xff, 0xc0, 0xff, 0xc0, 0x00, 0x03, 0xff, 0xff,
		0x00, 0x00, 0x00, 0x07, 0xc0, 0x3f, 0xf8, 0x0f, 0xff, 0xf8, 0x3f, 0xf0, 0x00, 0x03, 0xff, 0xff,
		0x00, 0x00, 0x00, 0x06, 0x01, 0xff, 0xf8, 0x1f, 0xff, 0xff, 0x1f, 0xfe, 0x00, 0x03, 0xff, 0xff,
		0x00, 0x00, 0x00, 0x00, 0x0f, 0xff, 0xf8, 0x1f, 0xff, 0xff, 0xc7, 0xfe, 0x00, 0x07, 0xff, 0xff,
		0x00, 0x00, 0x00, 0x00, 0x3f, 0xff, 0xfc, 0x1f, 0xff, 0xff, 0xe3, 0xfe, 0x00, 0x07, 0xff, 0xff,
		0x00, 0x00, 0x00, 0x01, 0xff, 0xff, 0xfc, 0x10, 0x03, 0xff, 0xf9, 0xff, 0x00, 0x07, 0xff, 0xff,
		0x00, 0x00, 0x00, 0x07, 0xff, 0xff, 0xfc, 0x00, 0x00, 0xff, 0xfc, 0x7f, 0x00, 0x00, 0xff, 0xff,
		0x00, 0x00, 0x00, 0x0f, 0xff, 0xff, 0xfc, 0x00, 0x00, 0x3f, 0xfe, 0x3f, 0x00, 0x00, 0x3f, 0xff,
		0x00, 0x00, 0x00, 0x0f, 0xff, 0xff, 0xfc, 0x00, 0x00, 0x1f, 0xff, 0x1f, 0x80, 0x00, 0xff, 0xff,
		0x00, 0x00, 0x00, 0x0f, 0xff, 0xff, 0xf8, 0x00, 0x00, 0x0f, 0xff, 0x9f, 0x80, 0x03, 0xff, 0xff,
		0x00, 0x00, 0x00, 0x0f, 0xff, 0xff, 0xf8, 0x00, 0x00, 0x07, 0xff, 0xcf, 0x80, 0x07, 0xff, 0xff,
		0x00, 0x00, 0x00, 0x0f, 0xff, 0xff, 0xf0, 0x00, 0x00, 0x03, 0xff, 0xc7, 0xc0, 0x0f, 0xff, 0xff,
		0x00, 0x00, 0x00, 0x0f, 0xff, 0xff, 0xe0, 0x00, 0x00, 0x03, 0xff, 0xe3, 0xc0, 0x07, 0xff, 0xff,
		0x00, 0x00, 0x00, 0x0f, 0xff, 0xff, 0xe0, 0x00, 0x00, 0x01, 0xff, 0xf1, 0xc0, 0x07, 0xff, 0xff,
		0x00, 0x00, 0x00, 0x0f, 0xff, 0xff, 0xc0, 0x00, 0x00, 0x01, 0xff, 0xf1, 0xe0, 0x0f, 0xff, 0xff,
		0x00, 0x00, 0x00, 0x07, 0xff, 0xff, 0xc0, 0x00, 0x00, 0x01, 0xff, 0xf8, 0xe0, 0x0f, 0xff, 0xff,
		0x00, 0x00, 0x00, 0x0f, 0xff, 0xff, 0xc0, 0x00, 0x00, 0x01, 0xff, 0xf9, 0xe0, 0x0f, 0xff, 0xff,
		0x00, 0x00, 0x00, 0x1f, 0xff, 0xff, 0x80, 0x00, 0x00, 0x01, 0xff, 0xfd, 0xe0, 0x0f, 0xff, 0xff,
		0x00, 0x00, 0x00, 0x1f, 0xff, 0xff, 0xc0, 0x00, 0x00, 0x01, 0xff, 0xff, 0xf0, 0x1f, 0xff, 0xff,
		0x00, 0x00, 0x00, 0x1f, 0xff, 0xff, 0xc0, 0x00, 0x00, 0x01, 0xff, 0xff, 0xf0, 0x1f, 0xff, 0xff,
		0x00, 0x00, 0x00, 0x1f, 0xff, 0xff, 0xc0, 0x00, 0x00, 0x1f, 0xff, 0xfe, 0xf0, 0x1f, 0xff, 0xff,
		0x00, 0x00, 0x00, 0x1f, 0xff, 0xff, 0xc0, 0x00, 0x00, 0x01, 0xff, 0xff, 0xf0, 0x1f, 0xff, 0xff,
		0x00, 0x00, 0x00, 0x1f, 0xff, 0xff, 0xc0, 0x00, 0x00, 0x01, 0xff, 0xff, 0xf0, 0x1f, 0xff, 0xff,
		0x00, 0x00, 0x00, 0x1f, 0xff, 0xff, 0xe0, 0x00, 0x00, 0x03, 0xff, 0xff, 0xf8, 0x1f, 0xff, 0xff,
		0x00, 0x00, 0x00, 0x1f, 0xbf, 0xff, 0xe0, 0x00, 0x00, 0x03, 0xff, 0xff, 0xf8, 0x1f, 0xff, 0xff,
		0x00, 0x00, 0x00, 0x1f, 0x9f, 0xff, 0xf0, 0x00, 0x00, 0x07, 0xff, 0xff, 0xf8, 0x3f, 0xff, 0xff,
		0x00, 0x00, 0x00, 0x1f, 0xcf, 0xff, 0xf8, 0x00, 0x00, 0x0f, 0xff, 0xff, 0xf8, 0x3f, 0xff, 0xff,
		0x00, 0x00, 0x00, 0x1f, 0xc7, 0xff, 0xfc, 0x00, 0x00, 0x1f, 0xff, 0xff, 0xfc, 0x3f, 0xff, 0xff,
		0x00, 0x00, 0x00, 0x1f, 0xe3, 0xff, 0xfe, 0x00, 0x00, 0x3f, 0xff, 0xff, 0xfc, 0x3f, 0xff, 0xff,
		0x00, 0x00, 0x00, 0x1f, 0xf3, 0xff, 0xff, 0x00, 0x00, 0x7f, 0xff, 0xff, 0xfc, 0x3f, 0xff, 0xff,
		0x00, 0x00, 0x00, 0x3f, 0xf1, 0xff, 0xff, 0xc0, 0x01, 0xff, 0xff, 0xff, 0xfc, 0x3f, 0xff, 0xff,
		0x00, 0x00, 0x00, 0x3f, 0xe0, 0xff, 0xff, 0xf8, 0x1f, 0xff, 0xff, 0xff, 0xfe, 0x7f, 0xff, 0xff,
		0x00, 0x00, 0x00, 0x3f, 0xfc, 0x3f, 0xff, 0xff, 0xff, 0xff, 0xff, 0xff, 0xfe, 0x7f, 0xff, 0xff,
		0x00, 0x00, 0x00, 0x3f, 0xfe, 0x1f, 0xff, 0xff, 0xff, 0xff, 0xff, 0xff, 0xfe, 0x7f, 0xff, 0xff,
		0x00, 0x00, 0x00, 0x3f, 0xfc, 0x03, 0xff, 0xff, 0xff, 0xff, 0xff, 0xff, 0xff, 0xff, 0xff, 0xff,
		0x00, 0x00, 0x00, 0x3f, 0xff, 0xe0, 0x00, 0x0f, 0xff, 0xff, 0xff, 0xff, 0xff, 0xff, 0xff, 0xff,
		0x00, 0x00, 0x00, 0x7f, 0xff, 0xf0, 0x80, 0x00, 0x00, 0xc7, 0xff, 0xff, 0xff, 0xff, 0xff, 0xff,
		0x00, 0x00, 0x00, 0x3f, 0xff, 0xff, 0xff, 0xff, 0xff, 0xff, 0xff, 0xff, 0xff, 0xff, 0xff, 0xff,
		0x00, 0x00, 0x00, 0x7f, 0xff, 0xff, 0xff, 0xff, 0xff, 0xff, 0xff, 0xff, 0xff, 0xff, 0xff, 0xff,
		0x00, 0x00, 0x00, 0x7f, 0xff, 0xff, 0xff, 0xff, 0xff, 0xff, 0xff, 0xff, 0xff, 0xff, 0xff, 0xff,
		0x00, 0x00, 0x00, 0x7f, 0xff, 0xff, 0xff, 0xff, 0xff, 0xff, 0xff, 0xff, 0xff, 0xff, 0xff, 0xff,
		0x00, 0x00, 0x00, 0x7f, 0xff, 0xff, 0xff, 0xff, 0xff, 0xff, 0xff, 0xff, 0xff, 0xff, 0xff, 0xff,
		0x00, 0x00, 0x00, 0x7f, 0xff, 0xff, 0xff, 0xff, 0xff, 0xff, 0xff, 0xff, 0xff, 0xff, 0xff, 0xff,
		0x00, 0x00, 0x10, 0x7f, 0xff, 0xff, 0xff, 0xff, 0xff, 0xff, 0xff, 0xff, 0xff, 0xff, 0xff, 0xff,
		0x00, 0x00, 0x40, 0x7f, 0xff, 0xff, 0xff, 0xff, 0xff, 0xff, 0xff, 0xff, 0xff, 0xff, 0xff, 0xff,
		0x00, 0x03, 0x00, 0xff, 0xff, 0xff, 0xff, 0xff, 0xff, 0xff, 0xff, 0xff, 0xff, 0xff, 0xff, 0xff,
		0x00, 0x0c, 0x00, 0x7f, 0xff, 0xff, 0xff, 0xff, 0xff, 0xff, 0xff, 0xff, 0xff, 0xff, 0xff, 0xff,
		0x00, 0x30, 0x00, 0x7f, 0xff, 0xff, 0xff, 0xff, 0xff, 0xff, 0xff, 0xff, 0xff, 0xff, 0xff, 0xff,
		0x00, 0xc0, 0x00, 0x7f, 0xff, 0xff, 0xff, 0xff, 0xff, 0xff, 0xff, 0xff, 0xff, 0xff, 0xff, 0xff,
		0x02, 0x00, 0x00, 0x7f, 0xff, 0xff, 0xff, 0xff, 0xff, 0xff, 0xff, 0xff, 0xff, 0xff, 0xff, 0xff,
		0x00, 0x00, 0x00, 0x7f, 0xff, 0xff, 0xff, 0xff, 0xff, 0xff, 0xff, 0xff, 0xff, 0xff, 0xff, 0xff,
		0x00, 0x00, 0x00, 0xff, 0xff, 0xff, 0xff, 0xff, 0xff, 0xff, 0xff, 0xff, 0xff, 0xff, 0xff, 0xff,
		0x00, 0x00, 0x00, 0xff, 0xff, 0xff, 0xff, 0xff, 0xff, 0xff, 0xff, 0xff, 0xff, 0xff, 0xff, 0xff,
		0x00, 0x00, 0x00, 0xff, 0xff, 0xff, 0xff, 0xff, 0xff, 0xff, 0xff, 0xff, 0xff, 0xff, 0xff, 0xff
	};
	// 'frame17', 128x64px
	const unsigned char epd_bitmap_frame17 []  = {
		0x00, 0x00, 0x00, 0x03, 0xff, 0xff, 0xe0, 0x03, 0x80, 0xff, 0xff, 0xe0, 0x00, 0x03, 0xff, 0xff,
		0x00, 0x00, 0x00, 0x07, 0xff, 0xff, 0xf0, 0x03, 0xe0, 0x3f, 0xff, 0xe0, 0x00, 0x03, 0xff, 0xff,
		0x00, 0x00, 0x00, 0x07, 0xff, 0xff, 0xf0, 0x07, 0xfc, 0x03, 0xff, 0xf0, 0x00, 0x03, 0xff, 0xff,
		0x00, 0x00, 0x00, 0x07, 0xff, 0xff, 0xf0, 0x07, 0xff, 0x00, 0xff, 0xf0, 0x00, 0x01, 0xff, 0xff,
		0x00, 0x00, 0x00, 0x07, 0xff, 0xff, 0xf0, 0x07, 0xff, 0xe0, 0x1f, 0xf0, 0x00, 0x03, 0xff, 0xff,
		0x00, 0x00, 0x00, 0x07, 0xff, 0xff, 0xf0, 0x07, 0xff, 0xfc, 0x07, 0xf8, 0x00, 0x03, 0xff, 0xff,
		0x00, 0x00, 0x02, 0x07, 0xff, 0xff, 0xf0, 0x07, 0xff, 0xff, 0x01, 0xf8, 0x00, 0x07, 0xff, 0xff,
		0x00, 0x10, 0x01, 0x07, 0xff, 0xff, 0x80, 0x00, 0x07, 0xff, 0xc0, 0x78, 0x00, 0x07, 0xff, 0xff,
		0x00, 0x0c, 0x00, 0x07, 0xff, 0xf0, 0x00, 0x00, 0x00, 0x3f, 0xf0, 0x08, 0x00, 0x07, 0xff, 0xff,
		0x00, 0x01, 0x00, 0x17, 0xff, 0x80, 0x30, 0x0f, 0x80, 0x07, 0xfc, 0x00, 0x00, 0x07, 0xff, 0xff,
		0x00, 0x00, 0x40, 0x0f, 0xf8, 0x0f, 0xf8, 0x0f, 0xff, 0xc0, 0xff, 0x80, 0x00, 0x0f, 0xff, 0xff,
		0x00, 0x00, 0x18, 0x07, 0x80, 0xff, 0xf8, 0x0f, 0xff, 0xf8, 0x7f, 0xe0, 0x00, 0x07, 0xff, 0xff,
		0x00, 0x00, 0x02, 0x00, 0x07, 0xff, 0xf8, 0x1f, 0xff, 0xfe, 0x1f, 0xf8, 0x00, 0x0f, 0xff, 0xff,
		0x00, 0x00, 0x00, 0x00, 0x3f, 0xff, 0xf8, 0x1f, 0xff, 0xff, 0x8f, 0xfe, 0x00, 0x1f, 0xff, 0xff,
		0x00, 0x00, 0x00, 0x00, 0x7f, 0xff, 0xfc, 0x00, 0x03, 0xff, 0xe3, 0xfe, 0x00, 0x7f, 0xff, 0xff,
		0x00, 0x00, 0x00, 0x07, 0xff, 0xff, 0xfc, 0x00, 0x00, 0xff, 0xf9, 0xff, 0x00, 0x07, 0xff, 0xff,
		0x00, 0x00, 0x00, 0x0f, 0xff, 0xff, 0xfc, 0x00, 0x00, 0x3f, 0xfc, 0xff, 0x00, 0x03, 0xff, 0xff,
		0x00, 0x00, 0x00, 0x0f, 0xff, 0xff, 0xfc, 0x00, 0x00, 0x1f, 0xfe, 0x7f, 0x00, 0x01, 0xff, 0xff,
		0x00, 0x00, 0x00, 0x0f, 0xff, 0xff, 0xf8, 0x00, 0x00, 0x0f, 0xff, 0x3f, 0x80, 0x00, 0x7f, 0xff,
		0x00, 0x00, 0x00, 0x0f, 0xff, 0xff, 0xf0, 0x00, 0x00, 0x07, 0xff, 0x9f, 0x80, 0x03, 0xff, 0xff,
		0x00, 0x00, 0x00, 0x0f, 0xff, 0xff, 0xe0, 0x00, 0x00, 0x07, 0xff, 0xcf, 0x80, 0x0f, 0xff, 0xff,
		0x00, 0x00, 0x00, 0x0f, 0xff, 0xff, 0xe0, 0x00, 0x00, 0x03, 0xff, 0xc7, 0x80, 0x0f, 0xff, 0xff,
		0x00, 0x00, 0x00, 0x0f, 0xff, 0xff, 0xc0, 0x00, 0x00, 0x03, 0xff, 0xe3, 0x80, 0x0f, 0xff, 0xff,
		0x00, 0x00, 0x00, 0x0f, 0xff, 0xff, 0x80, 0x00, 0x00, 0x03, 0xff, 0xf1, 0x80, 0x0f, 0xff, 0xff,
		0x00, 0x00, 0x00, 0x0f, 0xff, 0xff, 0x80, 0x00, 0x00, 0x01, 0xff, 0xf1, 0xc0, 0x1f, 0xff, 0xff,
		0x00, 0x00, 0x00, 0x0f, 0xff, 0xff, 0x80, 0x00, 0x00, 0x01, 0xff, 0xf0, 0xc0, 0x1f, 0xff, 0xff,
		0x00, 0x00, 0x00, 0x0f, 0xff, 0xff, 0x80, 0x00, 0x00, 0x01, 0xff, 0xf8, 0xc0, 0x1f, 0xff, 0xff,
		0x00, 0x00, 0x00, 0x1f, 0xff, 0xff, 0x80, 0x00, 0x00, 0x01, 0xff, 0xfd, 0xc0, 0x1f, 0xff, 0xff,
		0x00, 0x00, 0x00, 0x1f, 0xff, 0xff, 0x80, 0x00, 0x00, 0x01, 0xff, 0xfd, 0xc0, 0x1f, 0xff, 0xff,
		0x00, 0x00, 0x00, 0x1f, 0xff, 0xff, 0x80, 0x00, 0x00, 0x1f, 0xff, 0xfd, 0xc0, 0x1f, 0xff, 0xff,
		0x00, 0x00, 0x00, 0x1f, 0xff, 0xff, 0x80, 0x00, 0x00, 0x03, 0xff, 0xfe, 0xc0, 0x3f, 0xff, 0xff,
		0x00, 0x00, 0x00, 0x1f, 0xff, 0xff, 0x80, 0x00, 0x00, 0x03, 0xff, 0xfe, 0xe0, 0x3f, 0xff, 0xff,
		0x00, 0x00, 0x00, 0x1f, 0xff, 0xff, 0xc0, 0x00, 0x00, 0x03, 0xff, 0xff, 0xe0, 0x3f, 0xff, 0xff,
		0x00, 0x00, 0x00, 0x1f, 0x7f, 0xff, 0xc0, 0x00, 0x00, 0x03, 0xff, 0xff, 0xf0, 0x3f, 0xff, 0xff,
		0x00, 0x00, 0x00, 0x1f, 0x3f, 0xff, 0xe0, 0x00, 0x00, 0x07, 0xff, 0xff, 0xf0, 0x3f, 0xff, 0xff,
		0x00, 0x00, 0x00, 0x1f, 0x9f, 0xff, 0xe0, 0x00, 0x00, 0x0f, 0xff, 0xff, 0xf0, 0x3f, 0xff, 0xff,
		0x00, 0x00, 0x00, 0x1f, 0xdf, 0xff, 0xf0, 0x00, 0x00, 0x1f, 0xff, 0xff, 0xf0, 0x7f, 0xff, 0xff,
		0x00, 0x00, 0x00, 0x1f, 0xcf, 0xff, 0xf8, 0x00, 0x00, 0x3f, 0xff, 0xff, 0xf8, 0x7f, 0xff, 0xff,
		0x00, 0x00, 0x00, 0x1f, 0xe7, 0xff, 0xfe, 0x00, 0x00, 0x7f, 0xff, 0xff, 0xf8, 0x7f, 0xff, 0xff,
		0x00, 0x00, 0x00, 0x1f, 0xe3, 0xff, 0xff, 0x80, 0x01, 0xff, 0xff, 0xff, 0xf8, 0x7f, 0xff, 0xff,
		0x00, 0x00, 0x00, 0x1f, 0xf1, 0xff, 0xff, 0xe0, 0x0f, 0xff, 0xff, 0xff, 0xf8, 0xff, 0xff, 0xff,
		0x00, 0x00, 0x00, 0x3f, 0xf8, 0x7f, 0xff, 0xff, 0xff, 0xff, 0xff, 0xff, 0xf8, 0xff, 0xff, 0xff,
		0x00, 0x00, 0x00, 0x3f, 0xfc, 0x1f, 0xff, 0xff, 0xff, 0xff, 0xff, 0xff, 0xfc, 0xff, 0xff, 0xff,
		0x00, 0x00, 0x00, 0x3f, 0xfc, 0x03, 0xff, 0xff, 0xff, 0xff, 0xff, 0xff, 0xfd, 0xff, 0xff, 0xff,
		0x00, 0x00, 0x00, 0x3f, 0xff, 0xe0, 0x00, 0x9f, 0xff, 0xff, 0xff, 0xff, 0xff, 0xff, 0xff, 0xff,
		0x00, 0x00, 0x00, 0x3f, 0xff, 0xf6, 0x00, 0x00, 0x00, 0x3f, 0xff, 0xff, 0xff, 0xff, 0xff, 0xff,
		0x00, 0x00, 0x00, 0x3f, 0xff, 0xff, 0xff, 0xff, 0xff, 0xff, 0xff, 0xff, 0xff, 0xff, 0xff, 0xff,
		0x00, 0x00, 0x00, 0x3f, 0xff, 0xff, 0xff, 0xff, 0xff, 0xff, 0xff, 0xff, 0xff, 0xff, 0xff, 0xff,
		0x00, 0x00, 0x00, 0x3f, 0xff, 0xff, 0xff, 0xff, 0xff, 0xff, 0xff, 0xff, 0xff, 0xff, 0xff, 0xff,
		0x00, 0x00, 0x00, 0x3f, 0xff, 0xff, 0xff, 0xff, 0xff, 0xff, 0xff, 0xff, 0xff, 0xff, 0xff, 0xff,
		0x00, 0x00, 0x00, 0x7f, 0xff, 0xff, 0xff, 0xff, 0xff, 0xff, 0xff, 0xff, 0xff, 0xff, 0xff, 0xff,
		0x00, 0x00, 0x00, 0x7f, 0xff, 0xff, 0xff, 0xff, 0xff, 0xff, 0xff, 0xff, 0xff, 0xff, 0xff, 0xff,
		0x00, 0x00, 0x00, 0x7f, 0xff, 0xff, 0xff, 0xff, 0xff, 0xff, 0xff, 0xff, 0xff, 0xff, 0xff, 0xff,
		0x00, 0x00, 0x00, 0xff, 0xff, 0xff, 0xff, 0xff, 0xff, 0xff, 0xff, 0xff, 0xff, 0xff, 0xff, 0xff,
		0x00, 0x00, 0x01, 0xff, 0xff, 0xff, 0xff, 0xff, 0xff, 0xff, 0xff, 0xff, 0xff, 0xff, 0xff, 0xff,
		0x00, 0x00, 0x00, 0x3f, 0xff, 0xff, 0xff, 0xff, 0xff, 0xff, 0xff, 0xff, 0xff, 0xff, 0xff, 0xff,
		0x00, 0x00, 0x00, 0x3f, 0xff, 0xff, 0xff, 0xff, 0xff, 0xff, 0xff, 0xff, 0xff, 0xff, 0xff, 0xff,
		0x00, 0x00, 0x00, 0x3f, 0xff, 0xff, 0xff, 0xff, 0xff, 0xff, 0xff, 0xff, 0xff, 0xff, 0xff, 0xff,
		0x00, 0x00, 0x00, 0x7f, 0xff, 0xff, 0xff, 0xff, 0xff, 0xff, 0xff, 0xff, 0xff, 0xff, 0xff, 0xff,
		0x00, 0x00, 0x00, 0x7f, 0xff, 0xff, 0xff, 0xff, 0xff, 0xff, 0xff, 0xff, 0xff, 0xff, 0xff, 0xff,
		0x00, 0x00, 0x00, 0xff, 0xff, 0xff, 0xff, 0xff, 0xff, 0xff, 0xff, 0xff, 0xff, 0xff, 0xff, 0xff,
		0x00, 0x00, 0x00, 0x7f, 0xff, 0xff, 0xff, 0xff, 0xff, 0xff, 0xff, 0xff, 0xff, 0xff, 0xff, 0xff,
		0x00, 0x00, 0x00, 0x7f, 0xff, 0xff, 0xff, 0xff, 0xff, 0xff, 0xff, 0xff, 0xff, 0xff, 0xff, 0xff,
		0x00, 0x00, 0x00, 0x7f, 0xff, 0xff, 0xff, 0xff, 0xff, 0xff, 0xff, 0xff, 0xff, 0xff, 0xff, 0xff
	};

	// Array of all bitmaps for convenience. (Total bytes used to store images in  = 17680)
	const unsigned char* epd_bitmap_allArray[17] = {
		epd_bitmap_frame1,
		epd_bitmap_frame10,
		epd_bitmap_frame11,
		epd_bitmap_frame12,
		epd_bitmap_frame13,
		epd_bitmap_frame14,
		epd_bitmap_frame15,
		epd_bitmap_frame16,
		epd_bitmap_frame17,
		epd_bitmap_frame2,
		epd_bitmap_frame3,
		epd_bitmap_frame4,
		epd_bitmap_frame5,
		epd_bitmap_frame6,
		epd_bitmap_frame7,
		epd_bitmap_frame8,
		epd_bitmap_frame9
	};

  /* USER CODE END 1 */

  /* MCU Configuration--------------------------------------------------------*/

  /* Reset of all peripherals, Initializes the Flash interface and the Systick. */
  HAL_Init();

  /* Configure the system clock */
  SystemClock_Config();

  /* Initialize all configured peripherals */
  MX_GPIO_Init();
  MX_I2C1_Init();
  /* USER CODE BEGIN 2 */
  SSD1306_Init ();
  /* USER CODE END 2 */

  /* Infinite loop */
  /* USER CODE BEGIN WHILE */
  int cont = 0;
  while (1)
  {
      SSD1306_Clear();
      SSD1306_GotoXY (40,20);
      SSD1306_DrawBitmap(0, 0, epd_bitmap_allArray[cont], 128, 64, SSD1306_COLOR_WHITE);
      SSD1306_UpdateScreen();
      HAL_Delay(58);
      cont++;
      if (cont == 17) {
	  cont = 0;
      }
      /* USER CODE END WHILE */

  }
}

void SystemClock_Config(void)
{
  RCC_OscInitTypeDef RCC_OscInitStruct = {0};
  RCC_ClkInitTypeDef RCC_ClkInitStruct = {0};

  /** Configure the main internal regulator output voltage
  */
  __HAL_RCC_PWR_CLK_ENABLE();
  __HAL_PWR_VOLTAGESCALING_CONFIG(PWR_REGULATOR_VOLTAGE_SCALE3);

  /** Initializes the RCC Oscillators according to the specified parameters
  * in the RCC_OscInitTypeDef structure.
  */
  RCC_OscInitStruct.OscillatorType = RCC_OSCILLATORTYPE_HSI;
  RCC_OscInitStruct.HSIState = RCC_HSI_ON;
  RCC_OscInitStruct.HSICalibrationValue = RCC_HSICALIBRATION_DEFAULT;
  RCC_OscInitStruct.PLL.PLLState = RCC_PLL_ON;
  RCC_OscInitStruct.PLL.PLLSource = RCC_PLLSOURCE_HSI;
  RCC_OscInitStruct.PLL.PLLM = 16;
  RCC_OscInitStruct.PLL.PLLN = 336;
  RCC_OscInitStruct.PLL.PLLP = RCC_PLLP_DIV4;
  RCC_OscInitStruct.PLL.PLLQ = 2;
  RCC_OscInitStruct.PLL.PLLR = 2;
  if (HAL_RCC_OscConfig(&RCC_OscInitStruct) != HAL_OK)
  {
    Error_Handler();
  }

  /** Initializes the CPU, AHB and APB buses clocks
  */
  RCC_ClkInitStruct.ClockType = RCC_CLOCKTYPE_HCLK|RCC_CLOCKTYPE_SYSCLK
                              |RCC_CLOCKTYPE_PCLK1|RCC_CLOCKTYPE_PCLK2;
  RCC_ClkInitStruct.SYSCLKSource = RCC_SYSCLKSOURCE_PLLCLK;
  RCC_ClkInitStruct.AHBCLKDivider = RCC_SYSCLK_DIV1;
  RCC_ClkInitStruct.APB1CLKDivider = RCC_HCLK_DIV2;
  RCC_ClkInitStruct.APB2CLKDivider = RCC_HCLK_DIV1;

  if (HAL_RCC_ClockConfig(&RCC_ClkInitStruct, FLASH_LATENCY_2) != HAL_OK)
  {
    Error_Handler();
  }
}

static void MX_I2C1_Init(void)
{

  hi2c1.Instance = I2C1;
  hi2c1.Init.ClockSpeed = 400000;
  hi2c1.Init.DutyCycle = I2C_DUTYCYCLE_2;
  hi2c1.Init.OwnAddress1 = 0;
  hi2c1.Init.AddressingMode = I2C_ADDRESSINGMODE_7BIT;
  hi2c1.Init.DualAddressMode = I2C_DUALADDRESS_DISABLE;
  hi2c1.Init.OwnAddress2 = 0;
  hi2c1.Init.GeneralCallMode = I2C_GENERALCALL_DISABLE;
  hi2c1.Init.NoStretchMode = I2C_NOSTRETCH_DISABLE;
  if (HAL_I2C_Init(&hi2c1) != HAL_OK)
  {
    Error_Handler();
  }

}

static void MX_GPIO_Init(void)
{
  GPIO_InitTypeDef GPIO_InitStruct = {0};

  /* GPIO Ports Clock Enable */
  __HAL_RCC_GPIOC_CLK_ENABLE();
  __HAL_RCC_GPIOH_CLK_ENABLE();
  __HAL_RCC_GPIOA_CLK_ENABLE();
  __HAL_RCC_GPIOB_CLK_ENABLE();

  /*Configure GPIO pin Output Level */
  HAL_GPIO_WritePin(LD2_GPIO_Port, LD2_Pin, GPIO_PIN_RESET);

  /*Configure GPIO pin : B1_Pin */
  GPIO_InitStruct.Pin = B1_Pin;
  GPIO_InitStruct.Mode = GPIO_MODE_IT_FALLING;
  GPIO_InitStruct.Pull = GPIO_NOPULL;
  HAL_GPIO_Init(B1_GPIO_Port, &GPIO_InitStruct);

  /*Configure GPIO pins : USART_TX_Pin USART_RX_Pin */
  GPIO_InitStruct.Pin = USART_TX_Pin|USART_RX_Pin;
  GPIO_InitStruct.Mode = GPIO_MODE_AF_PP;
  GPIO_InitStruct.Pull = GPIO_NOPULL;
  GPIO_InitStruct.Speed = GPIO_SPEED_FREQ_VERY_HIGH;
  GPIO_InitStruct.Alternate = GPIO_AF7_USART2;
  HAL_GPIO_Init(GPIOA, &GPIO_InitStruct);

  /*Configure GPIO pin : LD2_Pin */
  GPIO_InitStruct.Pin = LD2_Pin;
  GPIO_InitStruct.Mode = GPIO_MODE_OUTPUT_PP;
  GPIO_InitStruct.Pull = GPIO_NOPULL;
  GPIO_InitStruct.Speed = GPIO_SPEED_FREQ_LOW;
  HAL_GPIO_Init(LD2_GPIO_Port, &GPIO_InitStruct);

}

void Error_Handler(void)
{
  __disable_irq();
  while (1)
  {
  }
}
